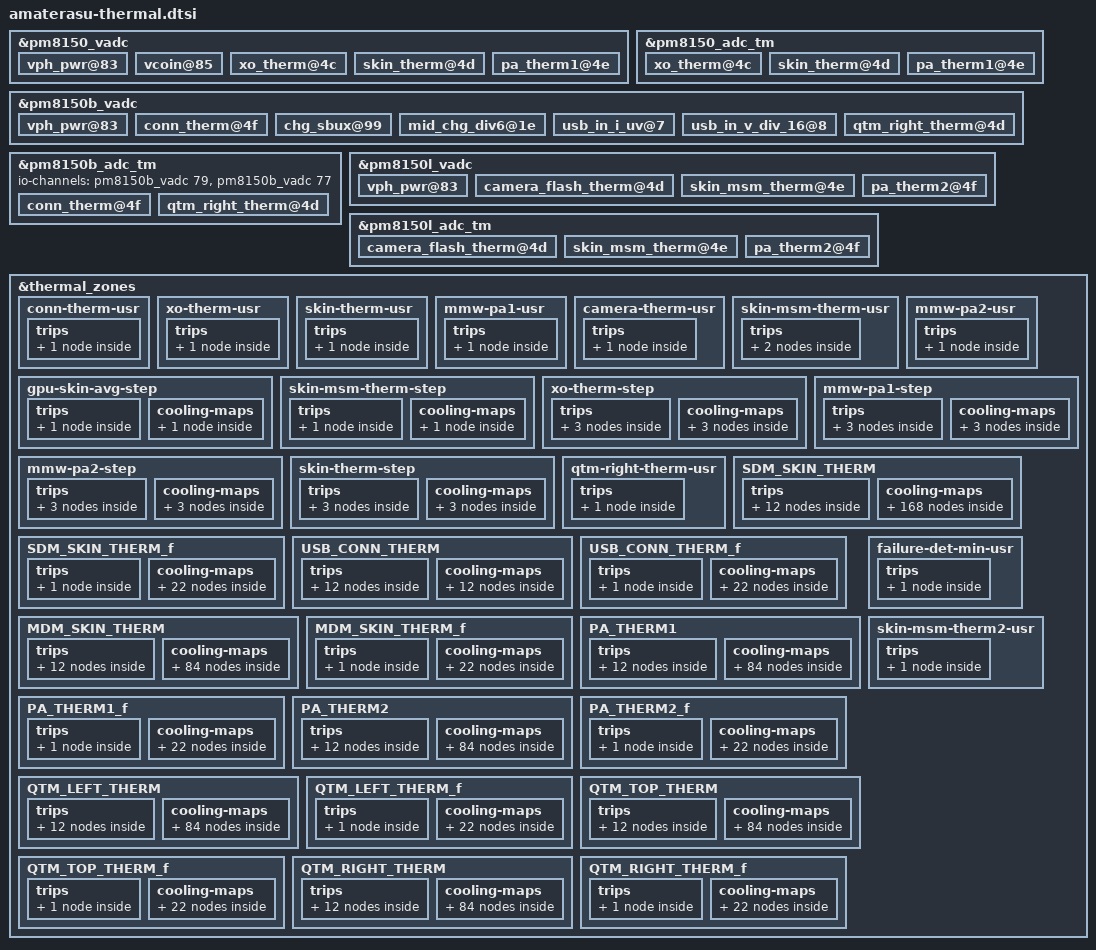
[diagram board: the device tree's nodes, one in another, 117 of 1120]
/*
 * FCNT arrows 5G (F-51A) - Thermal: ADC thermistor channels, FCNT thermal zones and mitigation.
 *
 * Reconstructed from the FCNT stock dtbo (kona FFRD REV7 SKU3); FFRD is
 * derived from the CLO kona QRD board files.
 */

&pm8150_vadc {
	vph_pwr@83 {
		reg = <0x83>;
		label = "vph_pwr";
		qcom,pre-scaling = <1 3>;
	};

	vcoin@85 {
		reg = <0x85>;
		label = "vcoin";
		qcom,pre-scaling = <1 3>;
	};

	xo_therm@4c {
		reg = <0x4c>;
		label = "xo_therm";
		qcom,ratiometric;
		qcom,hw-settle-time = <200>;
		qcom,pre-scaling = <1 1>;
	};

	skin_therm@4d {
		reg = <0x4d>;
		label = "skin_therm";
		qcom,ratiometric;
		qcom,hw-settle-time = <200>;
		qcom,pre-scaling = <1 1>;
	};

	pa_therm1@4e {
		reg = <0x4e>;
		label = "pa_therm1";
		qcom,ratiometric;
		qcom,hw-settle-time = <200>;
		qcom,pre-scaling = <1 1>;
	};
};

&pm8150_adc_tm {
	io-channels = <&pm8150_vadc 76 &pm8150_vadc 77 &pm8150_vadc 78>;

	xo_therm@4c {
		reg = <0x4c>;
		qcom,ratiometric;
		qcom,hw-settle-time = <200>;
	};

	skin_therm@4d {
		reg = <0x4d>;
		qcom,ratiometric;
		qcom,hw-settle-time = <200>;
	};

	pa_therm1@4e {
		reg = <0x4e>;
		qcom,ratiometric;
		qcom,hw-settle-time = <200>;
	};
};

&pm8150b_vadc {
	vph_pwr@83 {
		reg = <0x83>;
		label = "vph_pwr";
		qcom,pre-scaling = <1 3>;
	};

	conn_therm@4f {
		reg = <0x4f>;
		label = "conn_therm";
		qcom,ratiometric;
		qcom,hw-settle-time = <200>;
		qcom,pre-scaling = <1 1>;
	};

	chg_sbux@99 {
		reg = <0x99>;
		label = "chg_sbux";
		qcom,pre-scaling = <1 3>;
	};

	mid_chg_div6@1e {
		reg = <0x1e>;
		label = "chg_mid";
		qcom,pre-scaling = <1 6>;
	};

	usb_in_i_uv@7 {
		reg = <0x7>;
		label = "usb_in_i_uv";
		qcom,pre-scaling = <1 1>;
	};

	usb_in_v_div_16@8 {
		reg = <0x8>;
		label = "usb_in_v_div_16";
		qcom,pre-scaling = <1 16>;
	};

	qtm_right_therm@4d {
		reg = <0x4d>;
		label = "qtm_right_therm";
		qcom,ratiometric;
		qcom,hw-settle-time = <200>;
		qcom,pre-scaling = <1 1>;
	};
};

&pm8150b_adc_tm {
	io-channels = <&pm8150b_vadc 79 &pm8150b_vadc 77>;

	conn_therm@4f {
		reg = <0x4f>;
		qcom,ratiometric;
		qcom,hw-settle-time = <200>;
	};

	qtm_right_therm@4d {
		reg = <0x4d>;
		label = "qtm_right_therm";
		qcom,ratiometric;
		qcom,hw-settle-time = <200>;
	};
};

&pm8150l_vadc {
	vph_pwr@83 {
		reg = <0x83>;
		label = "vph_pwr";
		qcom,pre-scaling = <1 3>;
	};

	camera_flash_therm@4d {
		reg = <0x4d>;
		label = "camera_flash_therm";
		qcom,ratiometric;
		qcom,hw-settle-time = <200>;
		qcom,pre-scaling = <1 1>;
	};

	skin_msm_therm@4e {
		reg = <0x4e>;
		label = "skin_msm_therm";
		qcom,ratiometric;
		qcom,hw-settle-time = <200>;
		qcom,pre-scaling = <1 1>;
	};

	pa_therm2@4f {
		reg = <0x4f>;
		label = "pa_therm2";
		qcom,ratiometric;
		qcom,hw-settle-time = <200>;
		qcom,pre-scaling = <1 1>;
	};
};

&pm8150l_adc_tm {
	camera_flash_therm@4d {
		reg = <0x4d>;
		qcom,ratiometric;
		qcom,hw-settle-time = <200>;
	};

	skin_msm_therm@4e {
		reg = <0x4e>;
		qcom,ratiometric;
		qcom,hw-settle-time = <200>;
	};

	pa_therm2@4f {
		reg = <0x4f>;
		qcom,ratiometric;
		qcom,hw-settle-time = <200>;
	};
};

&thermal_zones {
	conn-therm-usr {
		polling-delay-passive = <0>;
		polling-delay = <0>;
		thermal-governor = "user_space";
		thermal-sensors = <&pm8150b_adc_tm 79>;
		wake-capable-sensor;

		trips {
			active-config0 {
				temperature = <125000>;
				hysteresis = <1000>;
				type = "passive";
			};
		};
	};

	xo-therm-usr {
		polling-delay-passive = <0>;
		polling-delay = <0>;
		thermal-governor = "user_space";
		thermal-sensors = <&pm8150_adc_tm 76>;
		wake-capable-sensor;

		trips {
			active-config0 {
				temperature = <125000>;
				hysteresis = <1000>;
				type = "passive";
			};
		};
	};

	skin-therm-usr {
		polling-delay-passive = <0>;
		polling-delay = <0>;
		thermal-governor = "user_space";
		thermal-sensors = <&pm8150_adc_tm 77>;
		wake-capable-sensor;

		trips {
			active-config0 {
				temperature = <125000>;
				hysteresis = <1000>;
				type = "passive";
			};
		};
	};

	mmw-pa1-usr {
		polling-delay-passive = <0>;
		polling-delay = <0>;
		thermal-governor = "user_space";
		thermal-sensors = <&pm8150_adc_tm 78>;
		wake-capable-sensor;

		trips {
			active-config0 {
				temperature = <125000>;
				hysteresis = <1000>;
				type = "passive";
			};
		};
	};

	camera-therm-usr {
		polling-delay-passive = <0>;
		polling-delay = <0>;
		thermal-governor = "user_space";
		thermal-sensors = <&pm8150l_adc_tm 77>;
		wake-capable-sensor;

		trips {
			active-config0 {
				temperature = <125000>;
				hysteresis = <1000>;
				type = "passive";
			};
		};
	};

	skin-msm-therm-usr {
		polling-delay-passive = <0>;
		polling-delay = <0>;
		thermal-governor = "user_space";
		thermal-sensors = <&pm8150l_adc_tm 78>;
		wake-capable-sensor;

		trips {
			active-config0 {
				temperature = <125000>;
				hysteresis = <1000>;
				type = "passive";
			};

			/* upstream a2dceb359e01: trip for the second userspace client */
			active-config1 {
				temperature = <125000>;
				hysteresis = <1000>;
				type = "passive";
			};
		};
	};

	mmw-pa2-usr {
		polling-delay-passive = <0>;
		polling-delay = <0>;
		thermal-governor = "user_space";
		thermal-sensors = <&pm8150l_adc_tm 79>;
		wake-capable-sensor;

		trips {
			active-config0 {
				temperature = <125000>;
				hysteresis = <1000>;
				type = "passive";
			};
		};
	};

	gpu-skin-avg-step {
		polling-delay-passive = <1000>;
		polling-delay = <5000>;
		thermal-governor = "step_wise";
		disable-thermal-zone;

		trips {
			virt_trip: virt-trip {
				temperature = <64600>;
				hysteresis = <2000>;
				type = "passive";
			};
		};

		cooling-maps {
			gpu_cdev {
				trip = <&virt_trip>;
				cooling-device = <&msm_gpu 0 1>;
			};
		};
	};

	skin-msm-therm-step {
		polling-delay-passive = <0>;
		polling-delay = <0>;
		thermal-governor = "step_wise";
		thermal-sensors = <&pm8150l_adc_tm 78>;
		wake-capable-sensor;
		disable-thermal-zone;

		trips {
			skin_trip: skin-config0 {
				temperature = <46000>;
				hysteresis = <0>;
				type = "passive";
			};
		};

		cooling-maps {
			lcd_cdev {
				trip = <&skin_trip>;
				cooling-device = <&mdss_mdp 153 153>;
			};
		};
	};

	xo-therm-step {
		polling-delay-passive = <0>;
		polling-delay = <0>;
		thermal-governor = "step_wise";
		thermal-sensors = <&pm8150_adc_tm 76>;
		disable-thermal-zone;

		trips {
			xo_lvl0: active-config0 {
				temperature = <42000>;
				hysteresis = <2000>;
				type = "passive";
			};

			xo_lvl1: active-config1 {
				temperature = <46000>;
				hysteresis = <2000>;
				type = "passive";
			};

			xo_lvl2: active-config2 {
				temperature = <56000>;
				hysteresis = <6000>;
				type = "passive";
			};
		};

		cooling-maps {
			xo_skin_lvl0 {
				trip = <&xo_lvl0>;
				cooling-device = <&modem_mmw_skin2 1 1>;
			};

			xo_skin_lvl1 {
				trip = <&xo_lvl1>;
				cooling-device = <&modem_mmw_skin2 2 2>;
			};

			xo_skin_lvl2 {
				trip = <&xo_lvl2>;
				cooling-device = <&modem_mmw_skin2 3 3>;
			};
		};
	};

	mmw-pa1-step {
		polling-delay-passive = <0>;
		polling-delay = <0>;
		thermal-governor = "step_wise";
		thermal-sensors = <&pm8150_adc_tm 78>;
		disable-thermal-zone;

		trips {
			pa1_lvl0: active-config0 {
				temperature = <44000>;
				hysteresis = <5000>;
				type = "passive";
			};

			pa1_lvl1: active-config1 {
				temperature = <48000>;
				hysteresis = <2000>;
				type = "passive";
			};

			pa1_lvl2: active-config2 {
				temperature = <56000>;
				hysteresis = <6000>;
				type = "passive";
			};
		};

		cooling-maps {
			pa1_skin_lvl0 {
				trip = <&pa1_lvl0>;
				cooling-device = <&modem_mmw_skin0 1 1>;
			};

			pa1_skin_lvl1 {
				trip = <&pa1_lvl1>;
				cooling-device = <&modem_mmw_skin0 2 2>;
			};

			pa1_skin_lvl2 {
				trip = <&pa1_lvl2>;
				cooling-device = <&modem_mmw_skin0 3 3>;
			};
		};
	};

	mmw-pa2-step {
		polling-delay-passive = <0>;
		polling-delay = <0>;
		thermal-governor = "step_wise";
		thermal-sensors = <&pm8150l_adc_tm 79>;
		disable-thermal-zone;

		trips {
			pa2_lvl0: active-config0 {
				temperature = <42000>;
				hysteresis = <4000>;
				type = "passive";
			};

			pa2_lvl1: active-config1 {
				temperature = <46000>;
				hysteresis = <2000>;
				type = "passive";
			};

			pa2_lvl2: active-config2 {
				temperature = <56000>;
				hysteresis = <6000>;
				type = "passive";
			};
		};

		cooling-maps {
			pa2_skin_lvl0 {
				trip = <&pa2_lvl0>;
				cooling-device = <&modem_mmw_skin1 1 1>;
			};

			pa2_skin_lvl1 {
				trip = <&pa2_lvl1>;
				cooling-device = <&modem_mmw_skin1 2 2>;
			};

			pa2_skin_lvl2 {
				trip = <&pa2_lvl2>;
				cooling-device = <&modem_mmw_skin1 3 3>;
			};
		};
	};

	skin-therm-step {
		polling-delay-passive = <0>;
		polling-delay = <0>;
		thermal-governor = "step_wise";
		thermal-sensors = <&pm8150_adc_tm 77>;
		wake-capable-sensor;
		disable-thermal-zone;

		trips {
			skin_therm0: active-config0 {
				temperature = <52000>;
				hysteresis = <5000>;
				type = "passive";
			};

			skin_therm1: active-config1 {
				temperature = <55000>;
				hysteresis = <5000>;
				type = "passive";
			};

			skin_therm2: active-config2 {
				temperature = <62000>;
				hysteresis = <2000>;
				type = "passive";
			};
		};

		cooling-maps {
			skin_lvl0 {
				trip = <&skin_therm0>;
				cooling-device = <&modem_skin 1 1>;
			};

			skin_lvl1 {
				trip = <&skin_therm1>;
				cooling-device = <&modem_skin 2 2>;
			};

			skin_lvl2 {
				trip = <&skin_therm2>;
				cooling-device = <&modem_skin 3 3>;
			};
		};
	};

	qtm-right-therm-usr {
		polling-delay-passive = <0>;
		polling-delay = <0>;
		thermal-governor = "user_space";
		thermal-sensors = <&pm8150b_adc_tm 77>;

		trips {
			active-config0 {
				temperature = <125000>;
				hysteresis = <1000>;
				type = "passive";
			};
		};
	};

	SDM_SKIN_THERM {
		polling-delay-passive = <1000>;
		polling-delay = <0>;
		thermal-governor = "step_wise";
		thermal-sensors = <&pm8150l_adc_tm 78>;
		wake-capable-sensor;

		trips {
			SDM_SKIN_THERM_trip_point0: SDM_SKIN_THERM_trip0 {
				temperature = <40000>;
				hysteresis = <1000>;
				type = "passive";
			};

			SDM_SKIN_THERM_trip_point1: SDM_SKIN_THERM_trip1 {
				temperature = <43000>;
				hysteresis = <1000>;
				type = "passive";
			};

			SDM_SKIN_THERM_trip_point2: SDM_SKIN_THERM_trip2 {
				temperature = <45000>;
				hysteresis = <1000>;
				type = "passive";
			};

			SDM_SKIN_THERM_trip_point3: SDM_SKIN_THERM_trip3 {
				temperature = <47000>;
				hysteresis = <1000>;
				type = "passive";
			};

			SDM_SKIN_THERM_trip_point4: SDM_SKIN_THERM_trip4 {
				temperature = <50000>;
				hysteresis = <1000>;
				type = "passive";
			};

			SDM_SKIN_THERM_trip_point5: SDM_SKIN_THERM_trip5 {
				temperature = <53000>;
				hysteresis = <1000>;
				type = "passive";
			};

			SDM_SKIN_THERM_trip_point6: SDM_SKIN_THERM_trip6 {
				temperature = <55000>;
				hysteresis = <1000>;
				type = "passive";
			};

			SDM_SKIN_THERM_trip_point7: SDM_SKIN_THERM_trip7 {
				temperature = <56000>;
				hysteresis = <1000>;
				type = "passive";
			};

			SDM_SKIN_THERM_trip_point8: SDM_SKIN_THERM_trip8 {
				temperature = <58000>;
				hysteresis = <1000>;
				type = "passive";
			};

			SDM_SKIN_THERM_trip_point9: SDM_SKIN_THERM_trip9 {
				temperature = <59000>;
				hysteresis = <1000>;
				type = "passive";
			};

			SDM_SKIN_THERM_trip_point10: SDM_SKIN_THERM_trip10 {
				temperature = <60000>;
				hysteresis = <1000>;
				type = "passive";
			};

			SDM_SKIN_THERM_trip_point11: SDM_SKIN_THERM_trip11 {
				temperature = <60000>;
				hysteresis = <1000>;
				type = "passive";
			};
		};

		cooling-maps {
			SDM_SKIN_THERM_cpu0_freq_trip0 {
				trip = <&SDM_SKIN_THERM_trip_point0>;
				cooling-device = <&CPU0 (-1) 0>;
			};

			SDM_SKIN_THERM_cpu4_freq_trip0 {
				trip = <&SDM_SKIN_THERM_trip_point0>;
				cooling-device = <&CPU4 (-1) 0>;
			};

			SDM_SKIN_THERM_cpu7_freq_trip0 {
				trip = <&SDM_SKIN_THERM_trip_point0>;
				cooling-device = <&CPU7 (-1) 10>;
			};

			SDM_SKIN_THERM_cpu0_isolate_trip0 {
				trip = <&SDM_SKIN_THERM_trip_point0>;
				cooling-device = <&cpu0_isolate 0 0>;
			};

			SDM_SKIN_THERM_cpu1_isolate_trip0 {
				trip = <&SDM_SKIN_THERM_trip_point0>;
				cooling-device = <&cpu1_isolate 0 0>;
			};

			SDM_SKIN_THERM_cpu2_isolate_trip0 {
				trip = <&SDM_SKIN_THERM_trip_point0>;
				cooling-device = <&cpu2_isolate 0 0>;
			};

			SDM_SKIN_THERM_cpu3_isolate_trip0 {
				trip = <&SDM_SKIN_THERM_trip_point0>;
				cooling-device = <&cpu3_isolate 0 0>;
			};

			SDM_SKIN_THERM_cpu4_isolate_trip0 {
				trip = <&SDM_SKIN_THERM_trip_point0>;
				cooling-device = <&cpu4_isolate 0 0>;
			};

			SDM_SKIN_THERM_cpu5_isolate_trip0 {
				trip = <&SDM_SKIN_THERM_trip_point0>;
				cooling-device = <&cpu5_isolate 0 0>;
			};

			SDM_SKIN_THERM_cpu6_isolate_trip0 {
				trip = <&SDM_SKIN_THERM_trip_point0>;
				cooling-device = <&cpu6_isolate 0 0>;
			};

			SDM_SKIN_THERM_cpu7_isolate_trip0 {
				trip = <&SDM_SKIN_THERM_trip_point0>;
				cooling-device = <&cpu7_isolate 0 0>;
			};

			SDM_SKIN_THERM_gpu_freq_trip0 {
				trip = <&SDM_SKIN_THERM_trip_point0>;
				cooling-device = <&msm_gpu 0 0>;
			};

			SDM_SKIN_THERM_backlight_trip0 {
				trip = <&SDM_SKIN_THERM_trip_point0>;
				cooling-device = <&mdss_mdp 0 0>;
			};

			SDM_SKIN_THERM_oem_chg_trip0 {
				trip = <&SDM_SKIN_THERM_trip_point0>;
				cooling-device = <&oem_charger_drv 0 0>;
			};

			SDM_SKIN_THERM_cpu0_freq_trip1 {
				trip = <&SDM_SKIN_THERM_trip_point1>;
				cooling-device = <&CPU0 (-1) 0>;
			};

			SDM_SKIN_THERM_cpu4_freq_trip1 {
				trip = <&SDM_SKIN_THERM_trip_point1>;
				cooling-device = <&CPU4 (-1) 0>;
			};

			SDM_SKIN_THERM_cpu7_freq_trip1 {
				trip = <&SDM_SKIN_THERM_trip_point1>;
				cooling-device = <&CPU7 (-1) 19>;
			};

			SDM_SKIN_THERM_cpu0_isolate_trip1 {
				trip = <&SDM_SKIN_THERM_trip_point1>;
				cooling-device = <&cpu0_isolate 0 0>;
			};

			SDM_SKIN_THERM_cpu1_isolate_trip1 {
				trip = <&SDM_SKIN_THERM_trip_point1>;
				cooling-device = <&cpu1_isolate 0 0>;
			};

			SDM_SKIN_THERM_cpu2_isolate_trip1 {
				trip = <&SDM_SKIN_THERM_trip_point1>;
				cooling-device = <&cpu2_isolate 0 0>;
			};

			SDM_SKIN_THERM_cpu3_isolate_trip1 {
				trip = <&SDM_SKIN_THERM_trip_point1>;
				cooling-device = <&cpu3_isolate 0 0>;
			};

			SDM_SKIN_THERM_cpu4_isolate_trip1 {
				trip = <&SDM_SKIN_THERM_trip_point1>;
				cooling-device = <&cpu4_isolate 0 0>;
			};

			SDM_SKIN_THERM_cpu5_isolate_trip1 {
				trip = <&SDM_SKIN_THERM_trip_point1>;
				cooling-device = <&cpu5_isolate 0 0>;
			};

			SDM_SKIN_THERM_cpu6_isolate_trip1 {
				trip = <&SDM_SKIN_THERM_trip_point1>;
				cooling-device = <&cpu6_isolate 0 0>;
			};

			SDM_SKIN_THERM_cpu7_isolate_trip1 {
				trip = <&SDM_SKIN_THERM_trip_point1>;
				cooling-device = <&cpu7_isolate 0 0>;
			};

			SDM_SKIN_THERM_gpu_freq_trip1 {
				trip = <&SDM_SKIN_THERM_trip_point1>;
				cooling-device = <&msm_gpu 0 0>;
			};

			SDM_SKIN_THERM_backlight_trip1 {
				trip = <&SDM_SKIN_THERM_trip_point1>;
				cooling-device = <&mdss_mdp 0 0>;
			};

			SDM_SKIN_THERM_oem_chg_trip1 {
				trip = <&SDM_SKIN_THERM_trip_point1>;
				cooling-device = <&oem_charger_drv 0 0>;
			};

			SDM_SKIN_THERM_cpu0_freq_trip2 {
				trip = <&SDM_SKIN_THERM_trip_point2>;
				cooling-device = <&CPU0 (-1) 0>;
			};

			SDM_SKIN_THERM_cpu4_freq_trip2 {
				trip = <&SDM_SKIN_THERM_trip_point2>;
				cooling-device = <&CPU4 (-1) 1>;
			};

			SDM_SKIN_THERM_cpu7_freq_trip2 {
				trip = <&SDM_SKIN_THERM_trip_point2>;
				cooling-device = <&CPU7 (-1) 19>;
			};

			SDM_SKIN_THERM_cpu0_isolate_trip2 {
				trip = <&SDM_SKIN_THERM_trip_point2>;
				cooling-device = <&cpu0_isolate 0 0>;
			};

			SDM_SKIN_THERM_cpu1_isolate_trip2 {
				trip = <&SDM_SKIN_THERM_trip_point2>;
				cooling-device = <&cpu1_isolate 0 0>;
			};

			SDM_SKIN_THERM_cpu2_isolate_trip2 {
				trip = <&SDM_SKIN_THERM_trip_point2>;
				cooling-device = <&cpu2_isolate 0 0>;
			};

			SDM_SKIN_THERM_cpu3_isolate_trip2 {
				trip = <&SDM_SKIN_THERM_trip_point2>;
				cooling-device = <&cpu3_isolate 0 0>;
			};

			SDM_SKIN_THERM_cpu4_isolate_trip2 {
				trip = <&SDM_SKIN_THERM_trip_point2>;
				cooling-device = <&cpu4_isolate 0 0>;
			};

			SDM_SKIN_THERM_cpu5_isolate_trip2 {
				trip = <&SDM_SKIN_THERM_trip_point2>;
				cooling-device = <&cpu5_isolate 0 0>;
			};

			SDM_SKIN_THERM_cpu6_isolate_trip2 {
				trip = <&SDM_SKIN_THERM_trip_point2>;
				cooling-device = <&cpu6_isolate 0 0>;
			};

			SDM_SKIN_THERM_cpu7_isolate_trip2 {
				trip = <&SDM_SKIN_THERM_trip_point2>;
				cooling-device = <&cpu7_isolate 1 1>;
			};

			SDM_SKIN_THERM_gpu_freq_trip2 {
				trip = <&SDM_SKIN_THERM_trip_point2>;
				cooling-device = <&msm_gpu 0 0>;
			};

			SDM_SKIN_THERM_backlight_trip2 {
				trip = <&SDM_SKIN_THERM_trip_point2>;
				cooling-device = <&mdss_mdp 0 0>;
			};

			SDM_SKIN_THERM_oem_chg_trip2 {
				trip = <&SDM_SKIN_THERM_trip_point2>;
				cooling-device = <&oem_charger_drv 1 1>;
			};

			SDM_SKIN_THERM_cpu0_freq_trip3 {
				trip = <&SDM_SKIN_THERM_trip_point3>;
				cooling-device = <&CPU0 (-1) 0>;
			};

			SDM_SKIN_THERM_cpu4_freq_trip3 {
				trip = <&SDM_SKIN_THERM_trip_point3>;
				cooling-device = <&CPU4 (-1) 5>;
			};

			SDM_SKIN_THERM_cpu7_freq_trip3 {
				trip = <&SDM_SKIN_THERM_trip_point3>;
				cooling-device = <&CPU7 (-1) 19>;
			};

			SDM_SKIN_THERM_cpu0_isolate_trip3 {
				trip = <&SDM_SKIN_THERM_trip_point3>;
				cooling-device = <&cpu0_isolate 0 0>;
			};

			SDM_SKIN_THERM_cpu1_isolate_trip3 {
				trip = <&SDM_SKIN_THERM_trip_point3>;
				cooling-device = <&cpu1_isolate 0 0>;
			};

			SDM_SKIN_THERM_cpu2_isolate_trip3 {
				trip = <&SDM_SKIN_THERM_trip_point3>;
				cooling-device = <&cpu2_isolate 0 0>;
			};

			SDM_SKIN_THERM_cpu3_isolate_trip3 {
				trip = <&SDM_SKIN_THERM_trip_point3>;
				cooling-device = <&cpu3_isolate 0 0>;
			};

			SDM_SKIN_THERM_cpu4_isolate_trip3 {
				trip = <&SDM_SKIN_THERM_trip_point3>;
				cooling-device = <&cpu4_isolate 0 0>;
			};

			SDM_SKIN_THERM_cpu5_isolate_trip3 {
				trip = <&SDM_SKIN_THERM_trip_point3>;
				cooling-device = <&cpu5_isolate 0 0>;
			};

			SDM_SKIN_THERM_cpu6_isolate_trip3 {
				trip = <&SDM_SKIN_THERM_trip_point3>;
				cooling-device = <&cpu6_isolate 0 0>;
			};

			SDM_SKIN_THERM_cpu7_isolate_trip3 {
				trip = <&SDM_SKIN_THERM_trip_point3>;
				cooling-device = <&cpu7_isolate 1 1>;
			};

			SDM_SKIN_THERM_gpu_freq_trip3 {
				trip = <&SDM_SKIN_THERM_trip_point3>;
				cooling-device = <&msm_gpu 0 0>;
			};

			SDM_SKIN_THERM_backlight_trip3 {
				trip = <&SDM_SKIN_THERM_trip_point3>;
				cooling-device = <&mdss_mdp 0 0>;
			};

			SDM_SKIN_THERM_oem_chg_trip3 {
				trip = <&SDM_SKIN_THERM_trip_point3>;
				cooling-device = <&oem_charger_drv 1 1>;
			};

			SDM_SKIN_THERM_cpu0_freq_trip4 {
				trip = <&SDM_SKIN_THERM_trip_point4>;
				cooling-device = <&CPU0 (-1) 0>;
			};

			SDM_SKIN_THERM_cpu4_freq_trip4 {
				trip = <&SDM_SKIN_THERM_trip_point4>;
				cooling-device = <&CPU4 (-1) 9>;
			};

			SDM_SKIN_THERM_cpu7_freq_trip4 {
				trip = <&SDM_SKIN_THERM_trip_point4>;
				cooling-device = <&CPU7 (-1) 19>;
			};

			SDM_SKIN_THERM_cpu0_isolate_trip4 {
				trip = <&SDM_SKIN_THERM_trip_point4>;
				cooling-device = <&cpu0_isolate 0 0>;
			};

			SDM_SKIN_THERM_cpu1_isolate_trip4 {
				trip = <&SDM_SKIN_THERM_trip_point4>;
				cooling-device = <&cpu1_isolate 0 0>;
			};

			SDM_SKIN_THERM_cpu2_isolate_trip4 {
				trip = <&SDM_SKIN_THERM_trip_point4>;
				cooling-device = <&cpu2_isolate 0 0>;
			};

			SDM_SKIN_THERM_cpu3_isolate_trip4 {
				trip = <&SDM_SKIN_THERM_trip_point4>;
				cooling-device = <&cpu3_isolate 0 0>;
			};

			SDM_SKIN_THERM_cpu4_isolate_trip4 {
				trip = <&SDM_SKIN_THERM_trip_point4>;
				cooling-device = <&cpu4_isolate 0 0>;
			};

			SDM_SKIN_THERM_cpu5_isolate_trip4 {
				trip = <&SDM_SKIN_THERM_trip_point4>;
				cooling-device = <&cpu5_isolate 0 0>;
			};

			SDM_SKIN_THERM_cpu6_isolate_trip4 {
				trip = <&SDM_SKIN_THERM_trip_point4>;
				cooling-device = <&cpu6_isolate 0 0>;
			};

			SDM_SKIN_THERM_cpu7_isolate_trip4 {
				trip = <&SDM_SKIN_THERM_trip_point4>;
				cooling-device = <&cpu7_isolate 1 1>;
			};

			SDM_SKIN_THERM_gpu_freq_trip4 {
				trip = <&SDM_SKIN_THERM_trip_point4>;
				cooling-device = <&msm_gpu 2 2>;
			};

			SDM_SKIN_THERM_backlight_trip4 {
				trip = <&SDM_SKIN_THERM_trip_point4>;
				cooling-device = <&mdss_mdp 0 0>;
			};

			SDM_SKIN_THERM_oem_chg_trip4 {
				trip = <&SDM_SKIN_THERM_trip_point4>;
				cooling-device = <&oem_charger_drv 2 2>;
			};

			SDM_SKIN_THERM_cpu0_freq_trip5 {
				trip = <&SDM_SKIN_THERM_trip_point5>;
				cooling-device = <&CPU0 (-1) 0>;
			};

			SDM_SKIN_THERM_cpu4_freq_trip5 {
				trip = <&SDM_SKIN_THERM_trip_point5>;
				cooling-device = <&CPU4 (-1) 12>;
			};

			SDM_SKIN_THERM_cpu7_freq_trip5 {
				trip = <&SDM_SKIN_THERM_trip_point5>;
				cooling-device = <&CPU7 (-1) 19>;
			};

			SDM_SKIN_THERM_cpu0_isolate_trip5 {
				trip = <&SDM_SKIN_THERM_trip_point5>;
				cooling-device = <&cpu0_isolate 0 0>;
			};

			SDM_SKIN_THERM_cpu1_isolate_trip5 {
				trip = <&SDM_SKIN_THERM_trip_point5>;
				cooling-device = <&cpu1_isolate 0 0>;
			};

			SDM_SKIN_THERM_cpu2_isolate_trip5 {
				trip = <&SDM_SKIN_THERM_trip_point5>;
				cooling-device = <&cpu2_isolate 0 0>;
			};

			SDM_SKIN_THERM_cpu3_isolate_trip5 {
				trip = <&SDM_SKIN_THERM_trip_point5>;
				cooling-device = <&cpu3_isolate 0 0>;
			};

			SDM_SKIN_THERM_cpu4_isolate_trip5 {
				trip = <&SDM_SKIN_THERM_trip_point5>;
				cooling-device = <&cpu4_isolate 0 0>;
			};

			SDM_SKIN_THERM_cpu5_isolate_trip5 {
				trip = <&SDM_SKIN_THERM_trip_point5>;
				cooling-device = <&cpu5_isolate 0 0>;
			};

			SDM_SKIN_THERM_cpu6_isolate_trip5 {
				trip = <&SDM_SKIN_THERM_trip_point5>;
				cooling-device = <&cpu6_isolate 0 0>;
			};

			SDM_SKIN_THERM_cpu7_isolate_trip5 {
				trip = <&SDM_SKIN_THERM_trip_point5>;
				cooling-device = <&cpu7_isolate 1 1>;
			};

			SDM_SKIN_THERM_gpu_freq_trip5 {
				trip = <&SDM_SKIN_THERM_trip_point5>;
				cooling-device = <&msm_gpu 2 2>;
			};

			SDM_SKIN_THERM_backlight_trip5 {
				trip = <&SDM_SKIN_THERM_trip_point5>;
				cooling-device = <&mdss_mdp 0 0>;
			};

			SDM_SKIN_THERM_oem_chg_trip5 {
				trip = <&SDM_SKIN_THERM_trip_point5>;
				cooling-device = <&oem_charger_drv 2 2>;
			};

			SDM_SKIN_THERM_cpu0_freq_trip6 {
				trip = <&SDM_SKIN_THERM_trip_point6>;
				cooling-device = <&CPU0 (-1) 0>;
			};

			SDM_SKIN_THERM_cpu4_freq_trip6 {
				trip = <&SDM_SKIN_THERM_trip_point6>;
				cooling-device = <&CPU4 (-1) 16>;
			};

			SDM_SKIN_THERM_cpu7_freq_trip6 {
				trip = <&SDM_SKIN_THERM_trip_point6>;
				cooling-device = <&CPU7 (-1) 19>;
			};

			SDM_SKIN_THERM_cpu0_isolate_trip6 {
				trip = <&SDM_SKIN_THERM_trip_point6>;
				cooling-device = <&cpu0_isolate 0 0>;
			};

			SDM_SKIN_THERM_cpu1_isolate_trip6 {
				trip = <&SDM_SKIN_THERM_trip_point6>;
				cooling-device = <&cpu1_isolate 0 0>;
			};

			SDM_SKIN_THERM_cpu2_isolate_trip6 {
				trip = <&SDM_SKIN_THERM_trip_point6>;
				cooling-device = <&cpu2_isolate 0 0>;
			};

			SDM_SKIN_THERM_cpu3_isolate_trip6 {
				trip = <&SDM_SKIN_THERM_trip_point6>;
				cooling-device = <&cpu3_isolate 0 0>;
			};

			SDM_SKIN_THERM_cpu4_isolate_trip6 {
				trip = <&SDM_SKIN_THERM_trip_point6>;
				cooling-device = <&cpu4_isolate 0 0>;
			};

			SDM_SKIN_THERM_cpu5_isolate_trip6 {
				trip = <&SDM_SKIN_THERM_trip_point6>;
				cooling-device = <&cpu5_isolate 0 0>;
			};

			SDM_SKIN_THERM_cpu6_isolate_trip6 {
				trip = <&SDM_SKIN_THERM_trip_point6>;
				cooling-device = <&cpu6_isolate 0 0>;
			};

			SDM_SKIN_THERM_cpu7_isolate_trip6 {
				trip = <&SDM_SKIN_THERM_trip_point6>;
				cooling-device = <&cpu7_isolate 1 1>;
			};

			SDM_SKIN_THERM_gpu_freq_trip6 {
				trip = <&SDM_SKIN_THERM_trip_point6>;
				cooling-device = <&msm_gpu 2 2>;
			};

			SDM_SKIN_THERM_backlight_trip6 {
				trip = <&SDM_SKIN_THERM_trip_point6>;
				cooling-device = <&mdss_mdp 0 0>;
			};

			SDM_SKIN_THERM_oem_chg_trip6 {
				trip = <&SDM_SKIN_THERM_trip_point6>;
				cooling-device = <&oem_charger_drv 3 3>;
			};

			SDM_SKIN_THERM_cpu0_freq_trip7 {
				trip = <&SDM_SKIN_THERM_trip_point7>;
				cooling-device = <&CPU0 (-1) 0>;
			};

			SDM_SKIN_THERM_cpu4_freq_trip7 {
				trip = <&SDM_SKIN_THERM_trip_point7>;
				cooling-device = <&CPU4 (-1) 16>;
			};

			SDM_SKIN_THERM_cpu7_freq_trip7 {
				trip = <&SDM_SKIN_THERM_trip_point7>;
				cooling-device = <&CPU7 (-1) 19>;
			};

			SDM_SKIN_THERM_cpu0_isolate_trip7 {
				trip = <&SDM_SKIN_THERM_trip_point7>;
				cooling-device = <&cpu0_isolate 0 0>;
			};

			SDM_SKIN_THERM_cpu1_isolate_trip7 {
				trip = <&SDM_SKIN_THERM_trip_point7>;
				cooling-device = <&cpu1_isolate 0 0>;
			};

			SDM_SKIN_THERM_cpu2_isolate_trip7 {
				trip = <&SDM_SKIN_THERM_trip_point7>;
				cooling-device = <&cpu2_isolate 0 0>;
			};

			SDM_SKIN_THERM_cpu3_isolate_trip7 {
				trip = <&SDM_SKIN_THERM_trip_point7>;
				cooling-device = <&cpu3_isolate 0 0>;
			};

			SDM_SKIN_THERM_cpu4_isolate_trip7 {
				trip = <&SDM_SKIN_THERM_trip_point7>;
				cooling-device = <&cpu4_isolate 0 0>;
			};

			SDM_SKIN_THERM_cpu5_isolate_trip7 {
				trip = <&SDM_SKIN_THERM_trip_point7>;
				cooling-device = <&cpu5_isolate 1 1>;
			};

			SDM_SKIN_THERM_cpu6_isolate_trip7 {
				trip = <&SDM_SKIN_THERM_trip_point7>;
				cooling-device = <&cpu6_isolate 1 1>;
			};

			SDM_SKIN_THERM_cpu7_isolate_trip7 {
				trip = <&SDM_SKIN_THERM_trip_point7>;
				cooling-device = <&cpu7_isolate 1 1>;
			};

			SDM_SKIN_THERM_gpu_freq_trip7 {
				trip = <&SDM_SKIN_THERM_trip_point7>;
				cooling-device = <&msm_gpu 2 2>;
			};

			SDM_SKIN_THERM_backlight_trip7 {
				trip = <&SDM_SKIN_THERM_trip_point7>;
				cooling-device = <&mdss_mdp 0 0>;
			};

			SDM_SKIN_THERM_oem_chg_trip7 {
				trip = <&SDM_SKIN_THERM_trip_point7>;
				cooling-device = <&oem_charger_drv 3 3>;
			};

			SDM_SKIN_THERM_cpu0_freq_trip8 {
				trip = <&SDM_SKIN_THERM_trip_point8>;
				cooling-device = <&CPU0 (-1) 0>;
			};

			SDM_SKIN_THERM_cpu4_freq_trip8 {
				trip = <&SDM_SKIN_THERM_trip_point8>;
				cooling-device = <&CPU4 (-1) 16>;
			};

			SDM_SKIN_THERM_cpu7_freq_trip8 {
				trip = <&SDM_SKIN_THERM_trip_point8>;
				cooling-device = <&CPU7 (-1) 19>;
			};

			SDM_SKIN_THERM_cpu0_isolate_trip8 {
				trip = <&SDM_SKIN_THERM_trip_point8>;
				cooling-device = <&cpu0_isolate 0 0>;
			};

			SDM_SKIN_THERM_cpu1_isolate_trip8 {
				trip = <&SDM_SKIN_THERM_trip_point8>;
				cooling-device = <&cpu1_isolate 0 0>;
			};

			SDM_SKIN_THERM_cpu2_isolate_trip8 {
				trip = <&SDM_SKIN_THERM_trip_point8>;
				cooling-device = <&cpu2_isolate 0 0>;
			};

			SDM_SKIN_THERM_cpu3_isolate_trip8 {
				trip = <&SDM_SKIN_THERM_trip_point8>;
				cooling-device = <&cpu3_isolate 0 0>;
			};

			SDM_SKIN_THERM_cpu4_isolate_trip8 {
				trip = <&SDM_SKIN_THERM_trip_point8>;
				cooling-device = <&cpu4_isolate 1 1>;
			};

			SDM_SKIN_THERM_cpu5_isolate_trip8 {
				trip = <&SDM_SKIN_THERM_trip_point8>;
				cooling-device = <&cpu5_isolate 1 1>;
			};

			SDM_SKIN_THERM_cpu6_isolate_trip8 {
				trip = <&SDM_SKIN_THERM_trip_point8>;
				cooling-device = <&cpu6_isolate 1 1>;
			};

			SDM_SKIN_THERM_cpu7_isolate_trip8 {
				trip = <&SDM_SKIN_THERM_trip_point8>;
				cooling-device = <&cpu7_isolate 1 1>;
			};

			SDM_SKIN_THERM_gpu_freq_trip8 {
				trip = <&SDM_SKIN_THERM_trip_point8>;
				cooling-device = <&msm_gpu 4 4>;
			};

			SDM_SKIN_THERM_backlight_trip8 {
				trip = <&SDM_SKIN_THERM_trip_point8>;
				cooling-device = <&mdss_mdp 0 0>;
			};

			SDM_SKIN_THERM_oem_chg_trip8 {
				trip = <&SDM_SKIN_THERM_trip_point8>;
				cooling-device = <&oem_charger_drv 3 3>;
			};

			SDM_SKIN_THERM_cpu0_freq_trip9 {
				trip = <&SDM_SKIN_THERM_trip_point9>;
				cooling-device = <&CPU0 (-1) 8>;
			};

			SDM_SKIN_THERM_cpu4_freq_trip9 {
				trip = <&SDM_SKIN_THERM_trip_point9>;
				cooling-device = <&CPU4 (-1) 16>;
			};

			SDM_SKIN_THERM_cpu7_freq_trip9 {
				trip = <&SDM_SKIN_THERM_trip_point9>;
				cooling-device = <&CPU7 (-1) 19>;
			};

			SDM_SKIN_THERM_cpu0_isolate_trip9 {
				trip = <&SDM_SKIN_THERM_trip_point9>;
				cooling-device = <&cpu0_isolate 0 0>;
			};

			SDM_SKIN_THERM_cpu1_isolate_trip9 {
				trip = <&SDM_SKIN_THERM_trip_point9>;
				cooling-device = <&cpu1_isolate 0 0>;
			};

			SDM_SKIN_THERM_cpu2_isolate_trip9 {
				trip = <&SDM_SKIN_THERM_trip_point9>;
				cooling-device = <&cpu2_isolate 0 0>;
			};

			SDM_SKIN_THERM_cpu3_isolate_trip9 {
				trip = <&SDM_SKIN_THERM_trip_point9>;
				cooling-device = <&cpu3_isolate 0 0>;
			};

			SDM_SKIN_THERM_cpu4_isolate_trip9 {
				trip = <&SDM_SKIN_THERM_trip_point9>;
				cooling-device = <&cpu4_isolate 1 1>;
			};

			SDM_SKIN_THERM_cpu5_isolate_trip9 {
				trip = <&SDM_SKIN_THERM_trip_point9>;
				cooling-device = <&cpu5_isolate 1 1>;
			};

			SDM_SKIN_THERM_cpu6_isolate_trip9 {
				trip = <&SDM_SKIN_THERM_trip_point9>;
				cooling-device = <&cpu6_isolate 1 1>;
			};

			SDM_SKIN_THERM_cpu7_isolate_trip9 {
				trip = <&SDM_SKIN_THERM_trip_point9>;
				cooling-device = <&cpu7_isolate 1 1>;
			};

			SDM_SKIN_THERM_gpu_freq_trip9 {
				trip = <&SDM_SKIN_THERM_trip_point9>;
				cooling-device = <&msm_gpu 5 5>;
			};

			SDM_SKIN_THERM_backlight_trip9 {
				trip = <&SDM_SKIN_THERM_trip_point9>;
				cooling-device = <&mdss_mdp 0 0>;
			};

			SDM_SKIN_THERM_oem_chg_trip9 {
				trip = <&SDM_SKIN_THERM_trip_point9>;
				cooling-device = <&oem_charger_drv 3 3>;
			};

			SDM_SKIN_THERM_cpu0_freq_trip10 {
				trip = <&SDM_SKIN_THERM_trip_point10>;
				cooling-device = <&CPU0 (-1) 8>;
			};

			SDM_SKIN_THERM_cpu4_freq_trip10 {
				trip = <&SDM_SKIN_THERM_trip_point10>;
				cooling-device = <&CPU4 (-1) 16>;
			};

			SDM_SKIN_THERM_cpu7_freq_trip10 {
				trip = <&SDM_SKIN_THERM_trip_point10>;
				cooling-device = <&CPU7 (-1) 19>;
			};

			SDM_SKIN_THERM_cpu0_isolate_trip10 {
				trip = <&SDM_SKIN_THERM_trip_point10>;
				cooling-device = <&cpu0_isolate 0 0>;
			};

			SDM_SKIN_THERM_cpu1_isolate_trip10 {
				trip = <&SDM_SKIN_THERM_trip_point10>;
				cooling-device = <&cpu1_isolate 0 0>;
			};

			SDM_SKIN_THERM_cpu2_isolate_trip10 {
				trip = <&SDM_SKIN_THERM_trip_point10>;
				cooling-device = <&cpu2_isolate 0 0>;
			};

			SDM_SKIN_THERM_cpu3_isolate_trip10 {
				trip = <&SDM_SKIN_THERM_trip_point10>;
				cooling-device = <&cpu3_isolate 0 0>;
			};

			SDM_SKIN_THERM_cpu4_isolate_trip10 {
				trip = <&SDM_SKIN_THERM_trip_point10>;
				cooling-device = <&cpu4_isolate 1 1>;
			};

			SDM_SKIN_THERM_cpu5_isolate_trip10 {
				trip = <&SDM_SKIN_THERM_trip_point10>;
				cooling-device = <&cpu5_isolate 1 1>;
			};

			SDM_SKIN_THERM_cpu6_isolate_trip10 {
				trip = <&SDM_SKIN_THERM_trip_point10>;
				cooling-device = <&cpu6_isolate 1 1>;
			};

			SDM_SKIN_THERM_cpu7_isolate_trip10 {
				trip = <&SDM_SKIN_THERM_trip_point10>;
				cooling-device = <&cpu7_isolate 1 1>;
			};

			SDM_SKIN_THERM_gpu_freq_trip10 {
				trip = <&SDM_SKIN_THERM_trip_point10>;
				cooling-device = <&msm_gpu 5 5>;
			};

			SDM_SKIN_THERM_backlight_trip10 {
				trip = <&SDM_SKIN_THERM_trip_point10>;
				cooling-device = <&mdss_mdp 194 194>;
			};

			SDM_SKIN_THERM_oem_chg_trip10 {
				trip = <&SDM_SKIN_THERM_trip_point10>;
				cooling-device = <&oem_charger_drv 4 4>;
			};

			SDM_SKIN_THERM_cpu0_freq_trip11 {
				trip = <&SDM_SKIN_THERM_trip_point11>;
				cooling-device = <&CPU0 (-1) 8>;
			};

			SDM_SKIN_THERM_cpu4_freq_trip11 {
				trip = <&SDM_SKIN_THERM_trip_point11>;
				cooling-device = <&CPU4 (-1) 16>;
			};

			SDM_SKIN_THERM_cpu7_freq_trip11 {
				trip = <&SDM_SKIN_THERM_trip_point11>;
				cooling-device = <&CPU7 (-1) 19>;
			};

			SDM_SKIN_THERM_cpu0_isolate_trip11 {
				trip = <&SDM_SKIN_THERM_trip_point11>;
				cooling-device = <&cpu0_isolate 0 0>;
			};

			SDM_SKIN_THERM_cpu1_isolate_trip11 {
				trip = <&SDM_SKIN_THERM_trip_point11>;
				cooling-device = <&cpu1_isolate 0 0>;
			};

			SDM_SKIN_THERM_cpu2_isolate_trip11 {
				trip = <&SDM_SKIN_THERM_trip_point11>;
				cooling-device = <&cpu2_isolate 0 0>;
			};

			SDM_SKIN_THERM_cpu3_isolate_trip11 {
				trip = <&SDM_SKIN_THERM_trip_point11>;
				cooling-device = <&cpu3_isolate 0 0>;
			};

			SDM_SKIN_THERM_cpu4_isolate_trip11 {
				trip = <&SDM_SKIN_THERM_trip_point11>;
				cooling-device = <&cpu4_isolate 1 1>;
			};

			SDM_SKIN_THERM_cpu5_isolate_trip11 {
				trip = <&SDM_SKIN_THERM_trip_point11>;
				cooling-device = <&cpu5_isolate 1 1>;
			};

			SDM_SKIN_THERM_cpu6_isolate_trip11 {
				trip = <&SDM_SKIN_THERM_trip_point11>;
				cooling-device = <&cpu6_isolate 1 1>;
			};

			SDM_SKIN_THERM_cpu7_isolate_trip11 {
				trip = <&SDM_SKIN_THERM_trip_point11>;
				cooling-device = <&cpu7_isolate 1 1>;
			};

			SDM_SKIN_THERM_gpu_freq_trip11 {
				trip = <&SDM_SKIN_THERM_trip_point11>;
				cooling-device = <&msm_gpu 5 5>;
			};

			SDM_SKIN_THERM_backlight_trip11 {
				trip = <&SDM_SKIN_THERM_trip_point11>;
				cooling-device = <&mdss_mdp 194 194>;
			};

			SDM_SKIN_THERM_oem_chg_trip11 {
				trip = <&SDM_SKIN_THERM_trip_point11>;
				cooling-device = <&oem_charger_drv 4 4>;
			};
		};
	};

	SDM_SKIN_THERM_f {
		polling-delay-passive = <1000>;
		polling-delay = <0>;
		thermal-governor = "low_limits_cap";
		thermal-sensors = <&pm8150l_adc_tm 78>;
		wake-capable-sensor;

		trips {
			SDM_SKIN_THERM_f_trip_point0: SDM_SKIN_THERM_f_trip0 {
				temperature = <(-30000)>;
				hysteresis = <0>;
				type = "passive";
			};
		};

		cooling-maps {
			SDM_SKIN_THERM_f_cpu0_freq_trip0 {
				trip = <&SDM_SKIN_THERM_f_trip_point0>;
				cooling-device = <&CPU0 (-1) 0>;
			};

			SDM_SKIN_THERM_f_cpu4_freq_trip0 {
				trip = <&SDM_SKIN_THERM_f_trip_point0>;
				cooling-device = <&CPU4 (-1) 0>;
			};

			SDM_SKIN_THERM_f_cpu7_freq_trip0 {
				trip = <&SDM_SKIN_THERM_f_trip_point0>;
				cooling-device = <&CPU7 (-1) 0>;
			};

			SDM_SKIN_THERM_f_cpu0_isolate_trip0 {
				trip = <&SDM_SKIN_THERM_f_trip_point0>;
				cooling-device = <&cpu0_isolate 0 0>;
			};

			SDM_SKIN_THERM_f_cpu1_isolate_trip0 {
				trip = <&SDM_SKIN_THERM_f_trip_point0>;
				cooling-device = <&cpu1_isolate 0 0>;
			};

			SDM_SKIN_THERM_f_cpu2_isolate_trip0 {
				trip = <&SDM_SKIN_THERM_f_trip_point0>;
				cooling-device = <&cpu2_isolate 0 0>;
			};

			SDM_SKIN_THERM_f_cpu3_isolate_trip0 {
				trip = <&SDM_SKIN_THERM_f_trip_point0>;
				cooling-device = <&cpu3_isolate 0 0>;
			};

			SDM_SKIN_THERM_f_cpu4_isolate_trip0 {
				trip = <&SDM_SKIN_THERM_f_trip_point0>;
				cooling-device = <&cpu4_isolate 1 1>;
			};

			SDM_SKIN_THERM_f_cpu5_isolate_trip0 {
				trip = <&SDM_SKIN_THERM_f_trip_point0>;
				cooling-device = <&cpu5_isolate 1 1>;
			};

			SDM_SKIN_THERM_f_cpu6_isolate_trip0 {
				trip = <&SDM_SKIN_THERM_f_trip_point0>;
				cooling-device = <&cpu6_isolate 1 1>;
			};

			SDM_SKIN_THERM_f_cpu7_isolate_trip0 {
				trip = <&SDM_SKIN_THERM_f_trip_point0>;
				cooling-device = <&cpu7_isolate 1 1>;
			};

			SDM_SKIN_THERM_f_gpu_freq_trip0 {
				trip = <&SDM_SKIN_THERM_f_trip_point0>;
				cooling-device = <&msm_gpu 4 4>;
			};

			SDM_SKIN_THERM_f_backlight_trip0 {
				trip = <&SDM_SKIN_THERM_f_trip_point0>;
				cooling-device = <&mdss_mdp 0 0>;
			};

			SDM_SKIN_THERM_f_oem_chg_trip0 {
				trip = <&SDM_SKIN_THERM_f_trip_point0>;
				cooling-device = <&oem_charger_drv 0 0>;
			};

			SDM_SKIN_THERM_f_charger_trip0 {
				trip = <&SDM_SKIN_THERM_f_trip_point0>;
				cooling-device = <&pm8150b_charger 0 0>;
			};

			SDM_SKIN_THERM_f_mmw_skin0_trip0 {
				trip = <&SDM_SKIN_THERM_f_trip_point0>;
				cooling-device = <&modem_mmw_skin0 (-1) 0>;
			};

			SDM_SKIN_THERM_f_mmw_skin1_trip0 {
				trip = <&SDM_SKIN_THERM_f_trip_point0>;
				cooling-device = <&modem_mmw_skin1 (-1) 0>;
			};

			SDM_SKIN_THERM_f_mmw_skin2_trip0 {
				trip = <&SDM_SKIN_THERM_f_trip_point0>;
				cooling-device = <&modem_mmw_skin2 (-1) 0>;
			};

			SDM_SKIN_THERM_f_mmw_skin3_trip0 {
				trip = <&SDM_SKIN_THERM_f_trip_point0>;
				cooling-device = <&modem_mmw_skin3 (-1) 0>;
			};

			SDM_SKIN_THERM_f_modem_skin_trip0 {
				trip = <&SDM_SKIN_THERM_f_trip_point0>;
				cooling-device = <&modem_skin (-1) 0>;
			};

			SDM_SKIN_THERM_f_pa_trip0 {
				trip = <&SDM_SKIN_THERM_f_trip_point0>;
				cooling-device = <&modem_pa (-1) 0>;
			};

			SDM_SKIN_THERM_f_pa_fr1_trip0 {
				trip = <&SDM_SKIN_THERM_f_trip_point0>;
				cooling-device = <&modem_pa_fr1 (-1) 0>;
			};
		};
	};

	USB_CONN_THERM {
		polling-delay-passive = <1000>;
		polling-delay = <0>;
		thermal-governor = "step_wise";
		thermal-sensors = <&pm8150b_adc_tm 79>;
		wake-capable-sensor;

		trips {
			USB_CONN_THERM_trip_point0: USB_CONN_THERM_trip0 {
				temperature = <70000>;
				hysteresis = <10000>;
				type = "passive";
			};

			USB_CONN_THERM_trip_point1: USB_CONN_THERM_trip1 {
				temperature = <125000>;
				hysteresis = <1000>;
				type = "passive";
			};

			USB_CONN_THERM_trip_point2: USB_CONN_THERM_trip2 {
				temperature = <125000>;
				hysteresis = <1000>;
				type = "passive";
			};

			USB_CONN_THERM_trip_point3: USB_CONN_THERM_trip3 {
				temperature = <125000>;
				hysteresis = <1000>;
				type = "passive";
			};

			USB_CONN_THERM_trip_point4: USB_CONN_THERM_trip4 {
				temperature = <125000>;
				hysteresis = <1000>;
				type = "passive";
			};

			USB_CONN_THERM_trip_point5: USB_CONN_THERM_trip5 {
				temperature = <125000>;
				hysteresis = <1000>;
				type = "passive";
			};

			USB_CONN_THERM_trip_point6: USB_CONN_THERM_trip6 {
				temperature = <125000>;
				hysteresis = <1000>;
				type = "passive";
			};

			USB_CONN_THERM_trip_point7: USB_CONN_THERM_trip7 {
				temperature = <125000>;
				hysteresis = <1000>;
				type = "passive";
			};

			USB_CONN_THERM_trip_point8: USB_CONN_THERM_trip8 {
				temperature = <125000>;
				hysteresis = <1000>;
				type = "passive";
			};

			USB_CONN_THERM_trip_point9: USB_CONN_THERM_trip9 {
				temperature = <125000>;
				hysteresis = <1000>;
				type = "passive";
			};

			USB_CONN_THERM_trip_point10: USB_CONN_THERM_trip10 {
				temperature = <125000>;
				hysteresis = <1000>;
				type = "passive";
			};

			USB_CONN_THERM_trip_point11: USB_CONN_THERM_trip11 {
				temperature = <125000>;
				hysteresis = <1000>;
				type = "passive";
			};
		};

		cooling-maps {
			USB_CONN_THERM_charger_trip0 {
				trip = <&USB_CONN_THERM_trip_point0>;
				cooling-device = <&pm8150b_charger 1 1>;
			};

			USB_CONN_THERM_charger_trip1 {
				trip = <&USB_CONN_THERM_trip_point1>;
				cooling-device = <&pm8150b_charger 1 1>;
			};

			USB_CONN_THERM_charger_trip2 {
				trip = <&USB_CONN_THERM_trip_point2>;
				cooling-device = <&pm8150b_charger 1 1>;
			};

			USB_CONN_THERM_charger_trip3 {
				trip = <&USB_CONN_THERM_trip_point3>;
				cooling-device = <&pm8150b_charger 1 1>;
			};

			USB_CONN_THERM_charger_trip4 {
				trip = <&USB_CONN_THERM_trip_point4>;
				cooling-device = <&pm8150b_charger 1 1>;
			};

			USB_CONN_THERM_charger_trip5 {
				trip = <&USB_CONN_THERM_trip_point5>;
				cooling-device = <&pm8150b_charger 1 1>;
			};

			USB_CONN_THERM_charger_trip6 {
				trip = <&USB_CONN_THERM_trip_point6>;
				cooling-device = <&pm8150b_charger 1 1>;
			};

			USB_CONN_THERM_charger_trip7 {
				trip = <&USB_CONN_THERM_trip_point7>;
				cooling-device = <&pm8150b_charger 1 1>;
			};

			USB_CONN_THERM_charger_trip8 {
				trip = <&USB_CONN_THERM_trip_point8>;
				cooling-device = <&pm8150b_charger 1 1>;
			};

			USB_CONN_THERM_charger_trip9 {
				trip = <&USB_CONN_THERM_trip_point9>;
				cooling-device = <&pm8150b_charger 1 1>;
			};

			USB_CONN_THERM_charger_trip10 {
				trip = <&USB_CONN_THERM_trip_point10>;
				cooling-device = <&pm8150b_charger 1 1>;
			};

			USB_CONN_THERM_charger_trip11 {
				trip = <&USB_CONN_THERM_trip_point11>;
				cooling-device = <&pm8150b_charger 1 1>;
			};
		};
	};

	USB_CONN_THERM_f {
		polling-delay-passive = <1000>;
		polling-delay = <0>;
		thermal-governor = "low_limits_cap";
		thermal-sensors = <&pm8150b_adc_tm 79>;
		wake-capable-sensor;

		trips {
			USB_CONN_THERM_f_trip_point0: USB_CONN_THERM_f_trip0 {
				temperature = <(-30000)>;
				hysteresis = <0>;
				type = "passive";
			};
		};

		cooling-maps {
			USB_CONN_THERM_f_cpu0_freq_trip0 {
				trip = <&USB_CONN_THERM_f_trip_point0>;
				cooling-device = <&CPU0 (-1) 0>;
			};

			USB_CONN_THERM_f_cpu4_freq_trip0 {
				trip = <&USB_CONN_THERM_f_trip_point0>;
				cooling-device = <&CPU4 (-1) 0>;
			};

			USB_CONN_THERM_f_cpu7_freq_trip0 {
				trip = <&USB_CONN_THERM_f_trip_point0>;
				cooling-device = <&CPU7 (-1) 0>;
			};

			USB_CONN_THERM_f_cpu0_isolate_trip0 {
				trip = <&USB_CONN_THERM_f_trip_point0>;
				cooling-device = <&cpu0_isolate 0 0>;
			};

			USB_CONN_THERM_f_cpu1_isolate_trip0 {
				trip = <&USB_CONN_THERM_f_trip_point0>;
				cooling-device = <&cpu1_isolate 0 0>;
			};

			USB_CONN_THERM_f_cpu2_isolate_trip0 {
				trip = <&USB_CONN_THERM_f_trip_point0>;
				cooling-device = <&cpu2_isolate 0 0>;
			};

			USB_CONN_THERM_f_cpu3_isolate_trip0 {
				trip = <&USB_CONN_THERM_f_trip_point0>;
				cooling-device = <&cpu3_isolate 0 0>;
			};

			USB_CONN_THERM_f_cpu4_isolate_trip0 {
				trip = <&USB_CONN_THERM_f_trip_point0>;
				cooling-device = <&cpu4_isolate 1 1>;
			};

			USB_CONN_THERM_f_cpu5_isolate_trip0 {
				trip = <&USB_CONN_THERM_f_trip_point0>;
				cooling-device = <&cpu5_isolate 1 1>;
			};

			USB_CONN_THERM_f_cpu6_isolate_trip0 {
				trip = <&USB_CONN_THERM_f_trip_point0>;
				cooling-device = <&cpu6_isolate 1 1>;
			};

			USB_CONN_THERM_f_cpu7_isolate_trip0 {
				trip = <&USB_CONN_THERM_f_trip_point0>;
				cooling-device = <&cpu7_isolate 1 1>;
			};

			USB_CONN_THERM_f_gpu_freq_trip0 {
				trip = <&USB_CONN_THERM_f_trip_point0>;
				cooling-device = <&msm_gpu 4 4>;
			};

			USB_CONN_THERM_f_backlight_trip0 {
				trip = <&USB_CONN_THERM_f_trip_point0>;
				cooling-device = <&mdss_mdp 0 0>;
			};

			USB_CONN_THERM_f_oem_chg_trip0 {
				trip = <&USB_CONN_THERM_f_trip_point0>;
				cooling-device = <&oem_charger_drv 0 0>;
			};

			USB_CONN_THERM_f_charger_trip0 {
				trip = <&USB_CONN_THERM_f_trip_point0>;
				cooling-device = <&pm8150b_charger 0 0>;
			};

			USB_CONN_THERM_f_mmw_skin0_trip0 {
				trip = <&USB_CONN_THERM_f_trip_point0>;
				cooling-device = <&modem_mmw_skin0 (-1) 0>;
			};

			USB_CONN_THERM_f_mmw_skin1_trip0 {
				trip = <&USB_CONN_THERM_f_trip_point0>;
				cooling-device = <&modem_mmw_skin1 (-1) 0>;
			};

			USB_CONN_THERM_f_mmw_skin2_trip0 {
				trip = <&USB_CONN_THERM_f_trip_point0>;
				cooling-device = <&modem_mmw_skin2 (-1) 0>;
			};

			USB_CONN_THERM_f_mmw_skin3_trip0 {
				trip = <&USB_CONN_THERM_f_trip_point0>;
				cooling-device = <&modem_mmw_skin3 (-1) 0>;
			};

			USB_CONN_THERM_f_modem_skin_trip0 {
				trip = <&USB_CONN_THERM_f_trip_point0>;
				cooling-device = <&modem_skin (-1) 0>;
			};

			USB_CONN_THERM_f_pa_trip0 {
				trip = <&USB_CONN_THERM_f_trip_point0>;
				cooling-device = <&modem_pa (-1) 0>;
			};

			USB_CONN_THERM_f_pa_fr1_trip0 {
				trip = <&USB_CONN_THERM_f_trip_point0>;
				cooling-device = <&modem_pa_fr1 (-1) 0>;
			};
		};
	};

	MDM_SKIN_THERM {
		polling-delay-passive = <1000>;
		polling-delay = <0>;
		thermal-governor = "step_wise";
		thermal-sensors = <&pm8150_adc_tm 77>;
		wake-capable-sensor;

		trips {
			MDM_SKIN_THERM_trip_point0: MDM_SKIN_THERM_trip0 {
				temperature = <50000>;
				hysteresis = <2000>;
				type = "passive";
			};

			MDM_SKIN_THERM_trip_point1: MDM_SKIN_THERM_trip1 {
				temperature = <52000>;
				hysteresis = <2000>;
				type = "passive";
			};

			MDM_SKIN_THERM_trip_point2: MDM_SKIN_THERM_trip2 {
				temperature = <53500>;
				hysteresis = <2000>;
				type = "passive";
			};

			MDM_SKIN_THERM_trip_point3: MDM_SKIN_THERM_trip3 {
				temperature = <125000>;
				hysteresis = <1000>;
				type = "passive";
			};

			MDM_SKIN_THERM_trip_point4: MDM_SKIN_THERM_trip4 {
				temperature = <125000>;
				hysteresis = <1000>;
				type = "passive";
			};

			MDM_SKIN_THERM_trip_point5: MDM_SKIN_THERM_trip5 {
				temperature = <125000>;
				hysteresis = <1000>;
				type = "passive";
			};

			MDM_SKIN_THERM_trip_point6: MDM_SKIN_THERM_trip6 {
				temperature = <125000>;
				hysteresis = <1000>;
				type = "passive";
			};

			MDM_SKIN_THERM_trip_point7: MDM_SKIN_THERM_trip7 {
				temperature = <125000>;
				hysteresis = <1000>;
				type = "passive";
			};

			MDM_SKIN_THERM_trip_point8: MDM_SKIN_THERM_trip8 {
				temperature = <125000>;
				hysteresis = <1000>;
				type = "passive";
			};

			MDM_SKIN_THERM_trip_point9: MDM_SKIN_THERM_trip9 {
				temperature = <125000>;
				hysteresis = <1000>;
				type = "passive";
			};

			MDM_SKIN_THERM_trip_point10: MDM_SKIN_THERM_trip10 {
				temperature = <125000>;
				hysteresis = <1000>;
				type = "passive";
			};

			MDM_SKIN_THERM_trip_point11: MDM_SKIN_THERM_trip11 {
				temperature = <125000>;
				hysteresis = <1000>;
				type = "passive";
			};
		};

		cooling-maps {
			MDM_SKIN_THERM_mmw_skin0_trip0 {
				trip = <&MDM_SKIN_THERM_trip_point0>;
				cooling-device = <&modem_mmw_skin0 (-1) 0>;
			};

			MDM_SKIN_THERM_mmw_skin1_trip0 {
				trip = <&MDM_SKIN_THERM_trip_point0>;
				cooling-device = <&modem_mmw_skin1 (-1) 0>;
			};

			MDM_SKIN_THERM_mmw_skin2_trip0 {
				trip = <&MDM_SKIN_THERM_trip_point0>;
				cooling-device = <&modem_mmw_skin2 (-1) 0>;
			};

			MDM_SKIN_THERM_mmw_skin3_trip0 {
				trip = <&MDM_SKIN_THERM_trip_point0>;
				cooling-device = <&modem_mmw_skin3 (-1) 0>;
			};

			MDM_SKIN_THERM_modem_skin_trip0 {
				trip = <&MDM_SKIN_THERM_trip_point0>;
				cooling-device = <&modem_skin (-1) 0>;
			};

			MDM_SKIN_THERM_pa_trip0 {
				trip = <&MDM_SKIN_THERM_trip_point0>;
				cooling-device = <&modem_pa (-1) 1>;
			};

			MDM_SKIN_THERM_pa_fr1_trip0 {
				trip = <&MDM_SKIN_THERM_trip_point0>;
				cooling-device = <&modem_pa_fr1 (-1) 0>;
			};

			MDM_SKIN_THERM_mmw_skin0_trip1 {
				trip = <&MDM_SKIN_THERM_trip_point1>;
				cooling-device = <&modem_mmw_skin0 (-1) 0>;
			};

			MDM_SKIN_THERM_mmw_skin1_trip1 {
				trip = <&MDM_SKIN_THERM_trip_point1>;
				cooling-device = <&modem_mmw_skin1 (-1) 0>;
			};

			MDM_SKIN_THERM_mmw_skin2_trip1 {
				trip = <&MDM_SKIN_THERM_trip_point1>;
				cooling-device = <&modem_mmw_skin2 (-1) 0>;
			};

			MDM_SKIN_THERM_mmw_skin3_trip1 {
				trip = <&MDM_SKIN_THERM_trip_point1>;
				cooling-device = <&modem_mmw_skin3 (-1) 0>;
			};

			MDM_SKIN_THERM_modem_skin_trip1 {
				trip = <&MDM_SKIN_THERM_trip_point1>;
				cooling-device = <&modem_skin (-1) 0>;
			};

			MDM_SKIN_THERM_pa_trip1 {
				trip = <&MDM_SKIN_THERM_trip_point1>;
				cooling-device = <&modem_pa (-1) 2>;
			};

			MDM_SKIN_THERM_pa_fr1_trip1 {
				trip = <&MDM_SKIN_THERM_trip_point1>;
				cooling-device = <&modem_pa_fr1 (-1) 1>;
			};

			MDM_SKIN_THERM_mmw_skin0_trip2 {
				trip = <&MDM_SKIN_THERM_trip_point2>;
				cooling-device = <&modem_mmw_skin0 (-1) 0>;
			};

			MDM_SKIN_THERM_mmw_skin1_trip2 {
				trip = <&MDM_SKIN_THERM_trip_point2>;
				cooling-device = <&modem_mmw_skin1 (-1) 0>;
			};

			MDM_SKIN_THERM_mmw_skin2_trip2 {
				trip = <&MDM_SKIN_THERM_trip_point2>;
				cooling-device = <&modem_mmw_skin2 (-1) 0>;
			};

			MDM_SKIN_THERM_mmw_skin3_trip2 {
				trip = <&MDM_SKIN_THERM_trip_point2>;
				cooling-device = <&modem_mmw_skin3 (-1) 0>;
			};

			MDM_SKIN_THERM_modem_skin_trip2 {
				trip = <&MDM_SKIN_THERM_trip_point2>;
				cooling-device = <&modem_skin (-1) 0>;
			};

			MDM_SKIN_THERM_pa_trip2 {
				trip = <&MDM_SKIN_THERM_trip_point2>;
				cooling-device = <&modem_pa (-1) 2>;
			};

			MDM_SKIN_THERM_pa_fr1_trip2 {
				trip = <&MDM_SKIN_THERM_trip_point2>;
				cooling-device = <&modem_pa_fr1 (-1) 2>;
			};

			MDM_SKIN_THERM_mmw_skin0_trip3 {
				trip = <&MDM_SKIN_THERM_trip_point3>;
				cooling-device = <&modem_mmw_skin0 (-1) 0>;
			};

			MDM_SKIN_THERM_mmw_skin1_trip3 {
				trip = <&MDM_SKIN_THERM_trip_point3>;
				cooling-device = <&modem_mmw_skin1 (-1) 0>;
			};

			MDM_SKIN_THERM_mmw_skin2_trip3 {
				trip = <&MDM_SKIN_THERM_trip_point3>;
				cooling-device = <&modem_mmw_skin2 (-1) 0>;
			};

			MDM_SKIN_THERM_mmw_skin3_trip3 {
				trip = <&MDM_SKIN_THERM_trip_point3>;
				cooling-device = <&modem_mmw_skin3 (-1) 0>;
			};

			MDM_SKIN_THERM_modem_skin_trip3 {
				trip = <&MDM_SKIN_THERM_trip_point3>;
				cooling-device = <&modem_skin (-1) 0>;
			};

			MDM_SKIN_THERM_pa_trip3 {
				trip = <&MDM_SKIN_THERM_trip_point3>;
				cooling-device = <&modem_pa (-1) 3>;
			};

			MDM_SKIN_THERM_pa_fr1_trip3 {
				trip = <&MDM_SKIN_THERM_trip_point3>;
				cooling-device = <&modem_pa_fr1 (-1) 3>;
			};

			MDM_SKIN_THERM_mmw_skin0_trip4 {
				trip = <&MDM_SKIN_THERM_trip_point4>;
				cooling-device = <&modem_mmw_skin0 (-1) 0>;
			};

			MDM_SKIN_THERM_mmw_skin1_trip4 {
				trip = <&MDM_SKIN_THERM_trip_point4>;
				cooling-device = <&modem_mmw_skin1 (-1) 0>;
			};

			MDM_SKIN_THERM_mmw_skin2_trip4 {
				trip = <&MDM_SKIN_THERM_trip_point4>;
				cooling-device = <&modem_mmw_skin2 (-1) 0>;
			};

			MDM_SKIN_THERM_mmw_skin3_trip4 {
				trip = <&MDM_SKIN_THERM_trip_point4>;
				cooling-device = <&modem_mmw_skin3 (-1) 0>;
			};

			MDM_SKIN_THERM_modem_skin_trip4 {
				trip = <&MDM_SKIN_THERM_trip_point4>;
				cooling-device = <&modem_skin (-1) 0>;
			};

			MDM_SKIN_THERM_pa_trip4 {
				trip = <&MDM_SKIN_THERM_trip_point4>;
				cooling-device = <&modem_pa (-1) 3>;
			};

			MDM_SKIN_THERM_pa_fr1_trip4 {
				trip = <&MDM_SKIN_THERM_trip_point4>;
				cooling-device = <&modem_pa_fr1 (-1) 3>;
			};

			MDM_SKIN_THERM_mmw_skin0_trip5 {
				trip = <&MDM_SKIN_THERM_trip_point5>;
				cooling-device = <&modem_mmw_skin0 (-1) 0>;
			};

			MDM_SKIN_THERM_mmw_skin1_trip5 {
				trip = <&MDM_SKIN_THERM_trip_point5>;
				cooling-device = <&modem_mmw_skin1 (-1) 0>;
			};

			MDM_SKIN_THERM_mmw_skin2_trip5 {
				trip = <&MDM_SKIN_THERM_trip_point5>;
				cooling-device = <&modem_mmw_skin2 (-1) 0>;
			};

			MDM_SKIN_THERM_mmw_skin3_trip5 {
				trip = <&MDM_SKIN_THERM_trip_point5>;
				cooling-device = <&modem_mmw_skin3 (-1) 0>;
			};

			MDM_SKIN_THERM_modem_skin_trip5 {
				trip = <&MDM_SKIN_THERM_trip_point5>;
				cooling-device = <&modem_skin (-1) 0>;
			};

			MDM_SKIN_THERM_pa_trip5 {
				trip = <&MDM_SKIN_THERM_trip_point5>;
				cooling-device = <&modem_pa (-1) 3>;
			};

			MDM_SKIN_THERM_pa_fr1_trip5 {
				trip = <&MDM_SKIN_THERM_trip_point5>;
				cooling-device = <&modem_pa_fr1 (-1) 3>;
			};

			MDM_SKIN_THERM_mmw_skin0_trip6 {
				trip = <&MDM_SKIN_THERM_trip_point6>;
				cooling-device = <&modem_mmw_skin0 (-1) 0>;
			};

			MDM_SKIN_THERM_mmw_skin1_trip6 {
				trip = <&MDM_SKIN_THERM_trip_point6>;
				cooling-device = <&modem_mmw_skin1 (-1) 0>;
			};

			MDM_SKIN_THERM_mmw_skin2_trip6 {
				trip = <&MDM_SKIN_THERM_trip_point6>;
				cooling-device = <&modem_mmw_skin2 (-1) 0>;
			};

			MDM_SKIN_THERM_mmw_skin3_trip6 {
				trip = <&MDM_SKIN_THERM_trip_point6>;
				cooling-device = <&modem_mmw_skin3 (-1) 0>;
			};

			MDM_SKIN_THERM_modem_skin_trip6 {
				trip = <&MDM_SKIN_THERM_trip_point6>;
				cooling-device = <&modem_skin (-1) 0>;
			};

			MDM_SKIN_THERM_pa_trip6 {
				trip = <&MDM_SKIN_THERM_trip_point6>;
				cooling-device = <&modem_pa (-1) 3>;
			};

			MDM_SKIN_THERM_pa_fr1_trip6 {
				trip = <&MDM_SKIN_THERM_trip_point6>;
				cooling-device = <&modem_pa_fr1 (-1) 3>;
			};

			MDM_SKIN_THERM_mmw_skin0_trip7 {
				trip = <&MDM_SKIN_THERM_trip_point7>;
				cooling-device = <&modem_mmw_skin0 (-1) 0>;
			};

			MDM_SKIN_THERM_mmw_skin1_trip7 {
				trip = <&MDM_SKIN_THERM_trip_point7>;
				cooling-device = <&modem_mmw_skin1 (-1) 0>;
			};

			MDM_SKIN_THERM_mmw_skin2_trip7 {
				trip = <&MDM_SKIN_THERM_trip_point7>;
				cooling-device = <&modem_mmw_skin2 (-1) 0>;
			};

			MDM_SKIN_THERM_mmw_skin3_trip7 {
				trip = <&MDM_SKIN_THERM_trip_point7>;
				cooling-device = <&modem_mmw_skin3 (-1) 0>;
			};

			MDM_SKIN_THERM_modem_skin_trip7 {
				trip = <&MDM_SKIN_THERM_trip_point7>;
				cooling-device = <&modem_skin (-1) 0>;
			};

			MDM_SKIN_THERM_pa_trip7 {
				trip = <&MDM_SKIN_THERM_trip_point7>;
				cooling-device = <&modem_pa (-1) 3>;
			};

			MDM_SKIN_THERM_pa_fr1_trip7 {
				trip = <&MDM_SKIN_THERM_trip_point7>;
				cooling-device = <&modem_pa_fr1 (-1) 3>;
			};

			MDM_SKIN_THERM_mmw_skin0_trip8 {
				trip = <&MDM_SKIN_THERM_trip_point8>;
				cooling-device = <&modem_mmw_skin0 (-1) 0>;
			};

			MDM_SKIN_THERM_mmw_skin1_trip8 {
				trip = <&MDM_SKIN_THERM_trip_point8>;
				cooling-device = <&modem_mmw_skin1 (-1) 0>;
			};

			MDM_SKIN_THERM_mmw_skin2_trip8 {
				trip = <&MDM_SKIN_THERM_trip_point8>;
				cooling-device = <&modem_mmw_skin2 (-1) 0>;
			};

			MDM_SKIN_THERM_mmw_skin3_trip8 {
				trip = <&MDM_SKIN_THERM_trip_point8>;
				cooling-device = <&modem_mmw_skin3 (-1) 0>;
			};

			MDM_SKIN_THERM_modem_skin_trip8 {
				trip = <&MDM_SKIN_THERM_trip_point8>;
				cooling-device = <&modem_skin (-1) 0>;
			};

			MDM_SKIN_THERM_pa_trip8 {
				trip = <&MDM_SKIN_THERM_trip_point8>;
				cooling-device = <&modem_pa (-1) 3>;
			};

			MDM_SKIN_THERM_pa_fr1_trip8 {
				trip = <&MDM_SKIN_THERM_trip_point8>;
				cooling-device = <&modem_pa_fr1 (-1) 3>;
			};

			MDM_SKIN_THERM_mmw_skin0_trip9 {
				trip = <&MDM_SKIN_THERM_trip_point9>;
				cooling-device = <&modem_mmw_skin0 (-1) 0>;
			};

			MDM_SKIN_THERM_mmw_skin1_trip9 {
				trip = <&MDM_SKIN_THERM_trip_point9>;
				cooling-device = <&modem_mmw_skin1 (-1) 0>;
			};

			MDM_SKIN_THERM_mmw_skin2_trip9 {
				trip = <&MDM_SKIN_THERM_trip_point9>;
				cooling-device = <&modem_mmw_skin2 (-1) 0>;
			};

			MDM_SKIN_THERM_mmw_skin3_trip9 {
				trip = <&MDM_SKIN_THERM_trip_point9>;
				cooling-device = <&modem_mmw_skin3 (-1) 0>;
			};

			MDM_SKIN_THERM_modem_skin_trip9 {
				trip = <&MDM_SKIN_THERM_trip_point9>;
				cooling-device = <&modem_skin (-1) 0>;
			};

			MDM_SKIN_THERM_pa_trip9 {
				trip = <&MDM_SKIN_THERM_trip_point9>;
				cooling-device = <&modem_pa (-1) 3>;
			};

			MDM_SKIN_THERM_pa_fr1_trip9 {
				trip = <&MDM_SKIN_THERM_trip_point9>;
				cooling-device = <&modem_pa_fr1 (-1) 3>;
			};

			MDM_SKIN_THERM_mmw_skin0_trip10 {
				trip = <&MDM_SKIN_THERM_trip_point10>;
				cooling-device = <&modem_mmw_skin0 (-1) 0>;
			};

			MDM_SKIN_THERM_mmw_skin1_trip10 {
				trip = <&MDM_SKIN_THERM_trip_point10>;
				cooling-device = <&modem_mmw_skin1 (-1) 0>;
			};

			MDM_SKIN_THERM_mmw_skin2_trip10 {
				trip = <&MDM_SKIN_THERM_trip_point10>;
				cooling-device = <&modem_mmw_skin2 (-1) 0>;
			};

			MDM_SKIN_THERM_mmw_skin3_trip10 {
				trip = <&MDM_SKIN_THERM_trip_point10>;
				cooling-device = <&modem_mmw_skin3 (-1) 0>;
			};

			MDM_SKIN_THERM_modem_skin_trip10 {
				trip = <&MDM_SKIN_THERM_trip_point10>;
				cooling-device = <&modem_skin (-1) 0>;
			};

			MDM_SKIN_THERM_pa_trip10 {
				trip = <&MDM_SKIN_THERM_trip_point10>;
				cooling-device = <&modem_pa (-1) 3>;
			};

			MDM_SKIN_THERM_pa_fr1_trip10 {
				trip = <&MDM_SKIN_THERM_trip_point10>;
				cooling-device = <&modem_pa_fr1 (-1) 3>;
			};

			MDM_SKIN_THERM_mmw_skin0_trip11 {
				trip = <&MDM_SKIN_THERM_trip_point11>;
				cooling-device = <&modem_mmw_skin0 (-1) 0>;
			};

			MDM_SKIN_THERM_mmw_skin1_trip11 {
				trip = <&MDM_SKIN_THERM_trip_point11>;
				cooling-device = <&modem_mmw_skin1 (-1) 0>;
			};

			MDM_SKIN_THERM_mmw_skin2_trip11 {
				trip = <&MDM_SKIN_THERM_trip_point11>;
				cooling-device = <&modem_mmw_skin2 (-1) 0>;
			};

			MDM_SKIN_THERM_mmw_skin3_trip11 {
				trip = <&MDM_SKIN_THERM_trip_point11>;
				cooling-device = <&modem_mmw_skin3 (-1) 0>;
			};

			MDM_SKIN_THERM_modem_skin_trip11 {
				trip = <&MDM_SKIN_THERM_trip_point11>;
				cooling-device = <&modem_skin (-1) 0>;
			};

			MDM_SKIN_THERM_pa_trip11 {
				trip = <&MDM_SKIN_THERM_trip_point11>;
				cooling-device = <&modem_pa (-1) 3>;
			};

			MDM_SKIN_THERM_pa_fr1_trip11 {
				trip = <&MDM_SKIN_THERM_trip_point11>;
				cooling-device = <&modem_pa_fr1 (-1) 3>;
			};
		};
	};

	MDM_SKIN_THERM_f {
		polling-delay-passive = <1000>;
		polling-delay = <0>;
		thermal-governor = "low_limits_cap";
		thermal-sensors = <&pm8150_adc_tm 77>;
		wake-capable-sensor;

		trips {
			MDM_SKIN_THERM_f_trip_point0: MDM_SKIN_THERM_f_trip0 {
				temperature = <(-30000)>;
				hysteresis = <0>;
				type = "passive";
			};
		};

		cooling-maps {
			MDM_SKIN_THERM_f_cpu0_freq_trip0 {
				trip = <&MDM_SKIN_THERM_f_trip_point0>;
				cooling-device = <&CPU0 (-1) 0>;
			};

			MDM_SKIN_THERM_f_cpu4_freq_trip0 {
				trip = <&MDM_SKIN_THERM_f_trip_point0>;
				cooling-device = <&CPU4 (-1) 0>;
			};

			MDM_SKIN_THERM_f_cpu7_freq_trip0 {
				trip = <&MDM_SKIN_THERM_f_trip_point0>;
				cooling-device = <&CPU7 (-1) 0>;
			};

			MDM_SKIN_THERM_f_cpu0_isolate_trip0 {
				trip = <&MDM_SKIN_THERM_f_trip_point0>;
				cooling-device = <&cpu0_isolate 0 0>;
			};

			MDM_SKIN_THERM_f_cpu1_isolate_trip0 {
				trip = <&MDM_SKIN_THERM_f_trip_point0>;
				cooling-device = <&cpu1_isolate 0 0>;
			};

			MDM_SKIN_THERM_f_cpu2_isolate_trip0 {
				trip = <&MDM_SKIN_THERM_f_trip_point0>;
				cooling-device = <&cpu2_isolate 0 0>;
			};

			MDM_SKIN_THERM_f_cpu3_isolate_trip0 {
				trip = <&MDM_SKIN_THERM_f_trip_point0>;
				cooling-device = <&cpu3_isolate 0 0>;
			};

			MDM_SKIN_THERM_f_cpu4_isolate_trip0 {
				trip = <&MDM_SKIN_THERM_f_trip_point0>;
				cooling-device = <&cpu4_isolate 1 1>;
			};

			MDM_SKIN_THERM_f_cpu5_isolate_trip0 {
				trip = <&MDM_SKIN_THERM_f_trip_point0>;
				cooling-device = <&cpu5_isolate 1 1>;
			};

			MDM_SKIN_THERM_f_cpu6_isolate_trip0 {
				trip = <&MDM_SKIN_THERM_f_trip_point0>;
				cooling-device = <&cpu6_isolate 1 1>;
			};

			MDM_SKIN_THERM_f_cpu7_isolate_trip0 {
				trip = <&MDM_SKIN_THERM_f_trip_point0>;
				cooling-device = <&cpu7_isolate 1 1>;
			};

			MDM_SKIN_THERM_f_gpu_freq_trip0 {
				trip = <&MDM_SKIN_THERM_f_trip_point0>;
				cooling-device = <&msm_gpu 4 4>;
			};

			MDM_SKIN_THERM_f_backlight_trip0 {
				trip = <&MDM_SKIN_THERM_f_trip_point0>;
				cooling-device = <&mdss_mdp 0 0>;
			};

			MDM_SKIN_THERM_f_oem_chg_trip0 {
				trip = <&MDM_SKIN_THERM_f_trip_point0>;
				cooling-device = <&oem_charger_drv 0 0>;
			};

			MDM_SKIN_THERM_f_charger_trip0 {
				trip = <&MDM_SKIN_THERM_f_trip_point0>;
				cooling-device = <&pm8150b_charger 0 0>;
			};

			MDM_SKIN_THERM_f_mmw_skin0_trip0 {
				trip = <&MDM_SKIN_THERM_f_trip_point0>;
				cooling-device = <&modem_mmw_skin0 (-1) 0>;
			};

			MDM_SKIN_THERM_f_mmw_skin1_trip0 {
				trip = <&MDM_SKIN_THERM_f_trip_point0>;
				cooling-device = <&modem_mmw_skin1 (-1) 0>;
			};

			MDM_SKIN_THERM_f_mmw_skin2_trip0 {
				trip = <&MDM_SKIN_THERM_f_trip_point0>;
				cooling-device = <&modem_mmw_skin2 (-1) 0>;
			};

			MDM_SKIN_THERM_f_mmw_skin3_trip0 {
				trip = <&MDM_SKIN_THERM_f_trip_point0>;
				cooling-device = <&modem_mmw_skin3 (-1) 0>;
			};

			MDM_SKIN_THERM_f_modem_skin_trip0 {
				trip = <&MDM_SKIN_THERM_f_trip_point0>;
				cooling-device = <&modem_skin (-1) 0>;
			};

			MDM_SKIN_THERM_f_pa_trip0 {
				trip = <&MDM_SKIN_THERM_f_trip_point0>;
				cooling-device = <&modem_pa (-1) 0>;
			};

			MDM_SKIN_THERM_f_pa_fr1_trip0 {
				trip = <&MDM_SKIN_THERM_f_trip_point0>;
				cooling-device = <&modem_pa_fr1 (-1) 0>;
			};
		};
	};

	PA_THERM1 {
		polling-delay-passive = <1000>;
		polling-delay = <0>;
		thermal-governor = "step_wise";
		thermal-sensors = <&qmi_sensor 100>;
		wake-capable-sensor;

		trips {
			PA_THERM1_trip_point0: PA_THERM1_trip0 {
				temperature = <59000>;
				hysteresis = <4000>;
				type = "passive";
			};

			PA_THERM1_trip_point1: PA_THERM1_trip1 {
				temperature = <63000>;
				hysteresis = <4000>;
				type = "passive";
			};

			PA_THERM1_trip_point2: PA_THERM1_trip2 {
				temperature = <125000>;
				hysteresis = <1000>;
				type = "passive";
			};

			PA_THERM1_trip_point3: PA_THERM1_trip3 {
				temperature = <125000>;
				hysteresis = <1000>;
				type = "passive";
			};

			PA_THERM1_trip_point4: PA_THERM1_trip4 {
				temperature = <125000>;
				hysteresis = <1000>;
				type = "passive";
			};

			PA_THERM1_trip_point5: PA_THERM1_trip5 {
				temperature = <125000>;
				hysteresis = <1000>;
				type = "passive";
			};

			PA_THERM1_trip_point6: PA_THERM1_trip6 {
				temperature = <125000>;
				hysteresis = <1000>;
				type = "passive";
			};

			PA_THERM1_trip_point7: PA_THERM1_trip7 {
				temperature = <125000>;
				hysteresis = <1000>;
				type = "passive";
			};

			PA_THERM1_trip_point8: PA_THERM1_trip8 {
				temperature = <125000>;
				hysteresis = <1000>;
				type = "passive";
			};

			PA_THERM1_trip_point9: PA_THERM1_trip9 {
				temperature = <125000>;
				hysteresis = <1000>;
				type = "passive";
			};

			PA_THERM1_trip_point10: PA_THERM1_trip10 {
				temperature = <125000>;
				hysteresis = <1000>;
				type = "passive";
			};

			PA_THERM1_trip_point11: PA_THERM1_trip11 {
				temperature = <125000>;
				hysteresis = <1000>;
				type = "passive";
			};
		};

		cooling-maps {
			PA_THERM1_mmw_skin0_trip0 {
				trip = <&PA_THERM1_trip_point0>;
				cooling-device = <&modem_mmw_skin0 (-1) 0>;
			};

			PA_THERM1_mmw_skin1_trip0 {
				trip = <&PA_THERM1_trip_point0>;
				cooling-device = <&modem_mmw_skin1 (-1) 0>;
			};

			PA_THERM1_mmw_skin2_trip0 {
				trip = <&PA_THERM1_trip_point0>;
				cooling-device = <&modem_mmw_skin2 (-1) 0>;
			};

			PA_THERM1_mmw_skin3_trip0 {
				trip = <&PA_THERM1_trip_point0>;
				cooling-device = <&modem_mmw_skin3 (-1) 0>;
			};

			PA_THERM1_modem_skin_trip0 {
				trip = <&PA_THERM1_trip_point0>;
				cooling-device = <&modem_skin (-1) 1>;
			};

			PA_THERM1_pa_trip0 {
				trip = <&PA_THERM1_trip_point0>;
				cooling-device = <&modem_pa (-1) 0>;
			};

			PA_THERM1_pa_fr1_trip0 {
				trip = <&PA_THERM1_trip_point0>;
				cooling-device = <&modem_pa_fr1 (-1) 0>;
			};

			PA_THERM1_mmw_skin0_trip1 {
				trip = <&PA_THERM1_trip_point1>;
				cooling-device = <&modem_mmw_skin0 (-1) 0>;
			};

			PA_THERM1_mmw_skin1_trip1 {
				trip = <&PA_THERM1_trip_point1>;
				cooling-device = <&modem_mmw_skin1 (-1) 0>;
			};

			PA_THERM1_mmw_skin2_trip1 {
				trip = <&PA_THERM1_trip_point1>;
				cooling-device = <&modem_mmw_skin2 (-1) 0>;
			};

			PA_THERM1_mmw_skin3_trip1 {
				trip = <&PA_THERM1_trip_point1>;
				cooling-device = <&modem_mmw_skin3 (-1) 0>;
			};

			PA_THERM1_modem_skin_trip1 {
				trip = <&PA_THERM1_trip_point1>;
				cooling-device = <&modem_skin (-1) 2>;
			};

			PA_THERM1_pa_trip1 {
				trip = <&PA_THERM1_trip_point1>;
				cooling-device = <&modem_pa (-1) 0>;
			};

			PA_THERM1_pa_fr1_trip1 {
				trip = <&PA_THERM1_trip_point1>;
				cooling-device = <&modem_pa_fr1 (-1) 0>;
			};

			PA_THERM1_mmw_skin0_trip2 {
				trip = <&PA_THERM1_trip_point2>;
				cooling-device = <&modem_mmw_skin0 (-1) 0>;
			};

			PA_THERM1_mmw_skin1_trip2 {
				trip = <&PA_THERM1_trip_point2>;
				cooling-device = <&modem_mmw_skin1 (-1) 0>;
			};

			PA_THERM1_mmw_skin2_trip2 {
				trip = <&PA_THERM1_trip_point2>;
				cooling-device = <&modem_mmw_skin2 (-1) 0>;
			};

			PA_THERM1_mmw_skin3_trip2 {
				trip = <&PA_THERM1_trip_point2>;
				cooling-device = <&modem_mmw_skin3 (-1) 0>;
			};

			PA_THERM1_modem_skin_trip2 {
				trip = <&PA_THERM1_trip_point2>;
				cooling-device = <&modem_skin (-1) 3>;
			};

			PA_THERM1_pa_trip2 {
				trip = <&PA_THERM1_trip_point2>;
				cooling-device = <&modem_pa (-1) 0>;
			};

			PA_THERM1_pa_fr1_trip2 {
				trip = <&PA_THERM1_trip_point2>;
				cooling-device = <&modem_pa_fr1 (-1) 0>;
			};

			PA_THERM1_mmw_skin0_trip3 {
				trip = <&PA_THERM1_trip_point3>;
				cooling-device = <&modem_mmw_skin0 (-1) 0>;
			};

			PA_THERM1_mmw_skin1_trip3 {
				trip = <&PA_THERM1_trip_point3>;
				cooling-device = <&modem_mmw_skin1 (-1) 0>;
			};

			PA_THERM1_mmw_skin2_trip3 {
				trip = <&PA_THERM1_trip_point3>;
				cooling-device = <&modem_mmw_skin2 (-1) 0>;
			};

			PA_THERM1_mmw_skin3_trip3 {
				trip = <&PA_THERM1_trip_point3>;
				cooling-device = <&modem_mmw_skin3 (-1) 0>;
			};

			PA_THERM1_modem_skin_trip3 {
				trip = <&PA_THERM1_trip_point3>;
				cooling-device = <&modem_skin (-1) 3>;
			};

			PA_THERM1_pa_trip3 {
				trip = <&PA_THERM1_trip_point3>;
				cooling-device = <&modem_pa (-1) 0>;
			};

			PA_THERM1_pa_fr1_trip3 {
				trip = <&PA_THERM1_trip_point3>;
				cooling-device = <&modem_pa_fr1 (-1) 0>;
			};

			PA_THERM1_mmw_skin0_trip4 {
				trip = <&PA_THERM1_trip_point4>;
				cooling-device = <&modem_mmw_skin0 (-1) 0>;
			};

			PA_THERM1_mmw_skin1_trip4 {
				trip = <&PA_THERM1_trip_point4>;
				cooling-device = <&modem_mmw_skin1 (-1) 0>;
			};

			PA_THERM1_mmw_skin2_trip4 {
				trip = <&PA_THERM1_trip_point4>;
				cooling-device = <&modem_mmw_skin2 (-1) 0>;
			};

			PA_THERM1_mmw_skin3_trip4 {
				trip = <&PA_THERM1_trip_point4>;
				cooling-device = <&modem_mmw_skin3 (-1) 0>;
			};

			PA_THERM1_modem_skin_trip4 {
				trip = <&PA_THERM1_trip_point4>;
				cooling-device = <&modem_skin (-1) 3>;
			};

			PA_THERM1_pa_trip4 {
				trip = <&PA_THERM1_trip_point4>;
				cooling-device = <&modem_pa (-1) 0>;
			};

			PA_THERM1_pa_fr1_trip4 {
				trip = <&PA_THERM1_trip_point4>;
				cooling-device = <&modem_pa_fr1 (-1) 0>;
			};

			PA_THERM1_mmw_skin0_trip5 {
				trip = <&PA_THERM1_trip_point5>;
				cooling-device = <&modem_mmw_skin0 (-1) 0>;
			};

			PA_THERM1_mmw_skin1_trip5 {
				trip = <&PA_THERM1_trip_point5>;
				cooling-device = <&modem_mmw_skin1 (-1) 0>;
			};

			PA_THERM1_mmw_skin2_trip5 {
				trip = <&PA_THERM1_trip_point5>;
				cooling-device = <&modem_mmw_skin2 (-1) 0>;
			};

			PA_THERM1_mmw_skin3_trip5 {
				trip = <&PA_THERM1_trip_point5>;
				cooling-device = <&modem_mmw_skin3 (-1) 0>;
			};

			PA_THERM1_modem_skin_trip5 {
				trip = <&PA_THERM1_trip_point5>;
				cooling-device = <&modem_skin (-1) 3>;
			};

			PA_THERM1_pa_trip5 {
				trip = <&PA_THERM1_trip_point5>;
				cooling-device = <&modem_pa (-1) 0>;
			};

			PA_THERM1_pa_fr1_trip5 {
				trip = <&PA_THERM1_trip_point5>;
				cooling-device = <&modem_pa_fr1 (-1) 0>;
			};

			PA_THERM1_mmw_skin0_trip6 {
				trip = <&PA_THERM1_trip_point6>;
				cooling-device = <&modem_mmw_skin0 (-1) 0>;
			};

			PA_THERM1_mmw_skin1_trip6 {
				trip = <&PA_THERM1_trip_point6>;
				cooling-device = <&modem_mmw_skin1 (-1) 0>;
			};

			PA_THERM1_mmw_skin2_trip6 {
				trip = <&PA_THERM1_trip_point6>;
				cooling-device = <&modem_mmw_skin2 (-1) 0>;
			};

			PA_THERM1_mmw_skin3_trip6 {
				trip = <&PA_THERM1_trip_point6>;
				cooling-device = <&modem_mmw_skin3 (-1) 0>;
			};

			PA_THERM1_modem_skin_trip6 {
				trip = <&PA_THERM1_trip_point6>;
				cooling-device = <&modem_skin (-1) 3>;
			};

			PA_THERM1_pa_trip6 {
				trip = <&PA_THERM1_trip_point6>;
				cooling-device = <&modem_pa (-1) 0>;
			};

			PA_THERM1_pa_fr1_trip6 {
				trip = <&PA_THERM1_trip_point6>;
				cooling-device = <&modem_pa_fr1 (-1) 0>;
			};

			PA_THERM1_mmw_skin0_trip7 {
				trip = <&PA_THERM1_trip_point7>;
				cooling-device = <&modem_mmw_skin0 (-1) 0>;
			};

			PA_THERM1_mmw_skin1_trip7 {
				trip = <&PA_THERM1_trip_point7>;
				cooling-device = <&modem_mmw_skin1 (-1) 0>;
			};

			PA_THERM1_mmw_skin2_trip7 {
				trip = <&PA_THERM1_trip_point7>;
				cooling-device = <&modem_mmw_skin2 (-1) 0>;
			};

			PA_THERM1_mmw_skin3_trip7 {
				trip = <&PA_THERM1_trip_point7>;
				cooling-device = <&modem_mmw_skin3 (-1) 0>;
			};

			PA_THERM1_modem_skin_trip7 {
				trip = <&PA_THERM1_trip_point7>;
				cooling-device = <&modem_skin (-1) 3>;
			};

			PA_THERM1_pa_trip7 {
				trip = <&PA_THERM1_trip_point7>;
				cooling-device = <&modem_pa (-1) 0>;
			};

			PA_THERM1_pa_fr1_trip7 {
				trip = <&PA_THERM1_trip_point7>;
				cooling-device = <&modem_pa_fr1 (-1) 0>;
			};

			PA_THERM1_mmw_skin0_trip8 {
				trip = <&PA_THERM1_trip_point8>;
				cooling-device = <&modem_mmw_skin0 (-1) 0>;
			};

			PA_THERM1_mmw_skin1_trip8 {
				trip = <&PA_THERM1_trip_point8>;
				cooling-device = <&modem_mmw_skin1 (-1) 0>;
			};

			PA_THERM1_mmw_skin2_trip8 {
				trip = <&PA_THERM1_trip_point8>;
				cooling-device = <&modem_mmw_skin2 (-1) 0>;
			};

			PA_THERM1_mmw_skin3_trip8 {
				trip = <&PA_THERM1_trip_point8>;
				cooling-device = <&modem_mmw_skin3 (-1) 0>;
			};

			PA_THERM1_modem_skin_trip8 {
				trip = <&PA_THERM1_trip_point8>;
				cooling-device = <&modem_skin (-1) 3>;
			};

			PA_THERM1_pa_trip8 {
				trip = <&PA_THERM1_trip_point8>;
				cooling-device = <&modem_pa (-1) 0>;
			};

			PA_THERM1_pa_fr1_trip8 {
				trip = <&PA_THERM1_trip_point8>;
				cooling-device = <&modem_pa_fr1 (-1) 0>;
			};

			PA_THERM1_mmw_skin0_trip9 {
				trip = <&PA_THERM1_trip_point9>;
				cooling-device = <&modem_mmw_skin0 (-1) 0>;
			};

			PA_THERM1_mmw_skin1_trip9 {
				trip = <&PA_THERM1_trip_point9>;
				cooling-device = <&modem_mmw_skin1 (-1) 0>;
			};

			PA_THERM1_mmw_skin2_trip9 {
				trip = <&PA_THERM1_trip_point9>;
				cooling-device = <&modem_mmw_skin2 (-1) 0>;
			};

			PA_THERM1_mmw_skin3_trip9 {
				trip = <&PA_THERM1_trip_point9>;
				cooling-device = <&modem_mmw_skin3 (-1) 0>;
			};

			PA_THERM1_modem_skin_trip9 {
				trip = <&PA_THERM1_trip_point9>;
				cooling-device = <&modem_skin (-1) 3>;
			};

			PA_THERM1_pa_trip9 {
				trip = <&PA_THERM1_trip_point9>;
				cooling-device = <&modem_pa (-1) 0>;
			};

			PA_THERM1_pa_fr1_trip9 {
				trip = <&PA_THERM1_trip_point9>;
				cooling-device = <&modem_pa_fr1 (-1) 0>;
			};

			PA_THERM1_mmw_skin0_trip10 {
				trip = <&PA_THERM1_trip_point10>;
				cooling-device = <&modem_mmw_skin0 (-1) 0>;
			};

			PA_THERM1_mmw_skin1_trip10 {
				trip = <&PA_THERM1_trip_point10>;
				cooling-device = <&modem_mmw_skin1 (-1) 0>;
			};

			PA_THERM1_mmw_skin2_trip10 {
				trip = <&PA_THERM1_trip_point10>;
				cooling-device = <&modem_mmw_skin2 (-1) 0>;
			};

			PA_THERM1_mmw_skin3_trip10 {
				trip = <&PA_THERM1_trip_point10>;
				cooling-device = <&modem_mmw_skin3 (-1) 0>;
			};

			PA_THERM1_modem_skin_trip10 {
				trip = <&PA_THERM1_trip_point10>;
				cooling-device = <&modem_skin (-1) 3>;
			};

			PA_THERM1_pa_trip10 {
				trip = <&PA_THERM1_trip_point10>;
				cooling-device = <&modem_pa (-1) 0>;
			};

			PA_THERM1_pa_fr1_trip10 {
				trip = <&PA_THERM1_trip_point10>;
				cooling-device = <&modem_pa_fr1 (-1) 0>;
			};

			PA_THERM1_mmw_skin0_trip11 {
				trip = <&PA_THERM1_trip_point11>;
				cooling-device = <&modem_mmw_skin0 (-1) 0>;
			};

			PA_THERM1_mmw_skin1_trip11 {
				trip = <&PA_THERM1_trip_point11>;
				cooling-device = <&modem_mmw_skin1 (-1) 0>;
			};

			PA_THERM1_mmw_skin2_trip11 {
				trip = <&PA_THERM1_trip_point11>;
				cooling-device = <&modem_mmw_skin2 (-1) 0>;
			};

			PA_THERM1_mmw_skin3_trip11 {
				trip = <&PA_THERM1_trip_point11>;
				cooling-device = <&modem_mmw_skin3 (-1) 0>;
			};

			PA_THERM1_modem_skin_trip11 {
				trip = <&PA_THERM1_trip_point11>;
				cooling-device = <&modem_skin (-1) 3>;
			};

			PA_THERM1_pa_trip11 {
				trip = <&PA_THERM1_trip_point11>;
				cooling-device = <&modem_pa (-1) 0>;
			};

			PA_THERM1_pa_fr1_trip11 {
				trip = <&PA_THERM1_trip_point11>;
				cooling-device = <&modem_pa_fr1 (-1) 0>;
			};
		};
	};

	PA_THERM1_f {
		polling-delay-passive = <1000>;
		polling-delay = <0>;
		thermal-governor = "low_limits_cap";
		thermal-sensors = <&qmi_sensor 100>;
		wake-capable-sensor;

		trips {
			PA_THERM1_f_trip_point0: PA_THERM1_f_trip0 {
				temperature = <(-30000)>;
				hysteresis = <0>;
				type = "passive";
			};
		};

		cooling-maps {
			PA_THERM1_f_cpu0_freq_trip0 {
				trip = <&PA_THERM1_f_trip_point0>;
				cooling-device = <&CPU0 (-1) 0>;
			};

			PA_THERM1_f_cpu4_freq_trip0 {
				trip = <&PA_THERM1_f_trip_point0>;
				cooling-device = <&CPU4 (-1) 0>;
			};

			PA_THERM1_f_cpu7_freq_trip0 {
				trip = <&PA_THERM1_f_trip_point0>;
				cooling-device = <&CPU7 (-1) 0>;
			};

			PA_THERM1_f_cpu0_isolate_trip0 {
				trip = <&PA_THERM1_f_trip_point0>;
				cooling-device = <&cpu0_isolate 0 0>;
			};

			PA_THERM1_f_cpu1_isolate_trip0 {
				trip = <&PA_THERM1_f_trip_point0>;
				cooling-device = <&cpu1_isolate 0 0>;
			};

			PA_THERM1_f_cpu2_isolate_trip0 {
				trip = <&PA_THERM1_f_trip_point0>;
				cooling-device = <&cpu2_isolate 0 0>;
			};

			PA_THERM1_f_cpu3_isolate_trip0 {
				trip = <&PA_THERM1_f_trip_point0>;
				cooling-device = <&cpu3_isolate 0 0>;
			};

			PA_THERM1_f_cpu4_isolate_trip0 {
				trip = <&PA_THERM1_f_trip_point0>;
				cooling-device = <&cpu4_isolate 1 1>;
			};

			PA_THERM1_f_cpu5_isolate_trip0 {
				trip = <&PA_THERM1_f_trip_point0>;
				cooling-device = <&cpu5_isolate 1 1>;
			};

			PA_THERM1_f_cpu6_isolate_trip0 {
				trip = <&PA_THERM1_f_trip_point0>;
				cooling-device = <&cpu6_isolate 1 1>;
			};

			PA_THERM1_f_cpu7_isolate_trip0 {
				trip = <&PA_THERM1_f_trip_point0>;
				cooling-device = <&cpu7_isolate 1 1>;
			};

			PA_THERM1_f_gpu_freq_trip0 {
				trip = <&PA_THERM1_f_trip_point0>;
				cooling-device = <&msm_gpu 4 4>;
			};

			PA_THERM1_f_backlight_trip0 {
				trip = <&PA_THERM1_f_trip_point0>;
				cooling-device = <&mdss_mdp 0 0>;
			};

			PA_THERM1_f_oem_chg_trip0 {
				trip = <&PA_THERM1_f_trip_point0>;
				cooling-device = <&oem_charger_drv 0 0>;
			};

			PA_THERM1_f_charger_trip0 {
				trip = <&PA_THERM1_f_trip_point0>;
				cooling-device = <&pm8150b_charger 0 0>;
			};

			PA_THERM1_f_mmw_skin0_trip0 {
				trip = <&PA_THERM1_f_trip_point0>;
				cooling-device = <&modem_mmw_skin0 (-1) 0>;
			};

			PA_THERM1_f_mmw_skin1_trip0 {
				trip = <&PA_THERM1_f_trip_point0>;
				cooling-device = <&modem_mmw_skin1 (-1) 0>;
			};

			PA_THERM1_f_mmw_skin2_trip0 {
				trip = <&PA_THERM1_f_trip_point0>;
				cooling-device = <&modem_mmw_skin2 (-1) 0>;
			};

			PA_THERM1_f_mmw_skin3_trip0 {
				trip = <&PA_THERM1_f_trip_point0>;
				cooling-device = <&modem_mmw_skin3 (-1) 0>;
			};

			PA_THERM1_f_modem_skin_trip0 {
				trip = <&PA_THERM1_f_trip_point0>;
				cooling-device = <&modem_skin (-1) 0>;
			};

			PA_THERM1_f_pa_trip0 {
				trip = <&PA_THERM1_f_trip_point0>;
				cooling-device = <&modem_pa (-1) 0>;
			};

			PA_THERM1_f_pa_fr1_trip0 {
				trip = <&PA_THERM1_f_trip_point0>;
				cooling-device = <&modem_pa_fr1 (-1) 0>;
			};
		};
	};

	PA_THERM2 {
		polling-delay-passive = <1000>;
		polling-delay = <0>;
		thermal-governor = "step_wise";
		thermal-sensors = <&qmi_sensor 101>;
		wake-capable-sensor;

		trips {
			PA_THERM2_trip_point0: PA_THERM2_trip0 {
				temperature = <125000>;
				hysteresis = <1000>;
				type = "passive";
			};

			PA_THERM2_trip_point1: PA_THERM2_trip1 {
				temperature = <125000>;
				hysteresis = <1000>;
				type = "passive";
			};

			PA_THERM2_trip_point2: PA_THERM2_trip2 {
				temperature = <125000>;
				hysteresis = <1000>;
				type = "passive";
			};

			PA_THERM2_trip_point3: PA_THERM2_trip3 {
				temperature = <125000>;
				hysteresis = <1000>;
				type = "passive";
			};

			PA_THERM2_trip_point4: PA_THERM2_trip4 {
				temperature = <125000>;
				hysteresis = <1000>;
				type = "passive";
			};

			PA_THERM2_trip_point5: PA_THERM2_trip5 {
				temperature = <125000>;
				hysteresis = <1000>;
				type = "passive";
			};

			PA_THERM2_trip_point6: PA_THERM2_trip6 {
				temperature = <125000>;
				hysteresis = <1000>;
				type = "passive";
			};

			PA_THERM2_trip_point7: PA_THERM2_trip7 {
				temperature = <125000>;
				hysteresis = <1000>;
				type = "passive";
			};

			PA_THERM2_trip_point8: PA_THERM2_trip8 {
				temperature = <125000>;
				hysteresis = <1000>;
				type = "passive";
			};

			PA_THERM2_trip_point9: PA_THERM2_trip9 {
				temperature = <125000>;
				hysteresis = <1000>;
				type = "passive";
			};

			PA_THERM2_trip_point10: PA_THERM2_trip10 {
				temperature = <125000>;
				hysteresis = <1000>;
				type = "passive";
			};

			PA_THERM2_trip_point11: PA_THERM2_trip11 {
				temperature = <125000>;
				hysteresis = <1000>;
				type = "passive";
			};
		};

		cooling-maps {
			PA_THERM2_mmw_skin0_trip0 {
				trip = <&PA_THERM2_trip_point0>;
				cooling-device = <&modem_mmw_skin0 (-1) 0>;
			};

			PA_THERM2_mmw_skin1_trip0 {
				trip = <&PA_THERM2_trip_point0>;
				cooling-device = <&modem_mmw_skin1 (-1) 0>;
			};

			PA_THERM2_mmw_skin2_trip0 {
				trip = <&PA_THERM2_trip_point0>;
				cooling-device = <&modem_mmw_skin2 (-1) 0>;
			};

			PA_THERM2_mmw_skin3_trip0 {
				trip = <&PA_THERM2_trip_point0>;
				cooling-device = <&modem_mmw_skin3 (-1) 0>;
			};

			PA_THERM2_modem_skin_trip0 {
				trip = <&PA_THERM2_trip_point0>;
				cooling-device = <&modem_skin (-1) 0>;
			};

			PA_THERM2_pa_trip0 {
				trip = <&PA_THERM2_trip_point0>;
				cooling-device = <&modem_pa (-1) 0>;
			};

			PA_THERM2_pa_fr1_trip0 {
				trip = <&PA_THERM2_trip_point0>;
				cooling-device = <&modem_pa_fr1 (-1) 0>;
			};

			PA_THERM2_mmw_skin0_trip1 {
				trip = <&PA_THERM2_trip_point1>;
				cooling-device = <&modem_mmw_skin0 (-1) 0>;
			};

			PA_THERM2_mmw_skin1_trip1 {
				trip = <&PA_THERM2_trip_point1>;
				cooling-device = <&modem_mmw_skin1 (-1) 0>;
			};

			PA_THERM2_mmw_skin2_trip1 {
				trip = <&PA_THERM2_trip_point1>;
				cooling-device = <&modem_mmw_skin2 (-1) 0>;
			};

			PA_THERM2_mmw_skin3_trip1 {
				trip = <&PA_THERM2_trip_point1>;
				cooling-device = <&modem_mmw_skin3 (-1) 0>;
			};

			PA_THERM2_modem_skin_trip1 {
				trip = <&PA_THERM2_trip_point1>;
				cooling-device = <&modem_skin (-1) 0>;
			};

			PA_THERM2_pa_trip1 {
				trip = <&PA_THERM2_trip_point1>;
				cooling-device = <&modem_pa (-1) 0>;
			};

			PA_THERM2_pa_fr1_trip1 {
				trip = <&PA_THERM2_trip_point1>;
				cooling-device = <&modem_pa_fr1 (-1) 0>;
			};

			PA_THERM2_mmw_skin0_trip2 {
				trip = <&PA_THERM2_trip_point2>;
				cooling-device = <&modem_mmw_skin0 (-1) 0>;
			};

			PA_THERM2_mmw_skin1_trip2 {
				trip = <&PA_THERM2_trip_point2>;
				cooling-device = <&modem_mmw_skin1 (-1) 0>;
			};

			PA_THERM2_mmw_skin2_trip2 {
				trip = <&PA_THERM2_trip_point2>;
				cooling-device = <&modem_mmw_skin2 (-1) 0>;
			};

			PA_THERM2_mmw_skin3_trip2 {
				trip = <&PA_THERM2_trip_point2>;
				cooling-device = <&modem_mmw_skin3 (-1) 0>;
			};

			PA_THERM2_modem_skin_trip2 {
				trip = <&PA_THERM2_trip_point2>;
				cooling-device = <&modem_skin (-1) 0>;
			};

			PA_THERM2_pa_trip2 {
				trip = <&PA_THERM2_trip_point2>;
				cooling-device = <&modem_pa (-1) 0>;
			};

			PA_THERM2_pa_fr1_trip2 {
				trip = <&PA_THERM2_trip_point2>;
				cooling-device = <&modem_pa_fr1 (-1) 0>;
			};

			PA_THERM2_mmw_skin0_trip3 {
				trip = <&PA_THERM2_trip_point3>;
				cooling-device = <&modem_mmw_skin0 (-1) 0>;
			};

			PA_THERM2_mmw_skin1_trip3 {
				trip = <&PA_THERM2_trip_point3>;
				cooling-device = <&modem_mmw_skin1 (-1) 0>;
			};

			PA_THERM2_mmw_skin2_trip3 {
				trip = <&PA_THERM2_trip_point3>;
				cooling-device = <&modem_mmw_skin2 (-1) 0>;
			};

			PA_THERM2_mmw_skin3_trip3 {
				trip = <&PA_THERM2_trip_point3>;
				cooling-device = <&modem_mmw_skin3 (-1) 0>;
			};

			PA_THERM2_modem_skin_trip3 {
				trip = <&PA_THERM2_trip_point3>;
				cooling-device = <&modem_skin (-1) 0>;
			};

			PA_THERM2_pa_trip3 {
				trip = <&PA_THERM2_trip_point3>;
				cooling-device = <&modem_pa (-1) 0>;
			};

			PA_THERM2_pa_fr1_trip3 {
				trip = <&PA_THERM2_trip_point3>;
				cooling-device = <&modem_pa_fr1 (-1) 0>;
			};

			PA_THERM2_mmw_skin0_trip4 {
				trip = <&PA_THERM2_trip_point4>;
				cooling-device = <&modem_mmw_skin0 (-1) 0>;
			};

			PA_THERM2_mmw_skin1_trip4 {
				trip = <&PA_THERM2_trip_point4>;
				cooling-device = <&modem_mmw_skin1 (-1) 0>;
			};

			PA_THERM2_mmw_skin2_trip4 {
				trip = <&PA_THERM2_trip_point4>;
				cooling-device = <&modem_mmw_skin2 (-1) 0>;
			};

			PA_THERM2_mmw_skin3_trip4 {
				trip = <&PA_THERM2_trip_point4>;
				cooling-device = <&modem_mmw_skin3 (-1) 0>;
			};

			PA_THERM2_modem_skin_trip4 {
				trip = <&PA_THERM2_trip_point4>;
				cooling-device = <&modem_skin (-1) 0>;
			};

			PA_THERM2_pa_trip4 {
				trip = <&PA_THERM2_trip_point4>;
				cooling-device = <&modem_pa (-1) 0>;
			};

			PA_THERM2_pa_fr1_trip4 {
				trip = <&PA_THERM2_trip_point4>;
				cooling-device = <&modem_pa_fr1 (-1) 0>;
			};

			PA_THERM2_mmw_skin0_trip5 {
				trip = <&PA_THERM2_trip_point5>;
				cooling-device = <&modem_mmw_skin0 (-1) 0>;
			};

			PA_THERM2_mmw_skin1_trip5 {
				trip = <&PA_THERM2_trip_point5>;
				cooling-device = <&modem_mmw_skin1 (-1) 0>;
			};

			PA_THERM2_mmw_skin2_trip5 {
				trip = <&PA_THERM2_trip_point5>;
				cooling-device = <&modem_mmw_skin2 (-1) 0>;
			};

			PA_THERM2_mmw_skin3_trip5 {
				trip = <&PA_THERM2_trip_point5>;
				cooling-device = <&modem_mmw_skin3 (-1) 0>;
			};

			PA_THERM2_modem_skin_trip5 {
				trip = <&PA_THERM2_trip_point5>;
				cooling-device = <&modem_skin (-1) 0>;
			};

			PA_THERM2_pa_trip5 {
				trip = <&PA_THERM2_trip_point5>;
				cooling-device = <&modem_pa (-1) 0>;
			};

			PA_THERM2_pa_fr1_trip5 {
				trip = <&PA_THERM2_trip_point5>;
				cooling-device = <&modem_pa_fr1 (-1) 0>;
			};

			PA_THERM2_mmw_skin0_trip6 {
				trip = <&PA_THERM2_trip_point6>;
				cooling-device = <&modem_mmw_skin0 (-1) 0>;
			};

			PA_THERM2_mmw_skin1_trip6 {
				trip = <&PA_THERM2_trip_point6>;
				cooling-device = <&modem_mmw_skin1 (-1) 0>;
			};

			PA_THERM2_mmw_skin2_trip6 {
				trip = <&PA_THERM2_trip_point6>;
				cooling-device = <&modem_mmw_skin2 (-1) 0>;
			};

			PA_THERM2_mmw_skin3_trip6 {
				trip = <&PA_THERM2_trip_point6>;
				cooling-device = <&modem_mmw_skin3 (-1) 0>;
			};

			PA_THERM2_modem_skin_trip6 {
				trip = <&PA_THERM2_trip_point6>;
				cooling-device = <&modem_skin (-1) 0>;
			};

			PA_THERM2_pa_trip6 {
				trip = <&PA_THERM2_trip_point6>;
				cooling-device = <&modem_pa (-1) 0>;
			};

			PA_THERM2_pa_fr1_trip6 {
				trip = <&PA_THERM2_trip_point6>;
				cooling-device = <&modem_pa_fr1 (-1) 0>;
			};

			PA_THERM2_mmw_skin0_trip7 {
				trip = <&PA_THERM2_trip_point7>;
				cooling-device = <&modem_mmw_skin0 (-1) 0>;
			};

			PA_THERM2_mmw_skin1_trip7 {
				trip = <&PA_THERM2_trip_point7>;
				cooling-device = <&modem_mmw_skin1 (-1) 0>;
			};

			PA_THERM2_mmw_skin2_trip7 {
				trip = <&PA_THERM2_trip_point7>;
				cooling-device = <&modem_mmw_skin2 (-1) 0>;
			};

			PA_THERM2_mmw_skin3_trip7 {
				trip = <&PA_THERM2_trip_point7>;
				cooling-device = <&modem_mmw_skin3 (-1) 0>;
			};

			PA_THERM2_modem_skin_trip7 {
				trip = <&PA_THERM2_trip_point7>;
				cooling-device = <&modem_skin (-1) 0>;
			};

			PA_THERM2_pa_trip7 {
				trip = <&PA_THERM2_trip_point7>;
				cooling-device = <&modem_pa (-1) 0>;
			};

			PA_THERM2_pa_fr1_trip7 {
				trip = <&PA_THERM2_trip_point7>;
				cooling-device = <&modem_pa_fr1 (-1) 0>;
			};

			PA_THERM2_mmw_skin0_trip8 {
				trip = <&PA_THERM2_trip_point8>;
				cooling-device = <&modem_mmw_skin0 (-1) 0>;
			};

			PA_THERM2_mmw_skin1_trip8 {
				trip = <&PA_THERM2_trip_point8>;
				cooling-device = <&modem_mmw_skin1 (-1) 0>;
			};

			PA_THERM2_mmw_skin2_trip8 {
				trip = <&PA_THERM2_trip_point8>;
				cooling-device = <&modem_mmw_skin2 (-1) 0>;
			};

			PA_THERM2_mmw_skin3_trip8 {
				trip = <&PA_THERM2_trip_point8>;
				cooling-device = <&modem_mmw_skin3 (-1) 0>;
			};

			PA_THERM2_modem_skin_trip8 {
				trip = <&PA_THERM2_trip_point8>;
				cooling-device = <&modem_skin (-1) 0>;
			};

			PA_THERM2_pa_trip8 {
				trip = <&PA_THERM2_trip_point8>;
				cooling-device = <&modem_pa (-1) 0>;
			};

			PA_THERM2_pa_fr1_trip8 {
				trip = <&PA_THERM2_trip_point8>;
				cooling-device = <&modem_pa_fr1 (-1) 0>;
			};

			PA_THERM2_mmw_skin0_trip9 {
				trip = <&PA_THERM2_trip_point9>;
				cooling-device = <&modem_mmw_skin0 (-1) 0>;
			};

			PA_THERM2_mmw_skin1_trip9 {
				trip = <&PA_THERM2_trip_point9>;
				cooling-device = <&modem_mmw_skin1 (-1) 0>;
			};

			PA_THERM2_mmw_skin2_trip9 {
				trip = <&PA_THERM2_trip_point9>;
				cooling-device = <&modem_mmw_skin2 (-1) 0>;
			};

			PA_THERM2_mmw_skin3_trip9 {
				trip = <&PA_THERM2_trip_point9>;
				cooling-device = <&modem_mmw_skin3 (-1) 0>;
			};

			PA_THERM2_modem_skin_trip9 {
				trip = <&PA_THERM2_trip_point9>;
				cooling-device = <&modem_skin (-1) 0>;
			};

			PA_THERM2_pa_trip9 {
				trip = <&PA_THERM2_trip_point9>;
				cooling-device = <&modem_pa (-1) 0>;
			};

			PA_THERM2_pa_fr1_trip9 {
				trip = <&PA_THERM2_trip_point9>;
				cooling-device = <&modem_pa_fr1 (-1) 0>;
			};

			PA_THERM2_mmw_skin0_trip10 {
				trip = <&PA_THERM2_trip_point10>;
				cooling-device = <&modem_mmw_skin0 (-1) 0>;
			};

			PA_THERM2_mmw_skin1_trip10 {
				trip = <&PA_THERM2_trip_point10>;
				cooling-device = <&modem_mmw_skin1 (-1) 0>;
			};

			PA_THERM2_mmw_skin2_trip10 {
				trip = <&PA_THERM2_trip_point10>;
				cooling-device = <&modem_mmw_skin2 (-1) 0>;
			};

			PA_THERM2_mmw_skin3_trip10 {
				trip = <&PA_THERM2_trip_point10>;
				cooling-device = <&modem_mmw_skin3 (-1) 0>;
			};

			PA_THERM2_modem_skin_trip10 {
				trip = <&PA_THERM2_trip_point10>;
				cooling-device = <&modem_skin (-1) 0>;
			};

			PA_THERM2_pa_trip10 {
				trip = <&PA_THERM2_trip_point10>;
				cooling-device = <&modem_pa (-1) 0>;
			};

			PA_THERM2_pa_fr1_trip10 {
				trip = <&PA_THERM2_trip_point10>;
				cooling-device = <&modem_pa_fr1 (-1) 0>;
			};

			PA_THERM2_mmw_skin0_trip11 {
				trip = <&PA_THERM2_trip_point11>;
				cooling-device = <&modem_mmw_skin0 (-1) 0>;
			};

			PA_THERM2_mmw_skin1_trip11 {
				trip = <&PA_THERM2_trip_point11>;
				cooling-device = <&modem_mmw_skin1 (-1) 0>;
			};

			PA_THERM2_mmw_skin2_trip11 {
				trip = <&PA_THERM2_trip_point11>;
				cooling-device = <&modem_mmw_skin2 (-1) 0>;
			};

			PA_THERM2_mmw_skin3_trip11 {
				trip = <&PA_THERM2_trip_point11>;
				cooling-device = <&modem_mmw_skin3 (-1) 0>;
			};

			PA_THERM2_modem_skin_trip11 {
				trip = <&PA_THERM2_trip_point11>;
				cooling-device = <&modem_skin (-1) 0>;
			};

			PA_THERM2_pa_trip11 {
				trip = <&PA_THERM2_trip_point11>;
				cooling-device = <&modem_pa (-1) 0>;
			};

			PA_THERM2_pa_fr1_trip11 {
				trip = <&PA_THERM2_trip_point11>;
				cooling-device = <&modem_pa_fr1 (-1) 0>;
			};
		};
	};

	PA_THERM2_f {
		polling-delay-passive = <1000>;
		polling-delay = <0>;
		thermal-governor = "low_limits_cap";
		thermal-sensors = <&qmi_sensor 101>;
		wake-capable-sensor;

		trips {
			PA_THERM2_f_trip_point0: PA_THERM2_f_trip0 {
				temperature = <(-30000)>;
				hysteresis = <0>;
				type = "passive";
			};
		};

		cooling-maps {
			PA_THERM2_f_cpu0_freq_trip0 {
				trip = <&PA_THERM2_f_trip_point0>;
				cooling-device = <&CPU0 (-1) 0>;
			};

			PA_THERM2_f_cpu4_freq_trip0 {
				trip = <&PA_THERM2_f_trip_point0>;
				cooling-device = <&CPU4 (-1) 0>;
			};

			PA_THERM2_f_cpu7_freq_trip0 {
				trip = <&PA_THERM2_f_trip_point0>;
				cooling-device = <&CPU7 (-1) 0>;
			};

			PA_THERM2_f_cpu0_isolate_trip0 {
				trip = <&PA_THERM2_f_trip_point0>;
				cooling-device = <&cpu0_isolate 0 0>;
			};

			PA_THERM2_f_cpu1_isolate_trip0 {
				trip = <&PA_THERM2_f_trip_point0>;
				cooling-device = <&cpu1_isolate 0 0>;
			};

			PA_THERM2_f_cpu2_isolate_trip0 {
				trip = <&PA_THERM2_f_trip_point0>;
				cooling-device = <&cpu2_isolate 0 0>;
			};

			PA_THERM2_f_cpu3_isolate_trip0 {
				trip = <&PA_THERM2_f_trip_point0>;
				cooling-device = <&cpu3_isolate 0 0>;
			};

			PA_THERM2_f_cpu4_isolate_trip0 {
				trip = <&PA_THERM2_f_trip_point0>;
				cooling-device = <&cpu4_isolate 1 1>;
			};

			PA_THERM2_f_cpu5_isolate_trip0 {
				trip = <&PA_THERM2_f_trip_point0>;
				cooling-device = <&cpu5_isolate 1 1>;
			};

			PA_THERM2_f_cpu6_isolate_trip0 {
				trip = <&PA_THERM2_f_trip_point0>;
				cooling-device = <&cpu6_isolate 1 1>;
			};

			PA_THERM2_f_cpu7_isolate_trip0 {
				trip = <&PA_THERM2_f_trip_point0>;
				cooling-device = <&cpu7_isolate 1 1>;
			};

			PA_THERM2_f_gpu_freq_trip0 {
				trip = <&PA_THERM2_f_trip_point0>;
				cooling-device = <&msm_gpu 4 4>;
			};

			PA_THERM2_f_backlight_trip0 {
				trip = <&PA_THERM2_f_trip_point0>;
				cooling-device = <&mdss_mdp 0 0>;
			};

			PA_THERM2_f_oem_chg_trip0 {
				trip = <&PA_THERM2_f_trip_point0>;
				cooling-device = <&oem_charger_drv 0 0>;
			};

			PA_THERM2_f_charger_trip0 {
				trip = <&PA_THERM2_f_trip_point0>;
				cooling-device = <&pm8150b_charger 0 0>;
			};

			PA_THERM2_f_mmw_skin0_trip0 {
				trip = <&PA_THERM2_f_trip_point0>;
				cooling-device = <&modem_mmw_skin0 (-1) 0>;
			};

			PA_THERM2_f_mmw_skin1_trip0 {
				trip = <&PA_THERM2_f_trip_point0>;
				cooling-device = <&modem_mmw_skin1 (-1) 0>;
			};

			PA_THERM2_f_mmw_skin2_trip0 {
				trip = <&PA_THERM2_f_trip_point0>;
				cooling-device = <&modem_mmw_skin2 (-1) 0>;
			};

			PA_THERM2_f_mmw_skin3_trip0 {
				trip = <&PA_THERM2_f_trip_point0>;
				cooling-device = <&modem_mmw_skin3 (-1) 0>;
			};

			PA_THERM2_f_modem_skin_trip0 {
				trip = <&PA_THERM2_f_trip_point0>;
				cooling-device = <&modem_skin (-1) 0>;
			};

			PA_THERM2_f_pa_trip0 {
				trip = <&PA_THERM2_f_trip_point0>;
				cooling-device = <&modem_pa (-1) 0>;
			};

			PA_THERM2_f_pa_fr1_trip0 {
				trip = <&PA_THERM2_f_trip_point0>;
				cooling-device = <&modem_pa_fr1 (-1) 0>;
			};
		};
	};

	QTM_LEFT_THERM {
		polling-delay-passive = <1000>;
		polling-delay = <0>;
		thermal-governor = "step_wise";
		thermal-sensors = <&pm8150_adc_tm 78>;
		wake-capable-sensor;

		trips {
			QTM_LEFT_THERM_trip_point0: QTM_LEFT_THERM_trip0 {
				temperature = <55000>;
				hysteresis = <1000>;
				type = "passive";
			};

			QTM_LEFT_THERM_trip_point1: QTM_LEFT_THERM_trip1 {
				temperature = <125000>;
				hysteresis = <1000>;
				type = "passive";
			};

			QTM_LEFT_THERM_trip_point2: QTM_LEFT_THERM_trip2 {
				temperature = <125000>;
				hysteresis = <1000>;
				type = "passive";
			};

			QTM_LEFT_THERM_trip_point3: QTM_LEFT_THERM_trip3 {
				temperature = <125000>;
				hysteresis = <1000>;
				type = "passive";
			};

			QTM_LEFT_THERM_trip_point4: QTM_LEFT_THERM_trip4 {
				temperature = <125000>;
				hysteresis = <1000>;
				type = "passive";
			};

			QTM_LEFT_THERM_trip_point5: QTM_LEFT_THERM_trip5 {
				temperature = <125000>;
				hysteresis = <1000>;
				type = "passive";
			};

			QTM_LEFT_THERM_trip_point6: QTM_LEFT_THERM_trip6 {
				temperature = <125000>;
				hysteresis = <1000>;
				type = "passive";
			};

			QTM_LEFT_THERM_trip_point7: QTM_LEFT_THERM_trip7 {
				temperature = <125000>;
				hysteresis = <1000>;
				type = "passive";
			};

			QTM_LEFT_THERM_trip_point8: QTM_LEFT_THERM_trip8 {
				temperature = <125000>;
				hysteresis = <1000>;
				type = "passive";
			};

			QTM_LEFT_THERM_trip_point9: QTM_LEFT_THERM_trip9 {
				temperature = <125000>;
				hysteresis = <1000>;
				type = "passive";
			};

			QTM_LEFT_THERM_trip_point10: QTM_LEFT_THERM_trip10 {
				temperature = <125000>;
				hysteresis = <1000>;
				type = "passive";
			};

			QTM_LEFT_THERM_trip_point11: QTM_LEFT_THERM_trip11 {
				temperature = <125000>;
				hysteresis = <1000>;
				type = "passive";
			};
		};

		cooling-maps {
			QTM_LEFT_THERM_mmw_skin0_trip0 {
				trip = <&QTM_LEFT_THERM_trip_point0>;
				cooling-device = <&modem_mmw_skin0 (-1) 0>;
			};

			QTM_LEFT_THERM_mmw_skin1_trip0 {
				trip = <&QTM_LEFT_THERM_trip_point0>;
				cooling-device = <&modem_mmw_skin1 (-1) 0>;
			};

			QTM_LEFT_THERM_mmw_skin2_trip0 {
				trip = <&QTM_LEFT_THERM_trip_point0>;
				cooling-device = <&modem_mmw_skin2 (-1) 2>;
			};

			QTM_LEFT_THERM_mmw_skin3_trip0 {
				trip = <&QTM_LEFT_THERM_trip_point0>;
				cooling-device = <&modem_mmw_skin3 (-1) 0>;
			};

			QTM_LEFT_THERM_modem_skin_trip0 {
				trip = <&QTM_LEFT_THERM_trip_point0>;
				cooling-device = <&modem_skin (-1) 0>;
			};

			QTM_LEFT_THERM_pa_trip0 {
				trip = <&QTM_LEFT_THERM_trip_point0>;
				cooling-device = <&modem_pa (-1) 0>;
			};

			QTM_LEFT_THERM_pa_fr1_trip0 {
				trip = <&QTM_LEFT_THERM_trip_point0>;
				cooling-device = <&modem_pa_fr1 (-1) 0>;
			};

			QTM_LEFT_THERM_mmw_skin0_trip1 {
				trip = <&QTM_LEFT_THERM_trip_point1>;
				cooling-device = <&modem_mmw_skin0 (-1) 0>;
			};

			QTM_LEFT_THERM_mmw_skin1_trip1 {
				trip = <&QTM_LEFT_THERM_trip_point1>;
				cooling-device = <&modem_mmw_skin1 (-1) 0>;
			};

			QTM_LEFT_THERM_mmw_skin2_trip1 {
				trip = <&QTM_LEFT_THERM_trip_point1>;
				cooling-device = <&modem_mmw_skin2 (-1) 3>;
			};

			QTM_LEFT_THERM_mmw_skin3_trip1 {
				trip = <&QTM_LEFT_THERM_trip_point1>;
				cooling-device = <&modem_mmw_skin3 (-1) 0>;
			};

			QTM_LEFT_THERM_modem_skin_trip1 {
				trip = <&QTM_LEFT_THERM_trip_point1>;
				cooling-device = <&modem_skin (-1) 0>;
			};

			QTM_LEFT_THERM_pa_trip1 {
				trip = <&QTM_LEFT_THERM_trip_point1>;
				cooling-device = <&modem_pa (-1) 0>;
			};

			QTM_LEFT_THERM_pa_fr1_trip1 {
				trip = <&QTM_LEFT_THERM_trip_point1>;
				cooling-device = <&modem_pa_fr1 (-1) 0>;
			};

			QTM_LEFT_THERM_mmw_skin0_trip2 {
				trip = <&QTM_LEFT_THERM_trip_point2>;
				cooling-device = <&modem_mmw_skin0 (-1) 0>;
			};

			QTM_LEFT_THERM_mmw_skin1_trip2 {
				trip = <&QTM_LEFT_THERM_trip_point2>;
				cooling-device = <&modem_mmw_skin1 (-1) 0>;
			};

			QTM_LEFT_THERM_mmw_skin2_trip2 {
				trip = <&QTM_LEFT_THERM_trip_point2>;
				cooling-device = <&modem_mmw_skin2 (-1) 3>;
			};

			QTM_LEFT_THERM_mmw_skin3_trip2 {
				trip = <&QTM_LEFT_THERM_trip_point2>;
				cooling-device = <&modem_mmw_skin3 (-1) 0>;
			};

			QTM_LEFT_THERM_modem_skin_trip2 {
				trip = <&QTM_LEFT_THERM_trip_point2>;
				cooling-device = <&modem_skin (-1) 0>;
			};

			QTM_LEFT_THERM_pa_trip2 {
				trip = <&QTM_LEFT_THERM_trip_point2>;
				cooling-device = <&modem_pa (-1) 0>;
			};

			QTM_LEFT_THERM_pa_fr1_trip2 {
				trip = <&QTM_LEFT_THERM_trip_point2>;
				cooling-device = <&modem_pa_fr1 (-1) 0>;
			};

			QTM_LEFT_THERM_mmw_skin0_trip3 {
				trip = <&QTM_LEFT_THERM_trip_point3>;
				cooling-device = <&modem_mmw_skin0 (-1) 0>;
			};

			QTM_LEFT_THERM_mmw_skin1_trip3 {
				trip = <&QTM_LEFT_THERM_trip_point3>;
				cooling-device = <&modem_mmw_skin1 (-1) 0>;
			};

			QTM_LEFT_THERM_mmw_skin2_trip3 {
				trip = <&QTM_LEFT_THERM_trip_point3>;
				cooling-device = <&modem_mmw_skin2 (-1) 3>;
			};

			QTM_LEFT_THERM_mmw_skin3_trip3 {
				trip = <&QTM_LEFT_THERM_trip_point3>;
				cooling-device = <&modem_mmw_skin3 (-1) 0>;
			};

			QTM_LEFT_THERM_modem_skin_trip3 {
				trip = <&QTM_LEFT_THERM_trip_point3>;
				cooling-device = <&modem_skin (-1) 0>;
			};

			QTM_LEFT_THERM_pa_trip3 {
				trip = <&QTM_LEFT_THERM_trip_point3>;
				cooling-device = <&modem_pa (-1) 0>;
			};

			QTM_LEFT_THERM_pa_fr1_trip3 {
				trip = <&QTM_LEFT_THERM_trip_point3>;
				cooling-device = <&modem_pa_fr1 (-1) 0>;
			};

			QTM_LEFT_THERM_mmw_skin0_trip4 {
				trip = <&QTM_LEFT_THERM_trip_point4>;
				cooling-device = <&modem_mmw_skin0 (-1) 0>;
			};

			QTM_LEFT_THERM_mmw_skin1_trip4 {
				trip = <&QTM_LEFT_THERM_trip_point4>;
				cooling-device = <&modem_mmw_skin1 (-1) 0>;
			};

			QTM_LEFT_THERM_mmw_skin2_trip4 {
				trip = <&QTM_LEFT_THERM_trip_point4>;
				cooling-device = <&modem_mmw_skin2 (-1) 3>;
			};

			QTM_LEFT_THERM_mmw_skin3_trip4 {
				trip = <&QTM_LEFT_THERM_trip_point4>;
				cooling-device = <&modem_mmw_skin3 (-1) 0>;
			};

			QTM_LEFT_THERM_modem_skin_trip4 {
				trip = <&QTM_LEFT_THERM_trip_point4>;
				cooling-device = <&modem_skin (-1) 0>;
			};

			QTM_LEFT_THERM_pa_trip4 {
				trip = <&QTM_LEFT_THERM_trip_point4>;
				cooling-device = <&modem_pa (-1) 0>;
			};

			QTM_LEFT_THERM_pa_fr1_trip4 {
				trip = <&QTM_LEFT_THERM_trip_point4>;
				cooling-device = <&modem_pa_fr1 (-1) 0>;
			};

			QTM_LEFT_THERM_mmw_skin0_trip5 {
				trip = <&QTM_LEFT_THERM_trip_point5>;
				cooling-device = <&modem_mmw_skin0 (-1) 0>;
			};

			QTM_LEFT_THERM_mmw_skin1_trip5 {
				trip = <&QTM_LEFT_THERM_trip_point5>;
				cooling-device = <&modem_mmw_skin1 (-1) 0>;
			};

			QTM_LEFT_THERM_mmw_skin2_trip5 {
				trip = <&QTM_LEFT_THERM_trip_point5>;
				cooling-device = <&modem_mmw_skin2 (-1) 3>;
			};

			QTM_LEFT_THERM_mmw_skin3_trip5 {
				trip = <&QTM_LEFT_THERM_trip_point5>;
				cooling-device = <&modem_mmw_skin3 (-1) 0>;
			};

			QTM_LEFT_THERM_modem_skin_trip5 {
				trip = <&QTM_LEFT_THERM_trip_point5>;
				cooling-device = <&modem_skin (-1) 0>;
			};

			QTM_LEFT_THERM_pa_trip5 {
				trip = <&QTM_LEFT_THERM_trip_point5>;
				cooling-device = <&modem_pa (-1) 0>;
			};

			QTM_LEFT_THERM_pa_fr1_trip5 {
				trip = <&QTM_LEFT_THERM_trip_point5>;
				cooling-device = <&modem_pa_fr1 (-1) 0>;
			};

			QTM_LEFT_THERM_mmw_skin0_trip6 {
				trip = <&QTM_LEFT_THERM_trip_point6>;
				cooling-device = <&modem_mmw_skin0 (-1) 0>;
			};

			QTM_LEFT_THERM_mmw_skin1_trip6 {
				trip = <&QTM_LEFT_THERM_trip_point6>;
				cooling-device = <&modem_mmw_skin1 (-1) 0>;
			};

			QTM_LEFT_THERM_mmw_skin2_trip6 {
				trip = <&QTM_LEFT_THERM_trip_point6>;
				cooling-device = <&modem_mmw_skin2 (-1) 3>;
			};

			QTM_LEFT_THERM_mmw_skin3_trip6 {
				trip = <&QTM_LEFT_THERM_trip_point6>;
				cooling-device = <&modem_mmw_skin3 (-1) 0>;
			};

			QTM_LEFT_THERM_modem_skin_trip6 {
				trip = <&QTM_LEFT_THERM_trip_point6>;
				cooling-device = <&modem_skin (-1) 0>;
			};

			QTM_LEFT_THERM_pa_trip6 {
				trip = <&QTM_LEFT_THERM_trip_point6>;
				cooling-device = <&modem_pa (-1) 0>;
			};

			QTM_LEFT_THERM_pa_fr1_trip6 {
				trip = <&QTM_LEFT_THERM_trip_point6>;
				cooling-device = <&modem_pa_fr1 (-1) 0>;
			};

			QTM_LEFT_THERM_mmw_skin0_trip7 {
				trip = <&QTM_LEFT_THERM_trip_point7>;
				cooling-device = <&modem_mmw_skin0 (-1) 0>;
			};

			QTM_LEFT_THERM_mmw_skin1_trip7 {
				trip = <&QTM_LEFT_THERM_trip_point7>;
				cooling-device = <&modem_mmw_skin1 (-1) 0>;
			};

			QTM_LEFT_THERM_mmw_skin2_trip7 {
				trip = <&QTM_LEFT_THERM_trip_point7>;
				cooling-device = <&modem_mmw_skin2 (-1) 3>;
			};

			QTM_LEFT_THERM_mmw_skin3_trip7 {
				trip = <&QTM_LEFT_THERM_trip_point7>;
				cooling-device = <&modem_mmw_skin3 (-1) 0>;
			};

			QTM_LEFT_THERM_modem_skin_trip7 {
				trip = <&QTM_LEFT_THERM_trip_point7>;
				cooling-device = <&modem_skin (-1) 0>;
			};

			QTM_LEFT_THERM_pa_trip7 {
				trip = <&QTM_LEFT_THERM_trip_point7>;
				cooling-device = <&modem_pa (-1) 0>;
			};

			QTM_LEFT_THERM_pa_fr1_trip7 {
				trip = <&QTM_LEFT_THERM_trip_point7>;
				cooling-device = <&modem_pa_fr1 (-1) 0>;
			};

			QTM_LEFT_THERM_mmw_skin0_trip8 {
				trip = <&QTM_LEFT_THERM_trip_point8>;
				cooling-device = <&modem_mmw_skin0 (-1) 0>;
			};

			QTM_LEFT_THERM_mmw_skin1_trip8 {
				trip = <&QTM_LEFT_THERM_trip_point8>;
				cooling-device = <&modem_mmw_skin1 (-1) 0>;
			};

			QTM_LEFT_THERM_mmw_skin2_trip8 {
				trip = <&QTM_LEFT_THERM_trip_point8>;
				cooling-device = <&modem_mmw_skin2 (-1) 3>;
			};

			QTM_LEFT_THERM_mmw_skin3_trip8 {
				trip = <&QTM_LEFT_THERM_trip_point8>;
				cooling-device = <&modem_mmw_skin3 (-1) 0>;
			};

			QTM_LEFT_THERM_modem_skin_trip8 {
				trip = <&QTM_LEFT_THERM_trip_point8>;
				cooling-device = <&modem_skin (-1) 0>;
			};

			QTM_LEFT_THERM_pa_trip8 {
				trip = <&QTM_LEFT_THERM_trip_point8>;
				cooling-device = <&modem_pa (-1) 0>;
			};

			QTM_LEFT_THERM_pa_fr1_trip8 {
				trip = <&QTM_LEFT_THERM_trip_point8>;
				cooling-device = <&modem_pa_fr1 (-1) 0>;
			};

			QTM_LEFT_THERM_mmw_skin0_trip9 {
				trip = <&QTM_LEFT_THERM_trip_point9>;
				cooling-device = <&modem_mmw_skin0 (-1) 0>;
			};

			QTM_LEFT_THERM_mmw_skin1_trip9 {
				trip = <&QTM_LEFT_THERM_trip_point9>;
				cooling-device = <&modem_mmw_skin1 (-1) 0>;
			};

			QTM_LEFT_THERM_mmw_skin2_trip9 {
				trip = <&QTM_LEFT_THERM_trip_point9>;
				cooling-device = <&modem_mmw_skin2 (-1) 3>;
			};

			QTM_LEFT_THERM_mmw_skin3_trip9 {
				trip = <&QTM_LEFT_THERM_trip_point9>;
				cooling-device = <&modem_mmw_skin3 (-1) 0>;
			};

			QTM_LEFT_THERM_modem_skin_trip9 {
				trip = <&QTM_LEFT_THERM_trip_point9>;
				cooling-device = <&modem_skin (-1) 0>;
			};

			QTM_LEFT_THERM_pa_trip9 {
				trip = <&QTM_LEFT_THERM_trip_point9>;
				cooling-device = <&modem_pa (-1) 0>;
			};

			QTM_LEFT_THERM_pa_fr1_trip9 {
				trip = <&QTM_LEFT_THERM_trip_point9>;
				cooling-device = <&modem_pa_fr1 (-1) 0>;
			};

			QTM_LEFT_THERM_mmw_skin0_trip10 {
				trip = <&QTM_LEFT_THERM_trip_point10>;
				cooling-device = <&modem_mmw_skin0 (-1) 0>;
			};

			QTM_LEFT_THERM_mmw_skin1_trip10 {
				trip = <&QTM_LEFT_THERM_trip_point10>;
				cooling-device = <&modem_mmw_skin1 (-1) 0>;
			};

			QTM_LEFT_THERM_mmw_skin2_trip10 {
				trip = <&QTM_LEFT_THERM_trip_point10>;
				cooling-device = <&modem_mmw_skin2 (-1) 3>;
			};

			QTM_LEFT_THERM_mmw_skin3_trip10 {
				trip = <&QTM_LEFT_THERM_trip_point10>;
				cooling-device = <&modem_mmw_skin3 (-1) 0>;
			};

			QTM_LEFT_THERM_modem_skin_trip10 {
				trip = <&QTM_LEFT_THERM_trip_point10>;
				cooling-device = <&modem_skin (-1) 0>;
			};

			QTM_LEFT_THERM_pa_trip10 {
				trip = <&QTM_LEFT_THERM_trip_point10>;
				cooling-device = <&modem_pa (-1) 0>;
			};

			QTM_LEFT_THERM_pa_fr1_trip10 {
				trip = <&QTM_LEFT_THERM_trip_point10>;
				cooling-device = <&modem_pa_fr1 (-1) 0>;
			};

			QTM_LEFT_THERM_mmw_skin0_trip11 {
				trip = <&QTM_LEFT_THERM_trip_point11>;
				cooling-device = <&modem_mmw_skin0 (-1) 0>;
			};

			QTM_LEFT_THERM_mmw_skin1_trip11 {
				trip = <&QTM_LEFT_THERM_trip_point11>;
				cooling-device = <&modem_mmw_skin1 (-1) 0>;
			};

			QTM_LEFT_THERM_mmw_skin2_trip11 {
				trip = <&QTM_LEFT_THERM_trip_point11>;
				cooling-device = <&modem_mmw_skin2 (-1) 3>;
			};

			QTM_LEFT_THERM_mmw_skin3_trip11 {
				trip = <&QTM_LEFT_THERM_trip_point11>;
				cooling-device = <&modem_mmw_skin3 (-1) 0>;
			};

			QTM_LEFT_THERM_modem_skin_trip11 {
				trip = <&QTM_LEFT_THERM_trip_point11>;
				cooling-device = <&modem_skin (-1) 0>;
			};

			QTM_LEFT_THERM_pa_trip11 {
				trip = <&QTM_LEFT_THERM_trip_point11>;
				cooling-device = <&modem_pa (-1) 0>;
			};

			QTM_LEFT_THERM_pa_fr1_trip11 {
				trip = <&QTM_LEFT_THERM_trip_point11>;
				cooling-device = <&modem_pa_fr1 (-1) 0>;
			};
		};
	};

	QTM_LEFT_THERM_f {
		polling-delay-passive = <1000>;
		polling-delay = <0>;
		thermal-governor = "low_limits_cap";
		thermal-sensors = <&pm8150_adc_tm 78>;
		wake-capable-sensor;

		trips {
			QTM_LEFT_THERM_f_trip_point0: QTM_LEFT_THERM_f_trip0 {
				temperature = <(-30000)>;
				hysteresis = <0>;
				type = "passive";
			};
		};

		cooling-maps {
			QTM_LEFT_THERM_f_cpu0_freq_trip0 {
				trip = <&QTM_LEFT_THERM_f_trip_point0>;
				cooling-device = <&CPU0 (-1) 0>;
			};

			QTM_LEFT_THERM_f_cpu4_freq_trip0 {
				trip = <&QTM_LEFT_THERM_f_trip_point0>;
				cooling-device = <&CPU4 (-1) 0>;
			};

			QTM_LEFT_THERM_f_cpu7_freq_trip0 {
				trip = <&QTM_LEFT_THERM_f_trip_point0>;
				cooling-device = <&CPU7 (-1) 0>;
			};

			QTM_LEFT_THERM_f_cpu0_isolate_trip0 {
				trip = <&QTM_LEFT_THERM_f_trip_point0>;
				cooling-device = <&cpu0_isolate 0 0>;
			};

			QTM_LEFT_THERM_f_cpu1_isolate_trip0 {
				trip = <&QTM_LEFT_THERM_f_trip_point0>;
				cooling-device = <&cpu1_isolate 0 0>;
			};

			QTM_LEFT_THERM_f_cpu2_isolate_trip0 {
				trip = <&QTM_LEFT_THERM_f_trip_point0>;
				cooling-device = <&cpu2_isolate 0 0>;
			};

			QTM_LEFT_THERM_f_cpu3_isolate_trip0 {
				trip = <&QTM_LEFT_THERM_f_trip_point0>;
				cooling-device = <&cpu3_isolate 0 0>;
			};

			QTM_LEFT_THERM_f_cpu4_isolate_trip0 {
				trip = <&QTM_LEFT_THERM_f_trip_point0>;
				cooling-device = <&cpu4_isolate 1 1>;
			};

			QTM_LEFT_THERM_f_cpu5_isolate_trip0 {
				trip = <&QTM_LEFT_THERM_f_trip_point0>;
				cooling-device = <&cpu5_isolate 1 1>;
			};

			QTM_LEFT_THERM_f_cpu6_isolate_trip0 {
				trip = <&QTM_LEFT_THERM_f_trip_point0>;
				cooling-device = <&cpu6_isolate 1 1>;
			};

			QTM_LEFT_THERM_f_cpu7_isolate_trip0 {
				trip = <&QTM_LEFT_THERM_f_trip_point0>;
				cooling-device = <&cpu7_isolate 1 1>;
			};

			QTM_LEFT_THERM_f_gpu_freq_trip0 {
				trip = <&QTM_LEFT_THERM_f_trip_point0>;
				cooling-device = <&msm_gpu 4 4>;
			};

			QTM_LEFT_THERM_f_backlight_trip0 {
				trip = <&QTM_LEFT_THERM_f_trip_point0>;
				cooling-device = <&mdss_mdp 0 0>;
			};

			QTM_LEFT_THERM_f_oem_chg_trip0 {
				trip = <&QTM_LEFT_THERM_f_trip_point0>;
				cooling-device = <&oem_charger_drv 0 0>;
			};

			QTM_LEFT_THERM_f_charger_trip0 {
				trip = <&QTM_LEFT_THERM_f_trip_point0>;
				cooling-device = <&pm8150b_charger 0 0>;
			};

			QTM_LEFT_THERM_f_mmw_skin0_trip0 {
				trip = <&QTM_LEFT_THERM_f_trip_point0>;
				cooling-device = <&modem_mmw_skin0 (-1) 0>;
			};

			QTM_LEFT_THERM_f_mmw_skin1_trip0 {
				trip = <&QTM_LEFT_THERM_f_trip_point0>;
				cooling-device = <&modem_mmw_skin1 (-1) 0>;
			};

			QTM_LEFT_THERM_f_mmw_skin2_trip0 {
				trip = <&QTM_LEFT_THERM_f_trip_point0>;
				cooling-device = <&modem_mmw_skin2 (-1) 0>;
			};

			QTM_LEFT_THERM_f_mmw_skin3_trip0 {
				trip = <&QTM_LEFT_THERM_f_trip_point0>;
				cooling-device = <&modem_mmw_skin3 (-1) 0>;
			};

			QTM_LEFT_THERM_f_modem_skin_trip0 {
				trip = <&QTM_LEFT_THERM_f_trip_point0>;
				cooling-device = <&modem_skin (-1) 0>;
			};

			QTM_LEFT_THERM_f_pa_trip0 {
				trip = <&QTM_LEFT_THERM_f_trip_point0>;
				cooling-device = <&modem_pa (-1) 0>;
			};

			QTM_LEFT_THERM_f_pa_fr1_trip0 {
				trip = <&QTM_LEFT_THERM_f_trip_point0>;
				cooling-device = <&modem_pa_fr1 (-1) 0>;
			};
		};
	};

	QTM_TOP_THERM {
		polling-delay-passive = <1000>;
		polling-delay = <0>;
		thermal-governor = "step_wise";
		thermal-sensors = <&pm8150l_adc_tm 79>;
		wake-capable-sensor;

		trips {
			QTM_TOP_THERM_trip_point0: QTM_TOP_THERM_trip0 {
				temperature = <54000>;
				hysteresis = <1000>;
				type = "passive";
			};

			QTM_TOP_THERM_trip_point1: QTM_TOP_THERM_trip1 {
				temperature = <125000>;
				hysteresis = <1000>;
				type = "passive";
			};

			QTM_TOP_THERM_trip_point2: QTM_TOP_THERM_trip2 {
				temperature = <125000>;
				hysteresis = <1000>;
				type = "passive";
			};

			QTM_TOP_THERM_trip_point3: QTM_TOP_THERM_trip3 {
				temperature = <125000>;
				hysteresis = <1000>;
				type = "passive";
			};

			QTM_TOP_THERM_trip_point4: QTM_TOP_THERM_trip4 {
				temperature = <125000>;
				hysteresis = <1000>;
				type = "passive";
			};

			QTM_TOP_THERM_trip_point5: QTM_TOP_THERM_trip5 {
				temperature = <125000>;
				hysteresis = <1000>;
				type = "passive";
			};

			QTM_TOP_THERM_trip_point6: QTM_TOP_THERM_trip6 {
				temperature = <125000>;
				hysteresis = <1000>;
				type = "passive";
			};

			QTM_TOP_THERM_trip_point7: QTM_TOP_THERM_trip7 {
				temperature = <125000>;
				hysteresis = <1000>;
				type = "passive";
			};

			QTM_TOP_THERM_trip_point8: QTM_TOP_THERM_trip8 {
				temperature = <125000>;
				hysteresis = <1000>;
				type = "passive";
			};

			QTM_TOP_THERM_trip_point9: QTM_TOP_THERM_trip9 {
				temperature = <125000>;
				hysteresis = <1000>;
				type = "passive";
			};

			QTM_TOP_THERM_trip_point10: QTM_TOP_THERM_trip10 {
				temperature = <125000>;
				hysteresis = <1000>;
				type = "passive";
			};

			QTM_TOP_THERM_trip_point11: QTM_TOP_THERM_trip11 {
				temperature = <125000>;
				hysteresis = <1000>;
				type = "passive";
			};
		};

		cooling-maps {
			QTM_TOP_THERM_mmw_skin0_trip0 {
				trip = <&QTM_TOP_THERM_trip_point0>;
				cooling-device = <&modem_mmw_skin0 (-1) 0>;
			};

			QTM_TOP_THERM_mmw_skin1_trip0 {
				trip = <&QTM_TOP_THERM_trip_point0>;
				cooling-device = <&modem_mmw_skin1 (-1) 2>;
			};

			QTM_TOP_THERM_mmw_skin2_trip0 {
				trip = <&QTM_TOP_THERM_trip_point0>;
				cooling-device = <&modem_mmw_skin2 (-1) 0>;
			};

			QTM_TOP_THERM_mmw_skin3_trip0 {
				trip = <&QTM_TOP_THERM_trip_point0>;
				cooling-device = <&modem_mmw_skin3 (-1) 0>;
			};

			QTM_TOP_THERM_modem_skin_trip0 {
				trip = <&QTM_TOP_THERM_trip_point0>;
				cooling-device = <&modem_skin (-1) 0>;
			};

			QTM_TOP_THERM_pa_trip0 {
				trip = <&QTM_TOP_THERM_trip_point0>;
				cooling-device = <&modem_pa (-1) 0>;
			};

			QTM_TOP_THERM_pa_fr1_trip0 {
				trip = <&QTM_TOP_THERM_trip_point0>;
				cooling-device = <&modem_pa_fr1 (-1) 0>;
			};

			QTM_TOP_THERM_mmw_skin0_trip1 {
				trip = <&QTM_TOP_THERM_trip_point1>;
				cooling-device = <&modem_mmw_skin0 (-1) 0>;
			};

			QTM_TOP_THERM_mmw_skin1_trip1 {
				trip = <&QTM_TOP_THERM_trip_point1>;
				cooling-device = <&modem_mmw_skin1 (-1) 3>;
			};

			QTM_TOP_THERM_mmw_skin2_trip1 {
				trip = <&QTM_TOP_THERM_trip_point1>;
				cooling-device = <&modem_mmw_skin2 (-1) 0>;
			};

			QTM_TOP_THERM_mmw_skin3_trip1 {
				trip = <&QTM_TOP_THERM_trip_point1>;
				cooling-device = <&modem_mmw_skin3 (-1) 0>;
			};

			QTM_TOP_THERM_modem_skin_trip1 {
				trip = <&QTM_TOP_THERM_trip_point1>;
				cooling-device = <&modem_skin (-1) 0>;
			};

			QTM_TOP_THERM_pa_trip1 {
				trip = <&QTM_TOP_THERM_trip_point1>;
				cooling-device = <&modem_pa (-1) 0>;
			};

			QTM_TOP_THERM_pa_fr1_trip1 {
				trip = <&QTM_TOP_THERM_trip_point1>;
				cooling-device = <&modem_pa_fr1 (-1) 0>;
			};

			QTM_TOP_THERM_mmw_skin0_trip2 {
				trip = <&QTM_TOP_THERM_trip_point2>;
				cooling-device = <&modem_mmw_skin0 (-1) 0>;
			};

			QTM_TOP_THERM_mmw_skin1_trip2 {
				trip = <&QTM_TOP_THERM_trip_point2>;
				cooling-device = <&modem_mmw_skin1 (-1) 3>;
			};

			QTM_TOP_THERM_mmw_skin2_trip2 {
				trip = <&QTM_TOP_THERM_trip_point2>;
				cooling-device = <&modem_mmw_skin2 (-1) 0>;
			};

			QTM_TOP_THERM_mmw_skin3_trip2 {
				trip = <&QTM_TOP_THERM_trip_point2>;
				cooling-device = <&modem_mmw_skin3 (-1) 0>;
			};

			QTM_TOP_THERM_modem_skin_trip2 {
				trip = <&QTM_TOP_THERM_trip_point2>;
				cooling-device = <&modem_skin (-1) 0>;
			};

			QTM_TOP_THERM_pa_trip2 {
				trip = <&QTM_TOP_THERM_trip_point2>;
				cooling-device = <&modem_pa (-1) 0>;
			};

			QTM_TOP_THERM_pa_fr1_trip2 {
				trip = <&QTM_TOP_THERM_trip_point2>;
				cooling-device = <&modem_pa_fr1 (-1) 0>;
			};

			QTM_TOP_THERM_mmw_skin0_trip3 {
				trip = <&QTM_TOP_THERM_trip_point3>;
				cooling-device = <&modem_mmw_skin0 (-1) 0>;
			};

			QTM_TOP_THERM_mmw_skin1_trip3 {
				trip = <&QTM_TOP_THERM_trip_point3>;
				cooling-device = <&modem_mmw_skin1 (-1) 3>;
			};

			QTM_TOP_THERM_mmw_skin2_trip3 {
				trip = <&QTM_TOP_THERM_trip_point3>;
				cooling-device = <&modem_mmw_skin2 (-1) 0>;
			};

			QTM_TOP_THERM_mmw_skin3_trip3 {
				trip = <&QTM_TOP_THERM_trip_point3>;
				cooling-device = <&modem_mmw_skin3 (-1) 0>;
			};

			QTM_TOP_THERM_modem_skin_trip3 {
				trip = <&QTM_TOP_THERM_trip_point3>;
				cooling-device = <&modem_skin (-1) 0>;
			};

			QTM_TOP_THERM_pa_trip3 {
				trip = <&QTM_TOP_THERM_trip_point3>;
				cooling-device = <&modem_pa (-1) 0>;
			};

			QTM_TOP_THERM_pa_fr1_trip3 {
				trip = <&QTM_TOP_THERM_trip_point3>;
				cooling-device = <&modem_pa_fr1 (-1) 0>;
			};

			QTM_TOP_THERM_mmw_skin0_trip4 {
				trip = <&QTM_TOP_THERM_trip_point4>;
				cooling-device = <&modem_mmw_skin0 (-1) 0>;
			};

			QTM_TOP_THERM_mmw_skin1_trip4 {
				trip = <&QTM_TOP_THERM_trip_point4>;
				cooling-device = <&modem_mmw_skin1 (-1) 3>;
			};

			QTM_TOP_THERM_mmw_skin2_trip4 {
				trip = <&QTM_TOP_THERM_trip_point4>;
				cooling-device = <&modem_mmw_skin2 (-1) 0>;
			};

			QTM_TOP_THERM_mmw_skin3_trip4 {
				trip = <&QTM_TOP_THERM_trip_point4>;
				cooling-device = <&modem_mmw_skin3 (-1) 0>;
			};

			QTM_TOP_THERM_modem_skin_trip4 {
				trip = <&QTM_TOP_THERM_trip_point4>;
				cooling-device = <&modem_skin (-1) 0>;
			};

			QTM_TOP_THERM_pa_trip4 {
				trip = <&QTM_TOP_THERM_trip_point4>;
				cooling-device = <&modem_pa (-1) 0>;
			};

			QTM_TOP_THERM_pa_fr1_trip4 {
				trip = <&QTM_TOP_THERM_trip_point4>;
				cooling-device = <&modem_pa_fr1 (-1) 0>;
			};

			QTM_TOP_THERM_mmw_skin0_trip5 {
				trip = <&QTM_TOP_THERM_trip_point5>;
				cooling-device = <&modem_mmw_skin0 (-1) 0>;
			};

			QTM_TOP_THERM_mmw_skin1_trip5 {
				trip = <&QTM_TOP_THERM_trip_point5>;
				cooling-device = <&modem_mmw_skin1 (-1) 3>;
			};

			QTM_TOP_THERM_mmw_skin2_trip5 {
				trip = <&QTM_TOP_THERM_trip_point5>;
				cooling-device = <&modem_mmw_skin2 (-1) 0>;
			};

			QTM_TOP_THERM_mmw_skin3_trip5 {
				trip = <&QTM_TOP_THERM_trip_point5>;
				cooling-device = <&modem_mmw_skin3 (-1) 0>;
			};

			QTM_TOP_THERM_modem_skin_trip5 {
				trip = <&QTM_TOP_THERM_trip_point5>;
				cooling-device = <&modem_skin (-1) 0>;
			};

			QTM_TOP_THERM_pa_trip5 {
				trip = <&QTM_TOP_THERM_trip_point5>;
				cooling-device = <&modem_pa (-1) 0>;
			};

			QTM_TOP_THERM_pa_fr1_trip5 {
				trip = <&QTM_TOP_THERM_trip_point5>;
				cooling-device = <&modem_pa_fr1 (-1) 0>;
			};

			QTM_TOP_THERM_mmw_skin0_trip6 {
				trip = <&QTM_TOP_THERM_trip_point6>;
				cooling-device = <&modem_mmw_skin0 (-1) 0>;
			};

			QTM_TOP_THERM_mmw_skin1_trip6 {
				trip = <&QTM_TOP_THERM_trip_point6>;
				cooling-device = <&modem_mmw_skin1 (-1) 3>;
			};

			QTM_TOP_THERM_mmw_skin2_trip6 {
				trip = <&QTM_TOP_THERM_trip_point6>;
				cooling-device = <&modem_mmw_skin2 (-1) 0>;
			};

			QTM_TOP_THERM_mmw_skin3_trip6 {
				trip = <&QTM_TOP_THERM_trip_point6>;
				cooling-device = <&modem_mmw_skin3 (-1) 0>;
			};

			QTM_TOP_THERM_modem_skin_trip6 {
				trip = <&QTM_TOP_THERM_trip_point6>;
				cooling-device = <&modem_skin (-1) 0>;
			};

			QTM_TOP_THERM_pa_trip6 {
				trip = <&QTM_TOP_THERM_trip_point6>;
				cooling-device = <&modem_pa (-1) 0>;
			};

			QTM_TOP_THERM_pa_fr1_trip6 {
				trip = <&QTM_TOP_THERM_trip_point6>;
				cooling-device = <&modem_pa_fr1 (-1) 0>;
			};

			QTM_TOP_THERM_mmw_skin0_trip7 {
				trip = <&QTM_TOP_THERM_trip_point7>;
				cooling-device = <&modem_mmw_skin0 (-1) 0>;
			};

			QTM_TOP_THERM_mmw_skin1_trip7 {
				trip = <&QTM_TOP_THERM_trip_point7>;
				cooling-device = <&modem_mmw_skin1 (-1) 3>;
			};

			QTM_TOP_THERM_mmw_skin2_trip7 {
				trip = <&QTM_TOP_THERM_trip_point7>;
				cooling-device = <&modem_mmw_skin2 (-1) 0>;
			};

			QTM_TOP_THERM_mmw_skin3_trip7 {
				trip = <&QTM_TOP_THERM_trip_point7>;
				cooling-device = <&modem_mmw_skin3 (-1) 0>;
			};

			QTM_TOP_THERM_modem_skin_trip7 {
				trip = <&QTM_TOP_THERM_trip_point7>;
				cooling-device = <&modem_skin (-1) 0>;
			};

			QTM_TOP_THERM_pa_trip7 {
				trip = <&QTM_TOP_THERM_trip_point7>;
				cooling-device = <&modem_pa (-1) 0>;
			};

			QTM_TOP_THERM_pa_fr1_trip7 {
				trip = <&QTM_TOP_THERM_trip_point7>;
				cooling-device = <&modem_pa_fr1 (-1) 0>;
			};

			QTM_TOP_THERM_mmw_skin0_trip8 {
				trip = <&QTM_TOP_THERM_trip_point8>;
				cooling-device = <&modem_mmw_skin0 (-1) 0>;
			};

			QTM_TOP_THERM_mmw_skin1_trip8 {
				trip = <&QTM_TOP_THERM_trip_point8>;
				cooling-device = <&modem_mmw_skin1 (-1) 3>;
			};

			QTM_TOP_THERM_mmw_skin2_trip8 {
				trip = <&QTM_TOP_THERM_trip_point8>;
				cooling-device = <&modem_mmw_skin2 (-1) 0>;
			};

			QTM_TOP_THERM_mmw_skin3_trip8 {
				trip = <&QTM_TOP_THERM_trip_point8>;
				cooling-device = <&modem_mmw_skin3 (-1) 0>;
			};

			QTM_TOP_THERM_modem_skin_trip8 {
				trip = <&QTM_TOP_THERM_trip_point8>;
				cooling-device = <&modem_skin (-1) 0>;
			};

			QTM_TOP_THERM_pa_trip8 {
				trip = <&QTM_TOP_THERM_trip_point8>;
				cooling-device = <&modem_pa (-1) 0>;
			};

			QTM_TOP_THERM_pa_fr1_trip8 {
				trip = <&QTM_TOP_THERM_trip_point8>;
				cooling-device = <&modem_pa_fr1 (-1) 0>;
			};

			QTM_TOP_THERM_mmw_skin0_trip9 {
				trip = <&QTM_TOP_THERM_trip_point9>;
				cooling-device = <&modem_mmw_skin0 (-1) 0>;
			};

			QTM_TOP_THERM_mmw_skin1_trip9 {
				trip = <&QTM_TOP_THERM_trip_point9>;
				cooling-device = <&modem_mmw_skin1 (-1) 3>;
			};

			QTM_TOP_THERM_mmw_skin2_trip9 {
				trip = <&QTM_TOP_THERM_trip_point9>;
				cooling-device = <&modem_mmw_skin2 (-1) 0>;
			};

			QTM_TOP_THERM_mmw_skin3_trip9 {
				trip = <&QTM_TOP_THERM_trip_point9>;
				cooling-device = <&modem_mmw_skin3 (-1) 0>;
			};

			QTM_TOP_THERM_modem_skin_trip9 {
				trip = <&QTM_TOP_THERM_trip_point9>;
				cooling-device = <&modem_skin (-1) 0>;
			};

			QTM_TOP_THERM_pa_trip9 {
				trip = <&QTM_TOP_THERM_trip_point9>;
				cooling-device = <&modem_pa (-1) 0>;
			};

			QTM_TOP_THERM_pa_fr1_trip9 {
				trip = <&QTM_TOP_THERM_trip_point9>;
				cooling-device = <&modem_pa_fr1 (-1) 0>;
			};

			QTM_TOP_THERM_mmw_skin0_trip10 {
				trip = <&QTM_TOP_THERM_trip_point10>;
				cooling-device = <&modem_mmw_skin0 (-1) 0>;
			};

			QTM_TOP_THERM_mmw_skin1_trip10 {
				trip = <&QTM_TOP_THERM_trip_point10>;
				cooling-device = <&modem_mmw_skin1 (-1) 3>;
			};

			QTM_TOP_THERM_mmw_skin2_trip10 {
				trip = <&QTM_TOP_THERM_trip_point10>;
				cooling-device = <&modem_mmw_skin2 (-1) 0>;
			};

			QTM_TOP_THERM_mmw_skin3_trip10 {
				trip = <&QTM_TOP_THERM_trip_point10>;
				cooling-device = <&modem_mmw_skin3 (-1) 0>;
			};

			QTM_TOP_THERM_modem_skin_trip10 {
				trip = <&QTM_TOP_THERM_trip_point10>;
				cooling-device = <&modem_skin (-1) 0>;
			};

			QTM_TOP_THERM_pa_trip10 {
				trip = <&QTM_TOP_THERM_trip_point10>;
				cooling-device = <&modem_pa (-1) 0>;
			};

			QTM_TOP_THERM_pa_fr1_trip10 {
				trip = <&QTM_TOP_THERM_trip_point10>;
				cooling-device = <&modem_pa_fr1 (-1) 0>;
			};

			QTM_TOP_THERM_mmw_skin0_trip11 {
				trip = <&QTM_TOP_THERM_trip_point11>;
				cooling-device = <&modem_mmw_skin0 (-1) 0>;
			};

			QTM_TOP_THERM_mmw_skin1_trip11 {
				trip = <&QTM_TOP_THERM_trip_point11>;
				cooling-device = <&modem_mmw_skin1 (-1) 3>;
			};

			QTM_TOP_THERM_mmw_skin2_trip11 {
				trip = <&QTM_TOP_THERM_trip_point11>;
				cooling-device = <&modem_mmw_skin2 (-1) 0>;
			};

			QTM_TOP_THERM_mmw_skin3_trip11 {
				trip = <&QTM_TOP_THERM_trip_point11>;
				cooling-device = <&modem_mmw_skin3 (-1) 0>;
			};

			QTM_TOP_THERM_modem_skin_trip11 {
				trip = <&QTM_TOP_THERM_trip_point11>;
				cooling-device = <&modem_skin (-1) 0>;
			};

			QTM_TOP_THERM_pa_trip11 {
				trip = <&QTM_TOP_THERM_trip_point11>;
				cooling-device = <&modem_pa (-1) 0>;
			};

			QTM_TOP_THERM_pa_fr1_trip11 {
				trip = <&QTM_TOP_THERM_trip_point11>;
				cooling-device = <&modem_pa_fr1 (-1) 0>;
			};
		};
	};

	QTM_TOP_THERM_f {
		polling-delay-passive = <1000>;
		polling-delay = <0>;
		thermal-governor = "low_limits_cap";
		thermal-sensors = <&pm8150l_adc_tm 79>;
		wake-capable-sensor;

		trips {
			QTM_TOP_THERM_f_trip_point0: QTM_TOP_THERM_f_trip0 {
				temperature = <(-30000)>;
				hysteresis = <0>;
				type = "passive";
			};
		};

		cooling-maps {
			QTM_TOP_THERM_f_cpu0_freq_trip0 {
				trip = <&QTM_TOP_THERM_f_trip_point0>;
				cooling-device = <&CPU0 (-1) 0>;
			};

			QTM_TOP_THERM_f_cpu4_freq_trip0 {
				trip = <&QTM_TOP_THERM_f_trip_point0>;
				cooling-device = <&CPU4 (-1) 0>;
			};

			QTM_TOP_THERM_f_cpu7_freq_trip0 {
				trip = <&QTM_TOP_THERM_f_trip_point0>;
				cooling-device = <&CPU7 (-1) 0>;
			};

			QTM_TOP_THERM_f_cpu0_isolate_trip0 {
				trip = <&QTM_TOP_THERM_f_trip_point0>;
				cooling-device = <&cpu0_isolate 0 0>;
			};

			QTM_TOP_THERM_f_cpu1_isolate_trip0 {
				trip = <&QTM_TOP_THERM_f_trip_point0>;
				cooling-device = <&cpu1_isolate 0 0>;
			};

			QTM_TOP_THERM_f_cpu2_isolate_trip0 {
				trip = <&QTM_TOP_THERM_f_trip_point0>;
				cooling-device = <&cpu2_isolate 0 0>;
			};

			QTM_TOP_THERM_f_cpu3_isolate_trip0 {
				trip = <&QTM_TOP_THERM_f_trip_point0>;
				cooling-device = <&cpu3_isolate 0 0>;
			};

			QTM_TOP_THERM_f_cpu4_isolate_trip0 {
				trip = <&QTM_TOP_THERM_f_trip_point0>;
				cooling-device = <&cpu4_isolate 1 1>;
			};

			QTM_TOP_THERM_f_cpu5_isolate_trip0 {
				trip = <&QTM_TOP_THERM_f_trip_point0>;
				cooling-device = <&cpu5_isolate 1 1>;
			};

			QTM_TOP_THERM_f_cpu6_isolate_trip0 {
				trip = <&QTM_TOP_THERM_f_trip_point0>;
				cooling-device = <&cpu6_isolate 1 1>;
			};

			QTM_TOP_THERM_f_cpu7_isolate_trip0 {
				trip = <&QTM_TOP_THERM_f_trip_point0>;
				cooling-device = <&cpu7_isolate 1 1>;
			};

			QTM_TOP_THERM_f_gpu_freq_trip0 {
				trip = <&QTM_TOP_THERM_f_trip_point0>;
				cooling-device = <&msm_gpu 4 4>;
			};

			QTM_TOP_THERM_f_backlight_trip0 {
				trip = <&QTM_TOP_THERM_f_trip_point0>;
				cooling-device = <&mdss_mdp 0 0>;
			};

			QTM_TOP_THERM_f_oem_chg_trip0 {
				trip = <&QTM_TOP_THERM_f_trip_point0>;
				cooling-device = <&oem_charger_drv 0 0>;
			};

			QTM_TOP_THERM_f_charger_trip0 {
				trip = <&QTM_TOP_THERM_f_trip_point0>;
				cooling-device = <&pm8150b_charger 0 0>;
			};

			QTM_TOP_THERM_f_mmw_skin0_trip0 {
				trip = <&QTM_TOP_THERM_f_trip_point0>;
				cooling-device = <&modem_mmw_skin0 (-1) 0>;
			};

			QTM_TOP_THERM_f_mmw_skin1_trip0 {
				trip = <&QTM_TOP_THERM_f_trip_point0>;
				cooling-device = <&modem_mmw_skin1 (-1) 0>;
			};

			QTM_TOP_THERM_f_mmw_skin2_trip0 {
				trip = <&QTM_TOP_THERM_f_trip_point0>;
				cooling-device = <&modem_mmw_skin2 (-1) 0>;
			};

			QTM_TOP_THERM_f_mmw_skin3_trip0 {
				trip = <&QTM_TOP_THERM_f_trip_point0>;
				cooling-device = <&modem_mmw_skin3 (-1) 0>;
			};

			QTM_TOP_THERM_f_modem_skin_trip0 {
				trip = <&QTM_TOP_THERM_f_trip_point0>;
				cooling-device = <&modem_skin (-1) 0>;
			};

			QTM_TOP_THERM_f_pa_trip0 {
				trip = <&QTM_TOP_THERM_f_trip_point0>;
				cooling-device = <&modem_pa (-1) 0>;
			};

			QTM_TOP_THERM_f_pa_fr1_trip0 {
				trip = <&QTM_TOP_THERM_f_trip_point0>;
				cooling-device = <&modem_pa_fr1 (-1) 0>;
			};
		};
	};

	QTM_RIGHT_THERM {
		polling-delay-passive = <1000>;
		polling-delay = <0>;
		thermal-governor = "step_wise";
		thermal-sensors = <&pm8150b_adc_tm 77>;
		wake-capable-sensor;

		trips {
			QTM_RIGHT_THERM_trip_point0: QTM_RIGHT_THERM_trip0 {
				temperature = <55000>;
				hysteresis = <1000>;
				type = "passive";
			};

			QTM_RIGHT_THERM_trip_point1: QTM_RIGHT_THERM_trip1 {
				temperature = <125000>;
				hysteresis = <1000>;
				type = "passive";
			};

			QTM_RIGHT_THERM_trip_point2: QTM_RIGHT_THERM_trip2 {
				temperature = <125000>;
				hysteresis = <1000>;
				type = "passive";
			};

			QTM_RIGHT_THERM_trip_point3: QTM_RIGHT_THERM_trip3 {
				temperature = <125000>;
				hysteresis = <1000>;
				type = "passive";
			};

			QTM_RIGHT_THERM_trip_point4: QTM_RIGHT_THERM_trip4 {
				temperature = <125000>;
				hysteresis = <1000>;
				type = "passive";
			};

			QTM_RIGHT_THERM_trip_point5: QTM_RIGHT_THERM_trip5 {
				temperature = <125000>;
				hysteresis = <1000>;
				type = "passive";
			};

			QTM_RIGHT_THERM_trip_point6: QTM_RIGHT_THERM_trip6 {
				temperature = <125000>;
				hysteresis = <1000>;
				type = "passive";
			};

			QTM_RIGHT_THERM_trip_point7: QTM_RIGHT_THERM_trip7 {
				temperature = <125000>;
				hysteresis = <1000>;
				type = "passive";
			};

			QTM_RIGHT_THERM_trip_point8: QTM_RIGHT_THERM_trip8 {
				temperature = <125000>;
				hysteresis = <1000>;
				type = "passive";
			};

			QTM_RIGHT_THERM_trip_point9: QTM_RIGHT_THERM_trip9 {
				temperature = <125000>;
				hysteresis = <1000>;
				type = "passive";
			};

			QTM_RIGHT_THERM_trip_point10: QTM_RIGHT_THERM_trip10 {
				temperature = <125000>;
				hysteresis = <1000>;
				type = "passive";
			};

			QTM_RIGHT_THERM_trip_point11: QTM_RIGHT_THERM_trip11 {
				temperature = <125000>;
				hysteresis = <1000>;
				type = "passive";
			};
		};

		cooling-maps {
			QTM_RIGHT_THERM_mmw_skin0_trip0 {
				trip = <&QTM_RIGHT_THERM_trip_point0>;
				cooling-device = <&modem_mmw_skin0 (-1) 2>;
			};

			QTM_RIGHT_THERM_mmw_skin1_trip0 {
				trip = <&QTM_RIGHT_THERM_trip_point0>;
				cooling-device = <&modem_mmw_skin1 (-1) 0>;
			};

			QTM_RIGHT_THERM_mmw_skin2_trip0 {
				trip = <&QTM_RIGHT_THERM_trip_point0>;
				cooling-device = <&modem_mmw_skin2 (-1) 0>;
			};

			QTM_RIGHT_THERM_mmw_skin3_trip0 {
				trip = <&QTM_RIGHT_THERM_trip_point0>;
				cooling-device = <&modem_mmw_skin3 (-1) 0>;
			};

			QTM_RIGHT_THERM_modem_skin_trip0 {
				trip = <&QTM_RIGHT_THERM_trip_point0>;
				cooling-device = <&modem_skin (-1) 0>;
			};

			QTM_RIGHT_THERM_pa_trip0 {
				trip = <&QTM_RIGHT_THERM_trip_point0>;
				cooling-device = <&modem_pa (-1) 0>;
			};

			QTM_RIGHT_THERM_pa_fr1_trip0 {
				trip = <&QTM_RIGHT_THERM_trip_point0>;
				cooling-device = <&modem_pa_fr1 (-1) 0>;
			};

			QTM_RIGHT_THERM_mmw_skin0_trip1 {
				trip = <&QTM_RIGHT_THERM_trip_point1>;
				cooling-device = <&modem_mmw_skin0 (-1) 3>;
			};

			QTM_RIGHT_THERM_mmw_skin1_trip1 {
				trip = <&QTM_RIGHT_THERM_trip_point1>;
				cooling-device = <&modem_mmw_skin1 (-1) 0>;
			};

			QTM_RIGHT_THERM_mmw_skin2_trip1 {
				trip = <&QTM_RIGHT_THERM_trip_point1>;
				cooling-device = <&modem_mmw_skin2 (-1) 0>;
			};

			QTM_RIGHT_THERM_mmw_skin3_trip1 {
				trip = <&QTM_RIGHT_THERM_trip_point1>;
				cooling-device = <&modem_mmw_skin3 (-1) 0>;
			};

			QTM_RIGHT_THERM_modem_skin_trip1 {
				trip = <&QTM_RIGHT_THERM_trip_point1>;
				cooling-device = <&modem_skin (-1) 0>;
			};

			QTM_RIGHT_THERM_pa_trip1 {
				trip = <&QTM_RIGHT_THERM_trip_point1>;
				cooling-device = <&modem_pa (-1) 0>;
			};

			QTM_RIGHT_THERM_pa_fr1_trip1 {
				trip = <&QTM_RIGHT_THERM_trip_point1>;
				cooling-device = <&modem_pa_fr1 (-1) 0>;
			};

			QTM_RIGHT_THERM_mmw_skin0_trip2 {
				trip = <&QTM_RIGHT_THERM_trip_point2>;
				cooling-device = <&modem_mmw_skin0 (-1) 3>;
			};

			QTM_RIGHT_THERM_mmw_skin1_trip2 {
				trip = <&QTM_RIGHT_THERM_trip_point2>;
				cooling-device = <&modem_mmw_skin1 (-1) 0>;
			};

			QTM_RIGHT_THERM_mmw_skin2_trip2 {
				trip = <&QTM_RIGHT_THERM_trip_point2>;
				cooling-device = <&modem_mmw_skin2 (-1) 0>;
			};

			QTM_RIGHT_THERM_mmw_skin3_trip2 {
				trip = <&QTM_RIGHT_THERM_trip_point2>;
				cooling-device = <&modem_mmw_skin3 (-1) 0>;
			};

			QTM_RIGHT_THERM_modem_skin_trip2 {
				trip = <&QTM_RIGHT_THERM_trip_point2>;
				cooling-device = <&modem_skin (-1) 0>;
			};

			QTM_RIGHT_THERM_pa_trip2 {
				trip = <&QTM_RIGHT_THERM_trip_point2>;
				cooling-device = <&modem_pa (-1) 0>;
			};

			QTM_RIGHT_THERM_pa_fr1_trip2 {
				trip = <&QTM_RIGHT_THERM_trip_point2>;
				cooling-device = <&modem_pa_fr1 (-1) 0>;
			};

			QTM_RIGHT_THERM_mmw_skin0_trip3 {
				trip = <&QTM_RIGHT_THERM_trip_point3>;
				cooling-device = <&modem_mmw_skin0 (-1) 3>;
			};

			QTM_RIGHT_THERM_mmw_skin1_trip3 {
				trip = <&QTM_RIGHT_THERM_trip_point3>;
				cooling-device = <&modem_mmw_skin1 (-1) 0>;
			};

			QTM_RIGHT_THERM_mmw_skin2_trip3 {
				trip = <&QTM_RIGHT_THERM_trip_point3>;
				cooling-device = <&modem_mmw_skin2 (-1) 0>;
			};

			QTM_RIGHT_THERM_mmw_skin3_trip3 {
				trip = <&QTM_RIGHT_THERM_trip_point3>;
				cooling-device = <&modem_mmw_skin3 (-1) 0>;
			};

			QTM_RIGHT_THERM_modem_skin_trip3 {
				trip = <&QTM_RIGHT_THERM_trip_point3>;
				cooling-device = <&modem_skin (-1) 0>;
			};

			QTM_RIGHT_THERM_pa_trip3 {
				trip = <&QTM_RIGHT_THERM_trip_point3>;
				cooling-device = <&modem_pa (-1) 0>;
			};

			QTM_RIGHT_THERM_pa_fr1_trip3 {
				trip = <&QTM_RIGHT_THERM_trip_point3>;
				cooling-device = <&modem_pa_fr1 (-1) 0>;
			};

			QTM_RIGHT_THERM_mmw_skin0_trip4 {
				trip = <&QTM_RIGHT_THERM_trip_point4>;
				cooling-device = <&modem_mmw_skin0 (-1) 3>;
			};

			QTM_RIGHT_THERM_mmw_skin1_trip4 {
				trip = <&QTM_RIGHT_THERM_trip_point4>;
				cooling-device = <&modem_mmw_skin1 (-1) 0>;
			};

			QTM_RIGHT_THERM_mmw_skin2_trip4 {
				trip = <&QTM_RIGHT_THERM_trip_point4>;
				cooling-device = <&modem_mmw_skin2 (-1) 0>;
			};

			QTM_RIGHT_THERM_mmw_skin3_trip4 {
				trip = <&QTM_RIGHT_THERM_trip_point4>;
				cooling-device = <&modem_mmw_skin3 (-1) 0>;
			};

			QTM_RIGHT_THERM_modem_skin_trip4 {
				trip = <&QTM_RIGHT_THERM_trip_point4>;
				cooling-device = <&modem_skin (-1) 0>;
			};

			QTM_RIGHT_THERM_pa_trip4 {
				trip = <&QTM_RIGHT_THERM_trip_point4>;
				cooling-device = <&modem_pa (-1) 0>;
			};

			QTM_RIGHT_THERM_pa_fr1_trip4 {
				trip = <&QTM_RIGHT_THERM_trip_point4>;
				cooling-device = <&modem_pa_fr1 (-1) 0>;
			};

			QTM_RIGHT_THERM_mmw_skin0_trip5 {
				trip = <&QTM_RIGHT_THERM_trip_point5>;
				cooling-device = <&modem_mmw_skin0 (-1) 3>;
			};

			QTM_RIGHT_THERM_mmw_skin1_trip5 {
				trip = <&QTM_RIGHT_THERM_trip_point5>;
				cooling-device = <&modem_mmw_skin1 (-1) 0>;
			};

			QTM_RIGHT_THERM_mmw_skin2_trip5 {
				trip = <&QTM_RIGHT_THERM_trip_point5>;
				cooling-device = <&modem_mmw_skin2 (-1) 0>;
			};

			QTM_RIGHT_THERM_mmw_skin3_trip5 {
				trip = <&QTM_RIGHT_THERM_trip_point5>;
				cooling-device = <&modem_mmw_skin3 (-1) 0>;
			};

			QTM_RIGHT_THERM_modem_skin_trip5 {
				trip = <&QTM_RIGHT_THERM_trip_point5>;
				cooling-device = <&modem_skin (-1) 0>;
			};

			QTM_RIGHT_THERM_pa_trip5 {
				trip = <&QTM_RIGHT_THERM_trip_point5>;
				cooling-device = <&modem_pa (-1) 0>;
			};

			QTM_RIGHT_THERM_pa_fr1_trip5 {
				trip = <&QTM_RIGHT_THERM_trip_point5>;
				cooling-device = <&modem_pa_fr1 (-1) 0>;
			};

			QTM_RIGHT_THERM_mmw_skin0_trip6 {
				trip = <&QTM_RIGHT_THERM_trip_point6>;
				cooling-device = <&modem_mmw_skin0 (-1) 3>;
			};

			QTM_RIGHT_THERM_mmw_skin1_trip6 {
				trip = <&QTM_RIGHT_THERM_trip_point6>;
				cooling-device = <&modem_mmw_skin1 (-1) 0>;
			};

			QTM_RIGHT_THERM_mmw_skin2_trip6 {
				trip = <&QTM_RIGHT_THERM_trip_point6>;
				cooling-device = <&modem_mmw_skin2 (-1) 0>;
			};

			QTM_RIGHT_THERM_mmw_skin3_trip6 {
				trip = <&QTM_RIGHT_THERM_trip_point6>;
				cooling-device = <&modem_mmw_skin3 (-1) 0>;
			};

			QTM_RIGHT_THERM_modem_skin_trip6 {
				trip = <&QTM_RIGHT_THERM_trip_point6>;
				cooling-device = <&modem_skin (-1) 0>;
			};

			QTM_RIGHT_THERM_pa_trip6 {
				trip = <&QTM_RIGHT_THERM_trip_point6>;
				cooling-device = <&modem_pa (-1) 0>;
			};

			QTM_RIGHT_THERM_pa_fr1_trip6 {
				trip = <&QTM_RIGHT_THERM_trip_point6>;
				cooling-device = <&modem_pa_fr1 (-1) 0>;
			};

			QTM_RIGHT_THERM_mmw_skin0_trip7 {
				trip = <&QTM_RIGHT_THERM_trip_point7>;
				cooling-device = <&modem_mmw_skin0 (-1) 3>;
			};

			QTM_RIGHT_THERM_mmw_skin1_trip7 {
				trip = <&QTM_RIGHT_THERM_trip_point7>;
				cooling-device = <&modem_mmw_skin1 (-1) 0>;
			};

			QTM_RIGHT_THERM_mmw_skin2_trip7 {
				trip = <&QTM_RIGHT_THERM_trip_point7>;
				cooling-device = <&modem_mmw_skin2 (-1) 0>;
			};

			QTM_RIGHT_THERM_mmw_skin3_trip7 {
				trip = <&QTM_RIGHT_THERM_trip_point7>;
				cooling-device = <&modem_mmw_skin3 (-1) 0>;
			};

			QTM_RIGHT_THERM_modem_skin_trip7 {
				trip = <&QTM_RIGHT_THERM_trip_point7>;
				cooling-device = <&modem_skin (-1) 0>;
			};

			QTM_RIGHT_THERM_pa_trip7 {
				trip = <&QTM_RIGHT_THERM_trip_point7>;
				cooling-device = <&modem_pa (-1) 0>;
			};

			QTM_RIGHT_THERM_pa_fr1_trip7 {
				trip = <&QTM_RIGHT_THERM_trip_point7>;
				cooling-device = <&modem_pa_fr1 (-1) 0>;
			};

			QTM_RIGHT_THERM_mmw_skin0_trip8 {
				trip = <&QTM_RIGHT_THERM_trip_point8>;
				cooling-device = <&modem_mmw_skin0 (-1) 3>;
			};

			QTM_RIGHT_THERM_mmw_skin1_trip8 {
				trip = <&QTM_RIGHT_THERM_trip_point8>;
				cooling-device = <&modem_mmw_skin1 (-1) 0>;
			};

			QTM_RIGHT_THERM_mmw_skin2_trip8 {
				trip = <&QTM_RIGHT_THERM_trip_point8>;
				cooling-device = <&modem_mmw_skin2 (-1) 0>;
			};

			QTM_RIGHT_THERM_mmw_skin3_trip8 {
				trip = <&QTM_RIGHT_THERM_trip_point8>;
				cooling-device = <&modem_mmw_skin3 (-1) 0>;
			};

			QTM_RIGHT_THERM_modem_skin_trip8 {
				trip = <&QTM_RIGHT_THERM_trip_point8>;
				cooling-device = <&modem_skin (-1) 0>;
			};

			QTM_RIGHT_THERM_pa_trip8 {
				trip = <&QTM_RIGHT_THERM_trip_point8>;
				cooling-device = <&modem_pa (-1) 0>;
			};

			QTM_RIGHT_THERM_pa_fr1_trip8 {
				trip = <&QTM_RIGHT_THERM_trip_point8>;
				cooling-device = <&modem_pa_fr1 (-1) 0>;
			};

			QTM_RIGHT_THERM_mmw_skin0_trip9 {
				trip = <&QTM_RIGHT_THERM_trip_point9>;
				cooling-device = <&modem_mmw_skin0 (-1) 3>;
			};

			QTM_RIGHT_THERM_mmw_skin1_trip9 {
				trip = <&QTM_RIGHT_THERM_trip_point9>;
				cooling-device = <&modem_mmw_skin1 (-1) 0>;
			};

			QTM_RIGHT_THERM_mmw_skin2_trip9 {
				trip = <&QTM_RIGHT_THERM_trip_point9>;
				cooling-device = <&modem_mmw_skin2 (-1) 0>;
			};

			QTM_RIGHT_THERM_mmw_skin3_trip9 {
				trip = <&QTM_RIGHT_THERM_trip_point9>;
				cooling-device = <&modem_mmw_skin3 (-1) 0>;
			};

			QTM_RIGHT_THERM_modem_skin_trip9 {
				trip = <&QTM_RIGHT_THERM_trip_point9>;
				cooling-device = <&modem_skin (-1) 0>;
			};

			QTM_RIGHT_THERM_pa_trip9 {
				trip = <&QTM_RIGHT_THERM_trip_point9>;
				cooling-device = <&modem_pa (-1) 0>;
			};

			QTM_RIGHT_THERM_pa_fr1_trip9 {
				trip = <&QTM_RIGHT_THERM_trip_point9>;
				cooling-device = <&modem_pa_fr1 (-1) 0>;
			};

			QTM_RIGHT_THERM_mmw_skin0_trip10 {
				trip = <&QTM_RIGHT_THERM_trip_point10>;
				cooling-device = <&modem_mmw_skin0 (-1) 3>;
			};

			QTM_RIGHT_THERM_mmw_skin1_trip10 {
				trip = <&QTM_RIGHT_THERM_trip_point10>;
				cooling-device = <&modem_mmw_skin1 (-1) 0>;
			};

			QTM_RIGHT_THERM_mmw_skin2_trip10 {
				trip = <&QTM_RIGHT_THERM_trip_point10>;
				cooling-device = <&modem_mmw_skin2 (-1) 0>;
			};

			QTM_RIGHT_THERM_mmw_skin3_trip10 {
				trip = <&QTM_RIGHT_THERM_trip_point10>;
				cooling-device = <&modem_mmw_skin3 (-1) 0>;
			};

			QTM_RIGHT_THERM_modem_skin_trip10 {
				trip = <&QTM_RIGHT_THERM_trip_point10>;
				cooling-device = <&modem_skin (-1) 0>;
			};

			QTM_RIGHT_THERM_pa_trip10 {
				trip = <&QTM_RIGHT_THERM_trip_point10>;
				cooling-device = <&modem_pa (-1) 0>;
			};

			QTM_RIGHT_THERM_pa_fr1_trip10 {
				trip = <&QTM_RIGHT_THERM_trip_point10>;
				cooling-device = <&modem_pa_fr1 (-1) 0>;
			};

			QTM_RIGHT_THERM_mmw_skin0_trip11 {
				trip = <&QTM_RIGHT_THERM_trip_point11>;
				cooling-device = <&modem_mmw_skin0 (-1) 3>;
			};

			QTM_RIGHT_THERM_mmw_skin1_trip11 {
				trip = <&QTM_RIGHT_THERM_trip_point11>;
				cooling-device = <&modem_mmw_skin1 (-1) 0>;
			};

			QTM_RIGHT_THERM_mmw_skin2_trip11 {
				trip = <&QTM_RIGHT_THERM_trip_point11>;
				cooling-device = <&modem_mmw_skin2 (-1) 0>;
			};

			QTM_RIGHT_THERM_mmw_skin3_trip11 {
				trip = <&QTM_RIGHT_THERM_trip_point11>;
				cooling-device = <&modem_mmw_skin3 (-1) 0>;
			};

			QTM_RIGHT_THERM_modem_skin_trip11 {
				trip = <&QTM_RIGHT_THERM_trip_point11>;
				cooling-device = <&modem_skin (-1) 0>;
			};

			QTM_RIGHT_THERM_pa_trip11 {
				trip = <&QTM_RIGHT_THERM_trip_point11>;
				cooling-device = <&modem_pa (-1) 0>;
			};

			QTM_RIGHT_THERM_pa_fr1_trip11 {
				trip = <&QTM_RIGHT_THERM_trip_point11>;
				cooling-device = <&modem_pa_fr1 (-1) 0>;
			};
		};
	};

	QTM_RIGHT_THERM_f {
		polling-delay-passive = <1000>;
		polling-delay = <0>;
		thermal-governor = "low_limits_cap";
		thermal-sensors = <&pm8150b_adc_tm 77>;
		wake-capable-sensor;

		trips {
			QTM_RIGHT_THERM_f_trip_point0: QTM_RIGHT_THERM_f_trip0 {
				temperature = <(-30000)>;
				hysteresis = <0>;
				type = "passive";
			};
		};

		cooling-maps {
			QTM_RIGHT_THERM_f_cpu0_freq_trip0 {
				trip = <&QTM_RIGHT_THERM_f_trip_point0>;
				cooling-device = <&CPU0 (-1) 0>;
			};

			QTM_RIGHT_THERM_f_cpu4_freq_trip0 {
				trip = <&QTM_RIGHT_THERM_f_trip_point0>;
				cooling-device = <&CPU4 (-1) 0>;
			};

			QTM_RIGHT_THERM_f_cpu7_freq_trip0 {
				trip = <&QTM_RIGHT_THERM_f_trip_point0>;
				cooling-device = <&CPU7 (-1) 0>;
			};

			QTM_RIGHT_THERM_f_cpu0_isolate_trip0 {
				trip = <&QTM_RIGHT_THERM_f_trip_point0>;
				cooling-device = <&cpu0_isolate 0 0>;
			};

			QTM_RIGHT_THERM_f_cpu1_isolate_trip0 {
				trip = <&QTM_RIGHT_THERM_f_trip_point0>;
				cooling-device = <&cpu1_isolate 0 0>;
			};

			QTM_RIGHT_THERM_f_cpu2_isolate_trip0 {
				trip = <&QTM_RIGHT_THERM_f_trip_point0>;
				cooling-device = <&cpu2_isolate 0 0>;
			};

			QTM_RIGHT_THERM_f_cpu3_isolate_trip0 {
				trip = <&QTM_RIGHT_THERM_f_trip_point0>;
				cooling-device = <&cpu3_isolate 0 0>;
			};

			QTM_RIGHT_THERM_f_cpu4_isolate_trip0 {
				trip = <&QTM_RIGHT_THERM_f_trip_point0>;
				cooling-device = <&cpu4_isolate 1 1>;
			};

			QTM_RIGHT_THERM_f_cpu5_isolate_trip0 {
				trip = <&QTM_RIGHT_THERM_f_trip_point0>;
				cooling-device = <&cpu5_isolate 1 1>;
			};

			QTM_RIGHT_THERM_f_cpu6_isolate_trip0 {
				trip = <&QTM_RIGHT_THERM_f_trip_point0>;
				cooling-device = <&cpu6_isolate 1 1>;
			};

			QTM_RIGHT_THERM_f_cpu7_isolate_trip0 {
				trip = <&QTM_RIGHT_THERM_f_trip_point0>;
				cooling-device = <&cpu7_isolate 1 1>;
			};

			QTM_RIGHT_THERM_f_gpu_freq_trip0 {
				trip = <&QTM_RIGHT_THERM_f_trip_point0>;
				cooling-device = <&msm_gpu 4 4>;
			};

			QTM_RIGHT_THERM_f_backlight_trip0 {
				trip = <&QTM_RIGHT_THERM_f_trip_point0>;
				cooling-device = <&mdss_mdp 0 0>;
			};

			QTM_RIGHT_THERM_f_oem_chg_trip0 {
				trip = <&QTM_RIGHT_THERM_f_trip_point0>;
				cooling-device = <&oem_charger_drv 0 0>;
			};

			QTM_RIGHT_THERM_f_charger_trip0 {
				trip = <&QTM_RIGHT_THERM_f_trip_point0>;
				cooling-device = <&pm8150b_charger 0 0>;
			};

			QTM_RIGHT_THERM_f_mmw_skin0_trip0 {
				trip = <&QTM_RIGHT_THERM_f_trip_point0>;
				cooling-device = <&modem_mmw_skin0 (-1) 0>;
			};

			QTM_RIGHT_THERM_f_mmw_skin1_trip0 {
				trip = <&QTM_RIGHT_THERM_f_trip_point0>;
				cooling-device = <&modem_mmw_skin1 (-1) 0>;
			};

			QTM_RIGHT_THERM_f_mmw_skin2_trip0 {
				trip = <&QTM_RIGHT_THERM_f_trip_point0>;
				cooling-device = <&modem_mmw_skin2 (-1) 0>;
			};

			QTM_RIGHT_THERM_f_mmw_skin3_trip0 {
				trip = <&QTM_RIGHT_THERM_f_trip_point0>;
				cooling-device = <&modem_mmw_skin3 (-1) 0>;
			};

			QTM_RIGHT_THERM_f_modem_skin_trip0 {
				trip = <&QTM_RIGHT_THERM_f_trip_point0>;
				cooling-device = <&modem_skin (-1) 0>;
			};

			QTM_RIGHT_THERM_f_pa_trip0 {
				trip = <&QTM_RIGHT_THERM_f_trip_point0>;
				cooling-device = <&modem_pa (-1) 0>;
			};

			QTM_RIGHT_THERM_f_pa_fr1_trip0 {
				trip = <&QTM_RIGHT_THERM_f_trip_point0>;
				cooling-device = <&modem_pa_fr1 (-1) 0>;
			};
		};
	};

	failure-det-min-usr {
		polling-delay-passive = <0>;
		polling-delay = <300000>;
		thermal-governor = "user_space";
		wake-capable-sensor;

		trips {
			failure-det-min-virt-trip {
				temperature = <125000>;
				hysteresis = <1000>;
				type = "passive";
			};
		};
	};

	skin-msm-therm2-usr {
		polling-delay-passive = <0>;
		polling-delay = <0>;
		thermal-governor = "user_space";
		thermal-sensors = <&pm8150l_adc_tm 78>;
		wake-capable-sensor;

		trips {
			active-config0 {
				temperature = <125000>;
				hysteresis = <1000>;
				type = "passive";
			};
		};
	};
};
